VERSION ""

NS_ :

BS_:

BU_: RRSRR_FO LRSRR_FO CIPM_FO _DOFIMU2_FO _DOFIMU1_FO DMS_FO AMM_FO EOCM2B_IMX6_FO EOCM2B_K2_FO EOCM2B_K1_FO EOCM2A_IMX6_FO EOCM2A_K2_FO EOCM2A_K1_FO NVS_FO Dummy_FO TestTool_FO LRR_FO RFSRR_FO LFSRR_FO RSRR_FO VIS_FO EOCM_F_FO VIS2_FO

BO_ 774 F_Vehicle_Path_Estimate: 8 EOCM_F_FO
 SG_ Vpath_RollingCount : 7|2@0+ (1,0) [0|3] ""  CIPM_FO,AMM_FO,EOCM2B_IMX6_FO,EOCM2B_K2_FO,EOCM2B_K1_FO,VIS2_FO,RRSRR_FO,VIS_FO,RSRR_FO,RFSRR_FO,LRR_FO,LFSRR_FO
 SG_ Vpath_TrnCtrLngOfstV : 1|1@0+ (1,0) [0|1] ""  CIPM_FO,AMM_FO,EOCM2B_IMX6_FO,EOCM2B_K2_FO,EOCM2B_K1_FO,VIS2_FO,RRSRR_FO,LRR_FO,VIS_FO,RSRR_FO,RFSRR_FO,LFSRR_FO
 SG_ Vpath_Checksum : 50|11@0+ (1,0) [0|2047] ""  CIPM_FO,AMM_FO,EOCM2B_IMX6_FO,EOCM2B_K2_FO,EOCM2B_K1_FO,VIS2_FO,RRSRR_FO,VIS_FO,RSRR_FO,RFSRR_FO,LRR_FO,LFSRR_FO
 SG_ Vpath_TrnCtrLngOfst : 15|8@0- (0.1,0) [-12.8|12.7] "m"  CIPM_FO,AMM_FO,EOCM2B_IMX6_FO,EOCM2B_K2_FO,EOCM2B_K1_FO,VIS2_FO,RRSRR_FO,LRR_FO,VIS_FO,RSRR_FO,RFSRR_FO,LFSRR_FO
 SG_ Vpath_TrnCtrLatOfst : 21|14@0- (1,0) [-8192|8191] "m"  CIPM_FO,AMM_FO,EOCM2B_IMX6_FO,EOCM2B_K2_FO,EOCM2B_K1_FO,VIS2_FO,RRSRR_FO,LRR_FO,VIS_FO,RSRR_FO,RFSRR_FO,LFSRR_FO
 SG_ Vpath_Curvature : 39|16@0- (1E-005,0) [-0.32768|0.32767] "1/m"  CIPM_FO,AMM_FO,EOCM2B_IMX6_FO,EOCM2B_K2_FO,EOCM2B_K1_FO,VIS2_FO,RRSRR_FO,VIS_FO,RSRR_FO,RFSRR_FO,LRR_FO,LFSRR_FO
 SG_ Vpath_CurvatureV : 0|1@0+ (1,0) [0|1] ""  CIPM_FO,AMM_FO,EOCM2B_IMX6_FO,EOCM2B_K2_FO,EOCM2B_K1_FO,VIS2_FO,RRSRR_FO,VIS_FO,LRR_FO,RSRR_FO,RFSRR_FO,LFSRR_FO

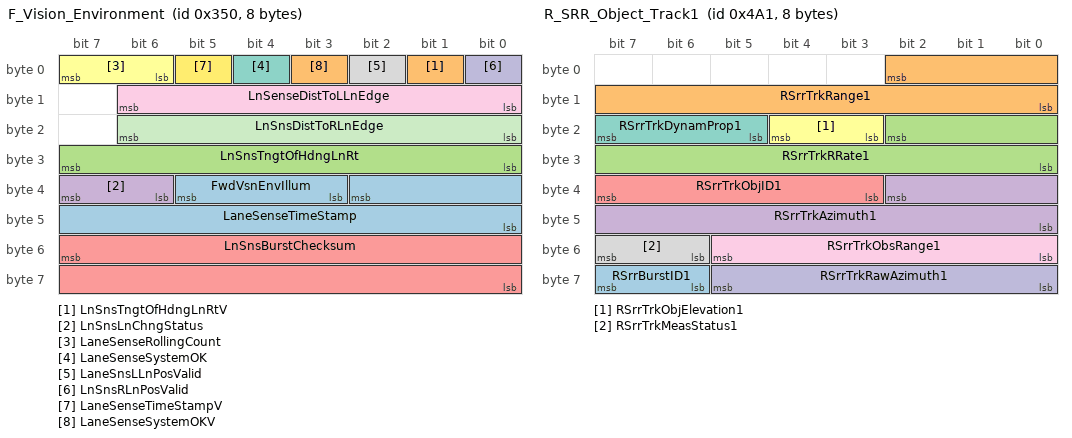
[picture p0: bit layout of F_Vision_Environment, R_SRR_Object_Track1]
BO_ 848 F_Vision_Environment: 8 VIS_FO
 SG_ FwdVsnEnvIllum : 37|3@0+ (1,0) [0|7] ""  EOCM2A_IMX6_FO,EOCM2A_K2_FO,EOCM2A_K1_FO,EOCM2B_IMX6_FO,EOCM2B_K2_FO,EOCM2B_K1_FO,EOCM_F_FO
 SG_ LnSnsTngtOfHdngLnRtV : 1|1@0+ (1,0) [0|1] ""  EOCM2A_IMX6_FO,EOCM2A_K2_FO,EOCM2A_K1_FO,EOCM2B_IMX6_FO,EOCM2B_K2_FO,EOCM2B_K1_FO,EOCM_F_FO
 SG_ LnSnsTngtOfHdngLnRt : 31|8@0- (0.002,0) [-0.256|0.254] "m/m"  EOCM2A_IMX6_FO,EOCM2A_K2_FO,EOCM2A_K1_FO,EOCM2B_IMX6_FO,EOCM2B_K2_FO,EOCM2B_K1_FO,EOCM_F_FO
 SG_ LnSnsLnChngStatus : 39|2@0+ (1,0) [0|3] ""  EOCM2A_IMX6_FO,EOCM2A_K2_FO,EOCM2A_K1_FO,EOCM2B_IMX6_FO,EOCM2B_K2_FO,EOCM2B_K1_FO,EOCM_F_FO
 SG_ LnSnsBurstChecksum : 55|16@0+ (1,0) [0|65535] ""  EOCM2A_IMX6_FO,EOCM2A_K2_FO,EOCM2A_K1_FO,EOCM2B_IMX6_FO,EOCM2B_K2_FO,EOCM2B_K1_FO,EOCM_F_FO
 SG_ LaneSenseRollingCount : 7|2@0+ (1,0) [0|3] ""  EOCM2A_IMX6_FO,EOCM2A_K2_FO,EOCM2A_K1_FO,EOCM2B_IMX6_FO,EOCM2B_K2_FO,EOCM2B_K1_FO,EOCM_F_FO
 SG_ LaneSenseSystemOK : 4|1@0+ (1,0) [0|1] ""  EOCM2A_IMX6_FO,EOCM2A_K2_FO,EOCM2A_K1_FO,EOCM2B_IMX6_FO,EOCM2B_K2_FO,EOCM2B_K1_FO,EOCM_F_FO
 SG_ LaneSnsLLnPosValid : 2|1@0+ (1,0) [0|1] ""  EOCM2A_IMX6_FO,EOCM2A_K2_FO,EOCM2A_K1_FO,EOCM2B_IMX6_FO,EOCM2B_K2_FO,EOCM2B_K1_FO,EOCM_F_FO
 SG_ LnSenseDistToLLnEdge : 14|7@0+ (0.05,0) [0|6.35] "m"  EOCM2A_IMX6_FO,EOCM2A_K2_FO,EOCM2A_K1_FO,EOCM2B_IMX6_FO,EOCM2B_K2_FO,EOCM2B_K1_FO,EOCM_F_FO
 SG_ LnSnsRLnPosValid : 0|1@0+ (1,0) [0|1] ""  EOCM2A_IMX6_FO,EOCM2A_K2_FO,EOCM2A_K1_FO,EOCM2B_IMX6_FO,EOCM2B_K2_FO,EOCM2B_K1_FO,EOCM_F_FO
 SG_ LnSnsDistToRLnEdge : 22|7@0+ (0.05,0) [0|6.35] "m"  EOCM2A_IMX6_FO,EOCM2A_K2_FO,EOCM2A_K1_FO,EOCM2B_IMX6_FO,EOCM2B_K2_FO,EOCM2B_K1_FO,EOCM_F_FO
 SG_ LaneSenseTimeStampV : 5|1@0+ (1,0) [0|1] ""  EOCM2A_IMX6_FO,EOCM2A_K2_FO,EOCM2A_K1_FO,EOCM2B_IMX6_FO,EOCM2B_K2_FO,EOCM2B_K1_FO,EOCM_F_FO
 SG_ LaneSenseTimeStamp : 34|11@0+ (1,0) [0|2047] "ms"  EOCM2A_IMX6_FO,EOCM2A_K2_FO,EOCM2A_K1_FO,EOCM2B_IMX6_FO,EOCM2B_K2_FO,EOCM2B_K1_FO,EOCM_F_FO
 SG_ LaneSenseSystemOKV : 3|1@0+ (1,0) [0|1] ""  EOCM2A_IMX6_FO,EOCM2A_K2_FO,EOCM2A_K1_FO,EOCM2B_IMX6_FO,EOCM2B_K2_FO,EOCM2B_K1_FO,EOCM_F_FO

BO_ 849 F_Vision_Environment_2: 8 VIS_FO
 SG_ LnSnsLatVRelToRgtMrkg : 23|8@0- (0.02,0) [-2.56|2.54] "m/s"  EOCM2A_IMX6_FO,EOCM2A_K2_FO,EOCM2A_K1_FO,EOCM_F_FO,EOCM2B_IMX6_FO,EOCM2B_K2_FO,EOCM2B_K1_FO
 SG_ LnSnsRtLnMrkgTypChgDst : 61|4@0+ (10,0) [0|150] "m"  EOCM2A_IMX6_FO,EOCM2A_K2_FO,EOCM2A_K1_FO,EOCM2B_IMX6_FO,EOCM2B_K2_FO,EOCM2B_K1_FO,EOCM_F_FO
 SG_ LnSnsCrvtGrdntRtV : 63|1@0+ (1,0) [0|1] ""  EOCM2A_IMX6_FO,EOCM2A_K2_FO,EOCM2A_K1_FO,EOCM2B_IMX6_FO,EOCM2B_K2_FO,EOCM2B_K1_FO,EOCM_F_FO
 SG_ LnSnsLnMrkgWdthRt : 62|1@0+ (1,0) [0|1] ""  EOCM2A_IMX6_FO,EOCM2A_K2_FO,EOCM2A_K1_FO,EOCM2B_IMX6_FO,EOCM2B_K2_FO,EOCM2B_K1_FO,EOCM_F_FO
 SG_ LnSnsRtAnchrLn : 57|1@0+ (1,0) [0|1] ""  EOCM2A_IMX6_FO,EOCM2A_K2_FO,EOCM2A_K1_FO,EOCM2B_IMX6_FO,EOCM2B_K2_FO,EOCM2B_K1_FO,EOCM_F_FO
 SG_ LnSnsLtAnchrLn : 56|1@0+ (1,0) [0|1] ""  EOCM2A_IMX6_FO,EOCM2A_K2_FO,EOCM2A_K1_FO,EOCM2B_IMX6_FO,EOCM2B_K2_FO,EOCM2B_K1_FO,EOCM_F_FO
 SG_ LnSnsLnCrvtrRghtV : 0|1@0+ (1,0) [0|1] ""  EOCM2A_IMX6_FO,EOCM2A_K2_FO,EOCM2A_K1_FO,EOCM2B_IMX6_FO,EOCM2B_K2_FO,EOCM2B_K1_FO,EOCM_F_FO
 SG_ LnSnsLnCrvtrRght : 47|16@0- (9.53E-007,0) [-0.031227904|0.031226951] "1/m"  EOCM2A_IMX6_FO,EOCM2A_K2_FO,EOCM2A_K1_FO,EOCM2B_IMX6_FO,EOCM2B_K2_FO,EOCM2B_K1_FO,EOCM_F_FO
 SG_ LnSnsCrvtGrdntRt : 31|16@0- (5.96E-008,0) [-0.0019529728|0.0019529132] "1/rad/s"  EOCM2A_IMX6_FO,EOCM2A_K2_FO,EOCM2A_K1_FO,EOCM2B_IMX6_FO,EOCM2B_K2_FO,EOCM2B_K1_FO,EOCM_F_FO
 SG_ LnSnsBurstID : 2|2@0+ (1,0) [0|3] ""  EOCM2A_IMX6_FO,EOCM2A_K2_FO,EOCM2A_K1_FO,EOCM2B_IMX6_FO,EOCM2B_K2_FO,EOCM2B_K1_FO,EOCM_F_FO
 SG_ LnSnsLatVRelToLftMrkg : 15|8@0- (0.02,0) [-2.56|2.54] "m/s"  EOCM2A_IMX6_FO,EOCM2A_K2_FO,EOCM2A_K1_FO,EOCM2B_IMX6_FO,EOCM2B_K2_FO,EOCM2B_K1_FO,EOCM_F_FO

BO_ 1184 R_SRR_Object_Header: 8 RSRR_FO
 SG_ RSRRNumValidTargets : 14|4@0+ (1,0) [0|15] ""  EOCM_F_FO
 SG_ RSrrRollingCnt : 1|2@0+ (1,0) [0|3] ""  EOCM_F_FO
 SG_ RSRRModeCmdFdbk : 4|3@0+ (1,0) [0|7] ""  EOCM_F_FO
 SG_ RSrrTimeStampV : 15|1@0+ (1,0) [0|1] ""  EOCM_F_FO
 SG_ RSrrTimeStamp : 10|11@0+ (1,0) [0|2047] "ms"  EOCM_F_FO
 SG_ RSrrBurstChecksum : 55|16@0+ (1,0) [0|65535] ""  EOCM_F_FO
 SG_ RSRRSnstvFltPrsntInt : 24|1@0+ (1,0) [0|1] ""  EOCM_F_FO
 SG_ RSRRPlntAlgnInProc : 37|1@0+ (1,0) [0|1] ""  EOCM_F_FO
 SG_ RSRRMsalgnYawRt : 47|1@0+ (1,0) [0|1] ""  EOCM_F_FO
 SG_ RSRRMsalgnYawLt : 46|1@0+ (1,0) [0|1] ""  EOCM_F_FO
 SG_ RSRRMsalgnRllRt : 35|1@0+ (1,0) [0|1] ""  EOCM_F_FO
 SG_ RSRRMsalgnRllLt : 34|1@0+ (1,0) [0|1] ""  EOCM_F_FO
 SG_ RSRRMsalgnPtchUp : 32|1@0+ (1,0) [0|1] ""  EOCM_F_FO
 SG_ RSRRMsalgnPtchDn : 33|1@0+ (1,0) [0|1] ""  EOCM_F_FO
 SG_ RSRRInitDiagCmplt : 40|1@0+ (1,0) [0|1] ""  EOCM_F_FO
 SG_ RSRRHWFltPrsntInt : 25|1@0+ (1,0) [0|1] ""  EOCM_F_FO
 SG_ RSRRExtIntrfrnc : 36|1@0+ (1,0) [0|1] ""  EOCM_F_FO
 SG_ RSRRDiagSpare : 30|1@0+ (1,0) [0|1] ""  EOCM_F_FO
 SG_ RSRRCANSgnlSpvFld : 29|1@0+ (1,0) [0|1] ""  EOCM_F_FO
 SG_ RSRRCANRxErr : 28|1@0+ (1,0) [0|1] ""  EOCM_F_FO
 SG_ RSRRCANIDAddrsUnsbl : 27|1@0+ (1,0) [0|1] ""  EOCM_F_FO
 SG_ RSRRAntTngFltPrsnt : 26|1@0+ (1,0) [0|1] ""  EOCM_F_FO
 SG_ RSRRAmbTmpOutRngLw : 42|1@0+ (1,0) [0|1] ""  EOCM_F_FO
 SG_ RSRRAmbTmpOutRngHi : 41|1@0+ (1,0) [0|1] ""  EOCM_F_FO
 SG_ RSRRAlgnFltPrsnt : 39|1@0+ (1,0) [0|1] ""  EOCM_F_FO
 SG_ RSRRVltgOutRngLo : 44|1@0+ (1,0) [0|1] ""  EOCM_F_FO
 SG_ RSRRVltgOutRngHi : 43|1@0+ (1,0) [0|1] ""  EOCM_F_FO
 SG_ RSRRSvcAlgnInPrcs : 38|1@0+ (1,0) [0|1] ""  EOCM_F_FO
 SG_ RSRRSnsrBlckd : 45|1@0+ (1,0) [0|1] ""  EOCM_F_FO

BO_ 1185 R_SRR_Object_Track1: 8 RSRR_FO
 SG_ RSrrBurstID1 : 63|2@0+ (1,0) [0|3] ""  EOCM_F_FO
 SG_ RSrrTrkRange1 : 2|11@0+ (0.02,0) [0|40.94] "m"  EOCM_F_FO
 SG_ RSrrTrkRRate1 : 18|11@0- (0.125,0) [-128|127.875] "m/s"  EOCM_F_FO
 SG_ RSrrTrkAzimuth1 : 34|11@0- (0.125,0) [-128|127.875] "deg"  EOCM_F_FO
 SG_ RSrrTrkObjID1 : 39|5@0+ (1,0) [0|31] ""  EOCM_F_FO
 SG_ RSrrTrkObjElevation1 : 20|2@0+ (1,0) [0|3] ""  EOCM_F_FO
 SG_ RSrrTrkDynamProp1 : 23|3@0+ (1,0) [0|7] ""  EOCM_F_FO
 SG_ RSrrTrkMeasStatus1 : 55|2@0+ (1,0) [0|3] ""  EOCM_F_FO
 SG_ RSrrTrkObsRange1 : 53|6@0- (0.02,0) [-0.64|0.62] "m"  EOCM_F_FO
 SG_ RSrrTrkRawAzimuth1 : 61|6@0- (1,0) [-32|31] "deg"  EOCM_F_FO

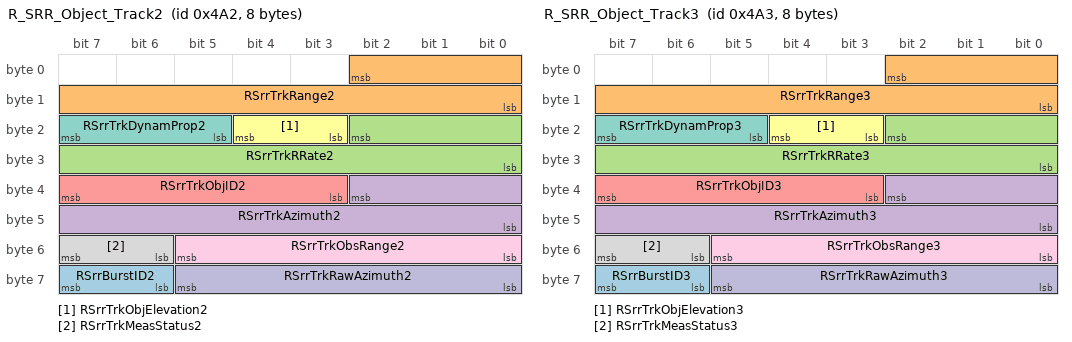
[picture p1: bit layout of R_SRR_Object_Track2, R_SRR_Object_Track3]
BO_ 1186 R_SRR_Object_Track2: 8 RSRR_FO
 SG_ RSrrBurstID2 : 63|2@0+ (1,0) [0|3] ""  EOCM_F_FO
 SG_ RSrrTrkRange2 : 2|11@0+ (0.02,0) [0|40.94] "m"  EOCM_F_FO
 SG_ RSrrTrkRRate2 : 18|11@0- (0.125,0) [-128|127.875] "m/s"  EOCM_F_FO
 SG_ RSrrTrkAzimuth2 : 34|11@0- (0.125,0) [-128|127.875] "deg"  EOCM_F_FO
 SG_ RSrrTrkObjID2 : 39|5@0+ (1,0) [0|31] ""  EOCM_F_FO
 SG_ RSrrTrkObjElevation2 : 20|2@0+ (1,0) [0|3] ""  EOCM_F_FO
 SG_ RSrrTrkDynamProp2 : 23|3@0+ (1,0) [0|7] ""  EOCM_F_FO
 SG_ RSrrTrkMeasStatus2 : 55|2@0+ (1,0) [0|3] ""  EOCM_F_FO
 SG_ RSrrTrkObsRange2 : 53|6@0- (0.02,0) [-0.64|0.62] "m"  EOCM_F_FO
 SG_ RSrrTrkRawAzimuth2 : 61|6@0- (1,0) [-32|31] "deg"  EOCM_F_FO

BO_ 1187 R_SRR_Object_Track3: 8 RSRR_FO
 SG_ RSrrBurstID3 : 63|2@0+ (1,0) [0|3] ""  EOCM_F_FO
 SG_ RSrrTrkRange3 : 2|11@0+ (0.02,0) [0|40.94] "m"  EOCM_F_FO
 SG_ RSrrTrkRRate3 : 18|11@0- (0.125,0) [-128|127.875] "m/s"  EOCM_F_FO
 SG_ RSrrTrkAzimuth3 : 34|11@0- (0.125,0) [-128|127.875] "deg"  EOCM_F_FO
 SG_ RSrrTrkObjID3 : 39|5@0+ (1,0) [0|31] ""  EOCM_F_FO
 SG_ RSrrTrkObjElevation3 : 20|2@0+ (1,0) [0|3] ""  EOCM_F_FO
 SG_ RSrrTrkDynamProp3 : 23|3@0+ (1,0) [0|7] ""  EOCM_F_FO
 SG_ RSrrTrkMeasStatus3 : 55|2@0+ (1,0) [0|3] ""  EOCM_F_FO
 SG_ RSrrTrkObsRange3 : 53|6@0- (0.02,0) [-0.64|0.62] "m"  EOCM_F_FO
 SG_ RSrrTrkRawAzimuth3 : 61|6@0- (1,0) [-32|31] "deg"  EOCM_F_FO

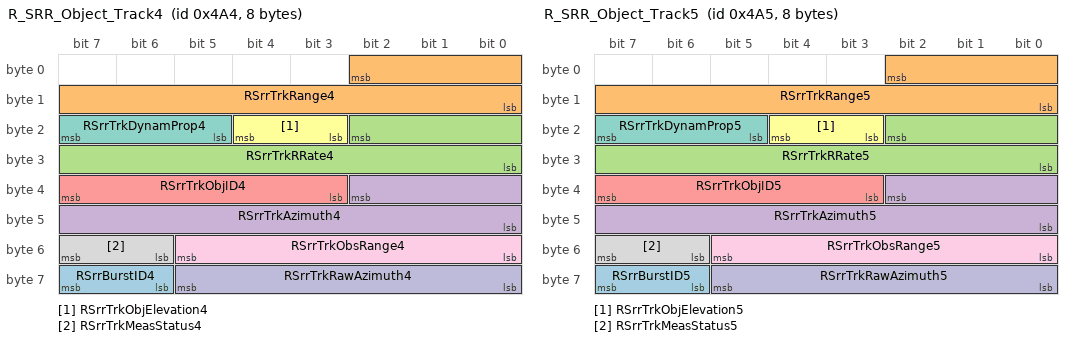
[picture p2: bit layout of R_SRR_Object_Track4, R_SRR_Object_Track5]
BO_ 1188 R_SRR_Object_Track4: 8 RSRR_FO
 SG_ RSrrBurstID4 : 63|2@0+ (1,0) [0|3] ""  EOCM_F_FO
 SG_ RSrrTrkRange4 : 2|11@0+ (0.02,0) [0|40.94] "m"  EOCM_F_FO
 SG_ RSrrTrkRRate4 : 18|11@0- (0.125,0) [-128|127.875] "m/s"  EOCM_F_FO
 SG_ RSrrTrkAzimuth4 : 34|11@0- (0.125,0) [-128|127.875] "deg"  EOCM_F_FO
 SG_ RSrrTrkObjID4 : 39|5@0+ (1,0) [0|31] ""  EOCM_F_FO
 SG_ RSrrTrkObjElevation4 : 20|2@0+ (1,0) [0|3] ""  EOCM_F_FO
 SG_ RSrrTrkDynamProp4 : 23|3@0+ (1,0) [0|7] ""  EOCM_F_FO
 SG_ RSrrTrkMeasStatus4 : 55|2@0+ (1,0) [0|3] ""  EOCM_F_FO
 SG_ RSrrTrkObsRange4 : 53|6@0- (0.02,0) [-0.64|0.62] "m"  EOCM_F_FO
 SG_ RSrrTrkRawAzimuth4 : 61|6@0- (1,0) [-32|31] "deg"  EOCM_F_FO

BO_ 1189 R_SRR_Object_Track5: 8 RSRR_FO
 SG_ RSrrBurstID5 : 63|2@0+ (1,0) [0|3] ""  EOCM_F_FO
 SG_ RSrrTrkRange5 : 2|11@0+ (0.02,0) [0|40.94] "m"  EOCM_F_FO
 SG_ RSrrTrkRRate5 : 18|11@0- (0.125,0) [-128|127.875] "m/s"  EOCM_F_FO
 SG_ RSrrTrkAzimuth5 : 34|11@0- (0.125,0) [-128|127.875] "deg"  EOCM_F_FO
 SG_ RSrrTrkObjID5 : 39|5@0+ (1,0) [0|31] ""  EOCM_F_FO
 SG_ RSrrTrkObjElevation5 : 20|2@0+ (1,0) [0|3] ""  EOCM_F_FO
 SG_ RSrrTrkDynamProp5 : 23|3@0+ (1,0) [0|7] ""  EOCM_F_FO
 SG_ RSrrTrkMeasStatus5 : 55|2@0+ (1,0) [0|3] ""  EOCM_F_FO
 SG_ RSrrTrkObsRange5 : 53|6@0- (0.02,0) [-0.64|0.62] "m"  EOCM_F_FO
 SG_ RSrrTrkRawAzimuth5 : 61|6@0- (1,0) [-32|31] "deg"  EOCM_F_FO

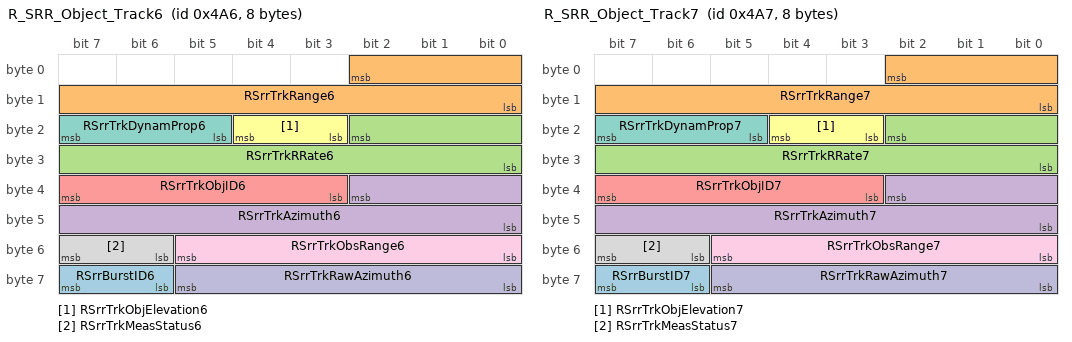
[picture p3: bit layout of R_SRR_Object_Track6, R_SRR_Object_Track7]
BO_ 1190 R_SRR_Object_Track6: 8 RSRR_FO
 SG_ RSrrBurstID6 : 63|2@0+ (1,0) [0|3] ""  EOCM_F_FO
 SG_ RSrrTrkRange6 : 2|11@0+ (0.02,0) [0|40.94] "m"  EOCM_F_FO
 SG_ RSrrTrkRRate6 : 18|11@0- (0.125,0) [-128|127.875] "m/s"  EOCM_F_FO
 SG_ RSrrTrkAzimuth6 : 34|11@0- (0.125,0) [-128|127.875] "deg"  EOCM_F_FO
 SG_ RSrrTrkObjID6 : 39|5@0+ (1,0) [0|31] ""  EOCM_F_FO
 SG_ RSrrTrkObjElevation6 : 20|2@0+ (1,0) [0|3] ""  EOCM_F_FO
 SG_ RSrrTrkDynamProp6 : 23|3@0+ (1,0) [0|7] ""  EOCM_F_FO
 SG_ RSrrTrkMeasStatus6 : 55|2@0+ (1,0) [0|3] ""  EOCM_F_FO
 SG_ RSrrTrkObsRange6 : 53|6@0- (0.02,0) [-0.64|0.62] "m"  EOCM_F_FO
 SG_ RSrrTrkRawAzimuth6 : 61|6@0- (1,0) [-32|31] "deg"  EOCM_F_FO

BO_ 1191 R_SRR_Object_Track7: 8 RSRR_FO
 SG_ RSrrBurstID7 : 63|2@0+ (1,0) [0|3] ""  EOCM_F_FO
 SG_ RSrrTrkRange7 : 2|11@0+ (0.02,0) [0|40.94] "m"  EOCM_F_FO
 SG_ RSrrTrkRRate7 : 18|11@0- (0.125,0) [-128|127.875] "m/s"  EOCM_F_FO
 SG_ RSrrTrkAzimuth7 : 34|11@0- (0.125,0) [-128|127.875] "deg"  EOCM_F_FO
 SG_ RSrrTrkObjID7 : 39|5@0+ (1,0) [0|31] ""  EOCM_F_FO
 SG_ RSrrTrkObjElevation7 : 20|2@0+ (1,0) [0|3] ""  EOCM_F_FO
 SG_ RSrrTrkDynamProp7 : 23|3@0+ (1,0) [0|7] ""  EOCM_F_FO
 SG_ RSrrTrkMeasStatus7 : 55|2@0+ (1,0) [0|3] ""  EOCM_F_FO
 SG_ RSrrTrkObsRange7 : 53|6@0- (0.02,0) [-0.64|0.62] "m"  EOCM_F_FO
 SG_ RSrrTrkRawAzimuth7 : 61|6@0- (1,0) [-32|31] "deg"  EOCM_F_FO

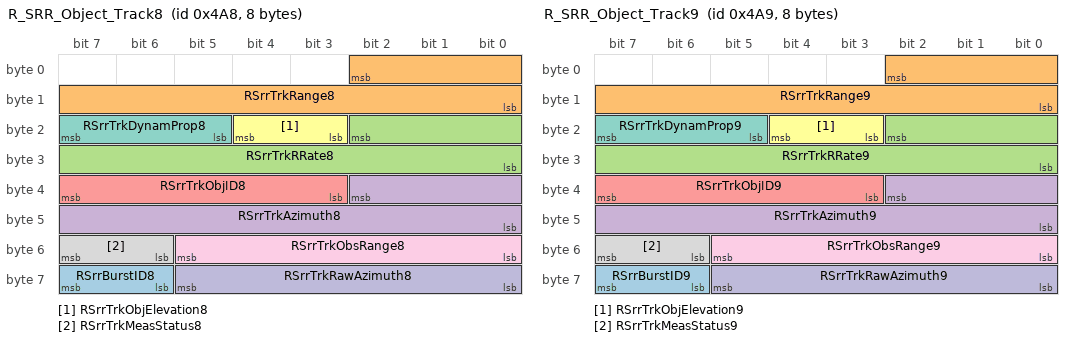
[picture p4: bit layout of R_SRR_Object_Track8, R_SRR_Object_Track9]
BO_ 1192 R_SRR_Object_Track8: 8 RSRR_FO
 SG_ RSrrBurstID8 : 63|2@0+ (1,0) [0|3] ""  EOCM_F_FO
 SG_ RSrrTrkRange8 : 2|11@0+ (0.02,0) [0|40.94] "m"  EOCM_F_FO
 SG_ RSrrTrkRRate8 : 18|11@0- (0.125,0) [-128|127.875] "m/s"  EOCM_F_FO
 SG_ RSrrTrkAzimuth8 : 34|11@0- (0.125,0) [-128|127.875] "deg"  EOCM_F_FO
 SG_ RSrrTrkObjID8 : 39|5@0+ (1,0) [0|31] ""  EOCM_F_FO
 SG_ RSrrTrkObjElevation8 : 20|2@0+ (1,0) [0|3] ""  EOCM_F_FO
 SG_ RSrrTrkDynamProp8 : 23|3@0+ (1,0) [0|7] ""  EOCM_F_FO
 SG_ RSrrTrkMeasStatus8 : 55|2@0+ (1,0) [0|3] ""  EOCM_F_FO
 SG_ RSrrTrkObsRange8 : 53|6@0- (0.02,0) [-0.64|0.62] "m"  EOCM_F_FO
 SG_ RSrrTrkRawAzimuth8 : 61|6@0- (1,0) [-32|31] "deg"  EOCM_F_FO

BO_ 1193 R_SRR_Object_Track9: 8 RSRR_FO
 SG_ RSrrBurstID9 : 63|2@0+ (1,0) [0|3] ""  EOCM_F_FO
 SG_ RSrrTrkRange9 : 2|11@0+ (0.02,0) [0|40.94] "m"  EOCM_F_FO
 SG_ RSrrTrkRRate9 : 18|11@0- (0.125,0) [-128|127.875] "m/s"  EOCM_F_FO
 SG_ RSrrTrkAzimuth9 : 34|11@0- (0.125,0) [-128|127.875] "deg"  EOCM_F_FO
 SG_ RSrrTrkObjID9 : 39|5@0+ (1,0) [0|31] ""  EOCM_F_FO
 SG_ RSrrTrkObjElevation9 : 20|2@0+ (1,0) [0|3] ""  EOCM_F_FO
 SG_ RSrrTrkDynamProp9 : 23|3@0+ (1,0) [0|7] ""  EOCM_F_FO
 SG_ RSrrTrkMeasStatus9 : 55|2@0+ (1,0) [0|3] ""  EOCM_F_FO
 SG_ RSrrTrkObsRange9 : 53|6@0- (0.02,0) [-0.64|0.62] "m"  EOCM_F_FO
 SG_ RSrrTrkRawAzimuth9 : 61|6@0- (1,0) [-32|31] "deg"  EOCM_F_FO

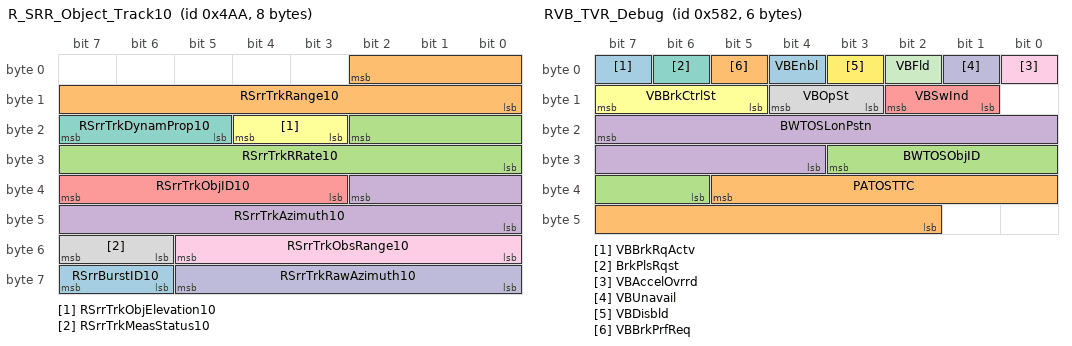
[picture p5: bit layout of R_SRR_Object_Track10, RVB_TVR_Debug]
BO_ 1194 R_SRR_Object_Track10: 8 RSRR_FO
 SG_ RSrrBurstID10 : 63|2@0+ (1,0) [0|3] ""  EOCM_F_FO
 SG_ RSrrTrkRange10 : 2|11@0+ (0.02,0) [0|40.94] "m"  EOCM_F_FO
 SG_ RSrrTrkRRate10 : 18|11@0- (0.125,0) [-128|127.875] "m/s"  EOCM_F_FO
 SG_ RSrrTrkAzimuth10 : 34|11@0- (0.125,0) [-128|127.875] "deg"  EOCM_F_FO
 SG_ RSrrTrkObjID10 : 39|5@0+ (1,0) [0|31] ""  EOCM_F_FO
 SG_ RSrrTrkObjElevation10 : 20|2@0+ (1,0) [0|3] ""  EOCM_F_FO
 SG_ RSrrTrkDynamProp10 : 23|3@0+ (1,0) [0|7] ""  EOCM_F_FO
 SG_ RSrrTrkMeasStatus10 : 55|2@0+ (1,0) [0|3] ""  EOCM_F_FO
 SG_ RSrrTrkObsRange10 : 53|6@0- (0.02,0) [-0.64|0.62] "m"  EOCM_F_FO
 SG_ RSrrTrkRawAzimuth10 : 61|6@0- (1,0) [-32|31] "deg"  EOCM_F_FO

BO_ 1410 RVB_TVR_Debug: 6 EOCM_F_FO
 SG_ VBBrkRqActv : 7|1@0+ (1,0) [0|1] ""  Dummy_FO
 SG_ PATOSTTC : 37|12@0+ (0.025,0) [0|102.375] "s"  Dummy_FO
 SG_ BWTOSObjID : 27|6@0+ (1,0) [0|63] ""  Dummy_FO
 SG_ BWTOSLonPstn : 23|12@0- (0.125,0) [-256|255.875] "m"  Dummy_FO
 SG_ VBSwInd : 10|2@0+ (1,0) [0|3] ""  Dummy_FO
 SG_ VBBrkCtrlSt : 15|3@0+ (1,0) [0|7] ""  Dummy_FO
 SG_ BrkPlsRqst : 6|1@0+ (1,0) [0|1] ""  Dummy_FO
 SG_ VBOpSt : 12|2@0+ (1,0) [0|3] ""  Dummy_FO
 SG_ VBAccelOvrrd : 0|1@0+ (1,0) [0|1] ""  Dummy_FO
 SG_ VBUnavail : 1|1@0+ (1,0) [0|1] ""  Dummy_FO
 SG_ VBFld : 2|1@0+ (1,0) [0|1] ""  Dummy_FO
 SG_ VBDisbld : 3|1@0+ (1,0) [0|1] ""  Dummy_FO
 SG_ VBEnbl : 4|1@0+ (1,0) [0|1] ""  Dummy_FO
 SG_ VBBrkPrfReq : 5|1@0+ (1,0) [0|1] ""  Dummy_FO

BO_ 1216 LF_SRR_Object_Header: 8 LFSRR_FO
 SG_ LFSRRNumValidTargets : 14|4@0+ (1,0) [0|15] ""  EOCM_F_FO
 SG_ LFSrrRollingCnt : 1|2@0+ (1,0) [0|3] ""  EOCM_F_FO
 SG_ LFSRRModeCmdFdbk : 4|3@0+ (1,0) [0|7] ""  EOCM_F_FO
 SG_ LFSrrTimeStampV : 15|1@0+ (1,0) [0|1] ""  EOCM_F_FO
 SG_ LFSrrTimeStamp : 10|11@0+ (1,0) [0|2047] "ms"  EOCM_F_FO
 SG_ LFSrrBurstChecksum : 55|16@0+ (1,0) [0|65535] ""  EOCM_F_FO
 SG_ LFSRRVltgOutRngLo : 44|1@0+ (1,0) [0|1] ""  EOCM_F_FO
 SG_ LFSRRVltgOutRngHi : 43|1@0+ (1,0) [0|1] ""  EOCM_F_FO
 SG_ LFSRRSvcAlgnInPrcs : 38|1@0+ (1,0) [0|1] ""  EOCM_F_FO
 SG_ LFSRRSnsrBlckd : 45|1@0+ (1,0) [0|1] ""  EOCM_F_FO
 SG_ LFSRRSnstvFltPrsntInt : 24|1@0+ (1,0) [0|1] ""  EOCM_F_FO
 SG_ LFSRRPlntAlgnInProc : 37|1@0+ (1,0) [0|1] ""  EOCM_F_FO
 SG_ LFSRRMsalgnYawRt : 47|1@0+ (1,0) [0|1] ""  EOCM_F_FO
 SG_ LFSRRMsalgnYawLt : 46|1@0+ (1,0) [0|1] ""  EOCM_F_FO
 SG_ LFSRRMsalgnRllRt : 35|1@0+ (1,0) [0|1] ""  EOCM_F_FO
 SG_ LFSRRMsalgnRllLt : 34|1@0+ (1,0) [0|1] ""  EOCM_F_FO
 SG_ LFSRRMsalgnPtchUp : 32|1@0+ (1,0) [0|1] ""  EOCM_F_FO
 SG_ LFSRRMsalgnPtchDn : 33|1@0+ (1,0) [0|1] ""  EOCM_F_FO
 SG_ LFSRRInitDiagCmplt : 40|1@0+ (1,0) [0|1] ""  EOCM_F_FO
 SG_ LFSRRHWFltPrsntInt : 25|1@0+ (1,0) [0|1] ""  EOCM_F_FO
 SG_ LFSRRExtIntrfrnc : 36|1@0+ (1,0) [0|1] ""  EOCM_F_FO
 SG_ LFSRRDiagSpare : 30|1@0+ (1,0) [0|1] ""  EOCM_F_FO
 SG_ LFSRRCANSgnlSpvFld : 29|1@0+ (1,0) [0|1] ""  EOCM_F_FO
 SG_ LFSRRCANRxErr : 28|1@0+ (1,0) [0|1] ""  EOCM_F_FO
 SG_ LFSRRCANIDAddrsUnsbl : 27|1@0+ (1,0) [0|1] ""  EOCM_F_FO
 SG_ LFSRRAntTngFltPrsnt : 26|1@0+ (1,0) [0|1] ""  EOCM_F_FO
 SG_ LFSRRAmbTmpOutRngLw : 42|1@0+ (1,0) [0|1] ""  EOCM_F_FO
 SG_ LFSRRAmbTmpOutRngHi : 41|1@0+ (1,0) [0|1] ""  EOCM_F_FO
 SG_ LFSRRAlgnFltPrsnt : 39|1@0+ (1,0) [0|1] ""  EOCM_F_FO

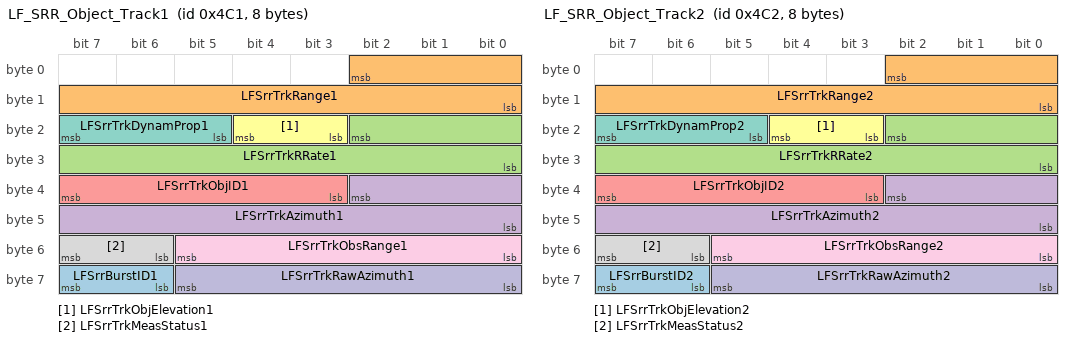
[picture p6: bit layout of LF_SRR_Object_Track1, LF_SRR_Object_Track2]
BO_ 1217 LF_SRR_Object_Track1: 8 LFSRR_FO
 SG_ LFSrrBurstID1 : 63|2@0+ (1,0) [0|3] ""  EOCM_F_FO
 SG_ LFSrrTrkRange1 : 2|11@0+ (0.02,0) [0|40.94] "m"  EOCM_F_FO
 SG_ LFSrrTrkRRate1 : 18|11@0- (0.125,0) [-128|127.875] "m/s"  EOCM_F_FO
 SG_ LFSrrTrkAzimuth1 : 34|11@0- (0.125,0) [-128|127.875] "deg"  EOCM_F_FO
 SG_ LFSrrTrkObjID1 : 39|5@0+ (1,0) [0|31] ""  EOCM_F_FO
 SG_ LFSrrTrkObjElevation1 : 20|2@0+ (1,0) [0|3] ""  EOCM_F_FO
 SG_ LFSrrTrkDynamProp1 : 23|3@0+ (1,0) [0|7] ""  EOCM_F_FO
 SG_ LFSrrTrkMeasStatus1 : 55|2@0+ (1,0) [0|3] ""  EOCM_F_FO
 SG_ LFSrrTrkObsRange1 : 53|6@0- (0.02,0) [-0.64|0.62] "m"  EOCM_F_FO
 SG_ LFSrrTrkRawAzimuth1 : 61|6@0- (1,0) [-32|31] "deg"  EOCM_F_FO

BO_ 1218 LF_SRR_Object_Track2: 8 LFSRR_FO
 SG_ LFSrrBurstID2 : 63|2@0+ (1,0) [0|3] ""  EOCM_F_FO
 SG_ LFSrrTrkRange2 : 2|11@0+ (0.02,0) [0|40.94] "m"  EOCM_F_FO
 SG_ LFSrrTrkRRate2 : 18|11@0- (0.125,0) [-128|127.875] "m/s"  EOCM_F_FO
 SG_ LFSrrTrkAzimuth2 : 34|11@0- (0.125,0) [-128|127.875] "deg"  EOCM_F_FO
 SG_ LFSrrTrkObjID2 : 39|5@0+ (1,0) [0|31] ""  EOCM_F_FO
 SG_ LFSrrTrkObjElevation2 : 20|2@0+ (1,0) [0|3] ""  EOCM_F_FO
 SG_ LFSrrTrkDynamProp2 : 23|3@0+ (1,0) [0|7] ""  EOCM_F_FO
 SG_ LFSrrTrkMeasStatus2 : 55|2@0+ (1,0) [0|3] ""  EOCM_F_FO
 SG_ LFSrrTrkObsRange2 : 53|6@0- (0.02,0) [-0.64|0.62] "m"  EOCM_F_FO
 SG_ LFSrrTrkRawAzimuth2 : 61|6@0- (1,0) [-32|31] "deg"  EOCM_F_FO

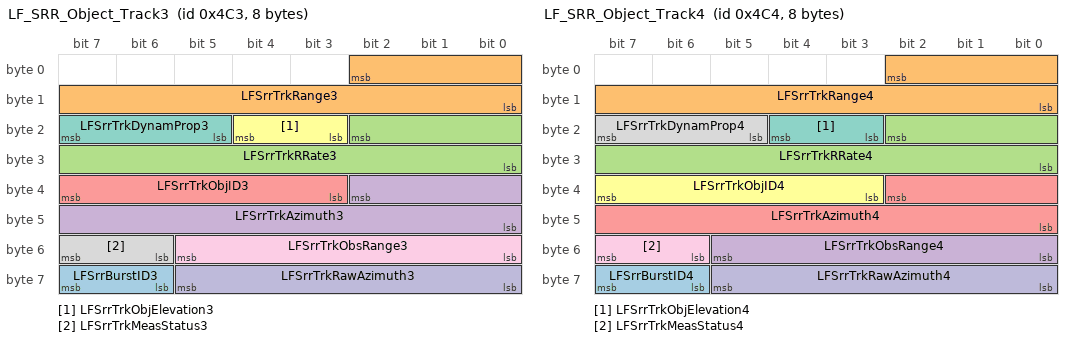
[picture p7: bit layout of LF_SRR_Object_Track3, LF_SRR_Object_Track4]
BO_ 1219 LF_SRR_Object_Track3: 8 LFSRR_FO
 SG_ LFSrrBurstID3 : 63|2@0+ (1,0) [0|3] ""  EOCM_F_FO
 SG_ LFSrrTrkRange3 : 2|11@0+ (0.02,0) [0|40.94] "m"  EOCM_F_FO
 SG_ LFSrrTrkRRate3 : 18|11@0- (0.125,0) [-128|127.875] "m/s"  EOCM_F_FO
 SG_ LFSrrTrkAzimuth3 : 34|11@0- (0.125,0) [-128|127.875] "deg"  EOCM_F_FO
 SG_ LFSrrTrkObjID3 : 39|5@0+ (1,0) [0|31] ""  EOCM_F_FO
 SG_ LFSrrTrkObjElevation3 : 20|2@0+ (1,0) [0|3] ""  EOCM_F_FO
 SG_ LFSrrTrkDynamProp3 : 23|3@0+ (1,0) [0|7] ""  EOCM_F_FO
 SG_ LFSrrTrkMeasStatus3 : 55|2@0+ (1,0) [0|3] ""  EOCM_F_FO
 SG_ LFSrrTrkObsRange3 : 53|6@0- (0.02,0) [-0.64|0.62] "m"  EOCM_F_FO
 SG_ LFSrrTrkRawAzimuth3 : 61|6@0- (1,0) [-32|31] "deg"  EOCM_F_FO

BO_ 1220 LF_SRR_Object_Track4: 8 LFSRR_FO
 SG_ LFSrrBurstID4 : 63|2@0+ (1,0) [0|3] ""  EOCM_F_FO
 SG_ LFSrrTrkRange4 : 2|11@0+ (0.02,0) [0|40.94] "m"  EOCM_F_FO
 SG_ LFSrrTrkRRate4 : 18|11@0- (0.125,0) [-128|127.875] "m/s"  EOCM_F_FO
 SG_ LFSrrTrkObsRange4 : 53|6@0- (0.02,0) [-0.64|0.62] "m"  EOCM_F_FO
 SG_ LFSrrTrkAzimuth4 : 34|11@0- (0.125,0) [-128|127.875] "deg"  EOCM_F_FO
 SG_ LFSrrTrkObjID4 : 39|5@0+ (1,0) [0|31] ""  EOCM_F_FO
 SG_ LFSrrTrkObjElevation4 : 20|2@0+ (1,0) [0|3] ""  EOCM_F_FO
 SG_ LFSrrTrkDynamProp4 : 23|3@0+ (1,0) [0|7] ""  EOCM_F_FO
 SG_ LFSrrTrkMeasStatus4 : 55|2@0+ (1,0) [0|3] ""  EOCM_F_FO
 SG_ LFSrrTrkRawAzimuth4 : 61|6@0- (1,0) [-32|31] "deg"  EOCM_F_FO

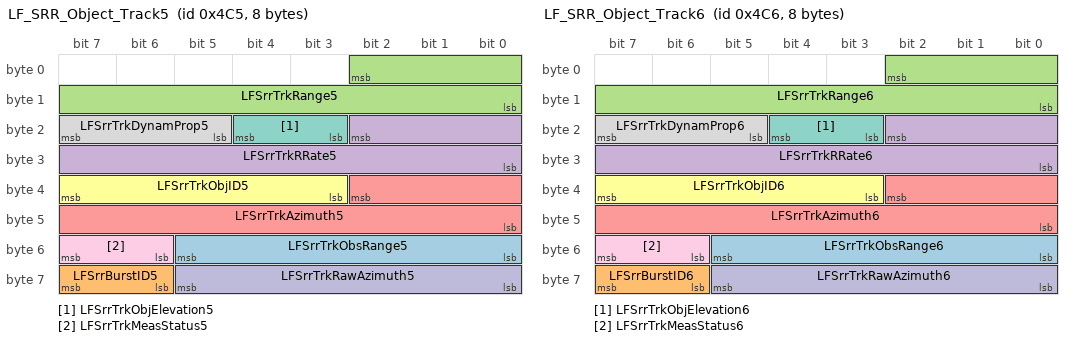
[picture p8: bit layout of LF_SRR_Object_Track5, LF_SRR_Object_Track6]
BO_ 1221 LF_SRR_Object_Track5: 8 LFSRR_FO
 SG_ LFSrrTrkObsRange5 : 53|6@0- (0.02,0) [-0.64|0.62] "m"  EOCM_F_FO
 SG_ LFSrrBurstID5 : 63|2@0+ (1,0) [0|3] ""  EOCM_F_FO
 SG_ LFSrrTrkRange5 : 2|11@0+ (0.02,0) [0|40.94] "m"  EOCM_F_FO
 SG_ LFSrrTrkRRate5 : 18|11@0- (0.125,0) [-128|127.875] "m/s"  EOCM_F_FO
 SG_ LFSrrTrkAzimuth5 : 34|11@0- (0.125,0) [-128|127.875] "deg"  EOCM_F_FO
 SG_ LFSrrTrkObjID5 : 39|5@0+ (1,0) [0|31] ""  EOCM_F_FO
 SG_ LFSrrTrkObjElevation5 : 20|2@0+ (1,0) [0|3] ""  EOCM_F_FO
 SG_ LFSrrTrkDynamProp5 : 23|3@0+ (1,0) [0|7] ""  EOCM_F_FO
 SG_ LFSrrTrkMeasStatus5 : 55|2@0+ (1,0) [0|3] ""  EOCM_F_FO
 SG_ LFSrrTrkRawAzimuth5 : 61|6@0- (1,0) [-32|31] "deg"  EOCM_F_FO

BO_ 1222 LF_SRR_Object_Track6: 8 LFSRR_FO
 SG_ LFSrrTrkObsRange6 : 53|6@0- (0.02,0) [-0.64|0.62] "m"  EOCM_F_FO
 SG_ LFSrrBurstID6 : 63|2@0+ (1,0) [0|3] ""  EOCM_F_FO
 SG_ LFSrrTrkRange6 : 2|11@0+ (0.02,0) [0|40.94] "m"  EOCM_F_FO
 SG_ LFSrrTrkRRate6 : 18|11@0- (0.125,0) [-128|127.875] "m/s"  EOCM_F_FO
 SG_ LFSrrTrkAzimuth6 : 34|11@0- (0.125,0) [-128|127.875] "deg"  EOCM_F_FO
 SG_ LFSrrTrkObjID6 : 39|5@0+ (1,0) [0|31] ""  EOCM_F_FO
 SG_ LFSrrTrkObjElevation6 : 20|2@0+ (1,0) [0|3] ""  EOCM_F_FO
 SG_ LFSrrTrkDynamProp6 : 23|3@0+ (1,0) [0|7] ""  EOCM_F_FO
 SG_ LFSrrTrkMeasStatus6 : 55|2@0+ (1,0) [0|3] ""  EOCM_F_FO
 SG_ LFSrrTrkRawAzimuth6 : 61|6@0- (1,0) [-32|31] "deg"  EOCM_F_FO

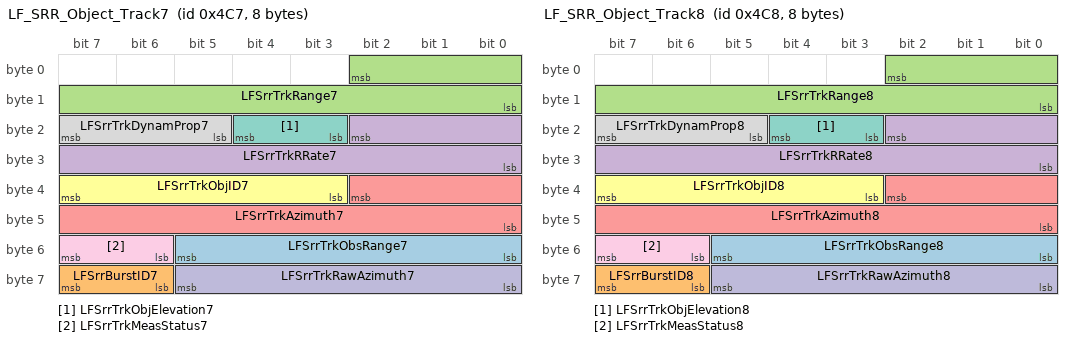
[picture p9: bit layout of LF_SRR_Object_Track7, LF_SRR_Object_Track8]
BO_ 1223 LF_SRR_Object_Track7: 8 LFSRR_FO
 SG_ LFSrrTrkObsRange7 : 53|6@0- (0.02,0) [-0.64|0.62] "m"  EOCM_F_FO
 SG_ LFSrrBurstID7 : 63|2@0+ (1,0) [0|3] ""  EOCM_F_FO
 SG_ LFSrrTrkRange7 : 2|11@0+ (0.02,0) [0|40.94] "m"  EOCM_F_FO
 SG_ LFSrrTrkRRate7 : 18|11@0- (0.125,0) [-128|127.875] "m/s"  EOCM_F_FO
 SG_ LFSrrTrkAzimuth7 : 34|11@0- (0.125,0) [-128|127.875] "deg"  EOCM_F_FO
 SG_ LFSrrTrkObjID7 : 39|5@0+ (1,0) [0|31] ""  EOCM_F_FO
 SG_ LFSrrTrkObjElevation7 : 20|2@0+ (1,0) [0|3] ""  EOCM_F_FO
 SG_ LFSrrTrkDynamProp7 : 23|3@0+ (1,0) [0|7] ""  EOCM_F_FO
 SG_ LFSrrTrkMeasStatus7 : 55|2@0+ (1,0) [0|3] ""  EOCM_F_FO
 SG_ LFSrrTrkRawAzimuth7 : 61|6@0- (1,0) [-32|31] "deg"  EOCM_F_FO

BO_ 1224 LF_SRR_Object_Track8: 8 LFSRR_FO
 SG_ LFSrrTrkObsRange8 : 53|6@0- (0.02,0) [-0.64|0.62] "m"  EOCM_F_FO
 SG_ LFSrrBurstID8 : 63|2@0+ (1,0) [0|3] ""  EOCM_F_FO
 SG_ LFSrrTrkRange8 : 2|11@0+ (0.02,0) [0|40.94] "m"  EOCM_F_FO
 SG_ LFSrrTrkRRate8 : 18|11@0- (0.125,0) [-128|127.875] "m/s"  EOCM_F_FO
 SG_ LFSrrTrkAzimuth8 : 34|11@0- (0.125,0) [-128|127.875] "deg"  EOCM_F_FO
 SG_ LFSrrTrkObjID8 : 39|5@0+ (1,0) [0|31] ""  EOCM_F_FO
 SG_ LFSrrTrkObjElevation8 : 20|2@0+ (1,0) [0|3] ""  EOCM_F_FO
 SG_ LFSrrTrkDynamProp8 : 23|3@0+ (1,0) [0|7] ""  EOCM_F_FO
 SG_ LFSrrTrkMeasStatus8 : 55|2@0+ (1,0) [0|3] ""  EOCM_F_FO
 SG_ LFSrrTrkRawAzimuth8 : 61|6@0- (1,0) [-32|31] "deg"  EOCM_F_FO

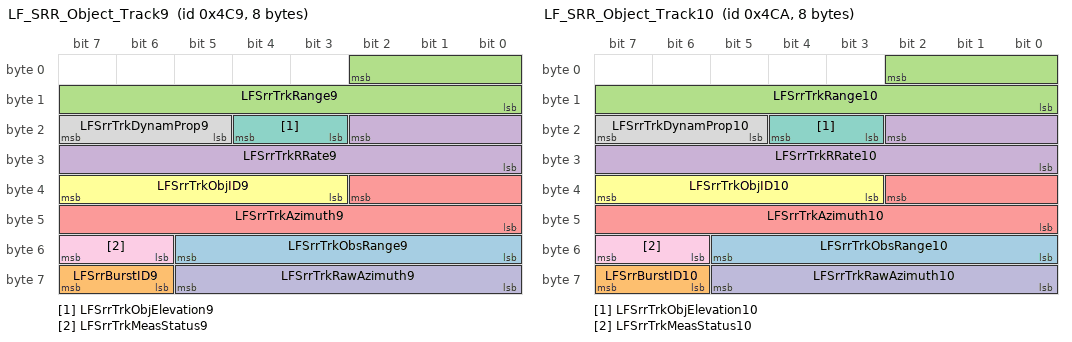
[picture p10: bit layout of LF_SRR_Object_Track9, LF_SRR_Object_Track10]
BO_ 1225 LF_SRR_Object_Track9: 8 LFSRR_FO
 SG_ LFSrrTrkObsRange9 : 53|6@0- (0.02,0) [-0.64|0.62] "m"  EOCM_F_FO
 SG_ LFSrrBurstID9 : 63|2@0+ (1,0) [0|3] ""  EOCM_F_FO
 SG_ LFSrrTrkRange9 : 2|11@0+ (0.02,0) [0|40.94] "m"  EOCM_F_FO
 SG_ LFSrrTrkRRate9 : 18|11@0- (0.125,0) [-128|127.875] "m/s"  EOCM_F_FO
 SG_ LFSrrTrkAzimuth9 : 34|11@0- (0.125,0) [-128|127.875] "deg"  EOCM_F_FO
 SG_ LFSrrTrkObjID9 : 39|5@0+ (1,0) [0|31] ""  EOCM_F_FO
 SG_ LFSrrTrkObjElevation9 : 20|2@0+ (1,0) [0|3] ""  EOCM_F_FO
 SG_ LFSrrTrkDynamProp9 : 23|3@0+ (1,0) [0|7] ""  EOCM_F_FO
 SG_ LFSrrTrkMeasStatus9 : 55|2@0+ (1,0) [0|3] ""  EOCM_F_FO
 SG_ LFSrrTrkRawAzimuth9 : 61|6@0- (1,0) [-32|31] "deg"  EOCM_F_FO

BO_ 1226 LF_SRR_Object_Track10: 8 LFSRR_FO
 SG_ LFSrrTrkObsRange10 : 53|6@0- (0.02,0) [-0.64|0.62] "m"  EOCM_F_FO
 SG_ LFSrrBurstID10 : 63|2@0+ (1,0) [0|3] ""  EOCM_F_FO
 SG_ LFSrrTrkRange10 : 2|11@0+ (0.02,0) [0|40.94] "m"  EOCM_F_FO
 SG_ LFSrrTrkRRate10 : 18|11@0- (0.125,0) [-128|127.875] "m/s"  EOCM_F_FO
 SG_ LFSrrTrkAzimuth10 : 34|11@0- (0.125,0) [-128|127.875] "deg"  EOCM_F_FO
 SG_ LFSrrTrkObjID10 : 39|5@0+ (1,0) [0|31] ""  EOCM_F_FO
 SG_ LFSrrTrkObjElevation10 : 20|2@0+ (1,0) [0|3] ""  EOCM_F_FO
 SG_ LFSrrTrkDynamProp10 : 23|3@0+ (1,0) [0|7] ""  EOCM_F_FO
 SG_ LFSrrTrkMeasStatus10 : 55|2@0+ (1,0) [0|3] ""  EOCM_F_FO
 SG_ LFSrrTrkRawAzimuth10 : 61|6@0- (1,0) [-32|31] "deg"  EOCM_F_FO

BO_ 1232 RF_SRR_Object_Header: 8 RFSRR_FO
 SG_ RFSRRVltgOutRngLo : 44|1@0+ (1,0) [0|1] ""  EOCM_F_FO
 SG_ RFSRRVltgOutRngHi : 43|1@0+ (1,0) [0|1] ""  EOCM_F_FO
 SG_ RFSRRSvcAlgnInPrcs : 38|1@0+ (1,0) [0|1] ""  EOCM_F_FO
 SG_ RFSRRSnsrBlckd : 45|1@0+ (1,0) [0|1] ""  EOCM_F_FO
 SG_ RFSRRSnstvFltPrsntInt : 24|1@0+ (1,0) [0|1] ""  EOCM_F_FO
 SG_ RFSRRPlntAlgnInProc : 37|1@0+ (1,0) [0|1] ""  EOCM_F_FO
 SG_ RFSRRMsalgnYawRt : 47|1@0+ (1,0) [0|1] ""  EOCM_F_FO
 SG_ RFSRRMsalgnYawLt : 46|1@0+ (1,0) [0|1] ""  EOCM_F_FO
 SG_ RFSRRMsalgnRllRt : 35|1@0+ (1,0) [0|1] ""  EOCM_F_FO
 SG_ RFSRRMsalgnRllLt : 34|1@0+ (1,0) [0|1] ""  EOCM_F_FO
 SG_ RFSRRMsalgnPtchUp : 32|1@0+ (1,0) [0|1] ""  EOCM_F_FO
 SG_ RFSRRMsalgnPtchDn : 33|1@0+ (1,0) [0|1] ""  EOCM_F_FO
 SG_ RFSRRInitDiagCmplt : 40|1@0+ (1,0) [0|1] ""  EOCM_F_FO
 SG_ RFSRRHWFltPrsntInt : 25|1@0+ (1,0) [0|1] ""  EOCM_F_FO
 SG_ RFSRRExtIntrfrnc : 36|1@0+ (1,0) [0|1] ""  EOCM_F_FO
 SG_ RFSRRDiagSpare : 30|1@0+ (1,0) [0|1] ""  EOCM_F_FO
 SG_ RFSRRCANSgnlSpvFld : 29|1@0+ (1,0) [0|1] ""  EOCM_F_FO
 SG_ RFSRRCANRxErr : 28|1@0+ (1,0) [0|1] ""  EOCM_F_FO
 SG_ RFSRRCANIDAddrsUnsbl : 27|1@0+ (1,0) [0|1] ""  EOCM_F_FO
 SG_ RFSRRAntTngFltPrsnt : 26|1@0+ (1,0) [0|1] ""  EOCM_F_FO
 SG_ RFSRRAmbTmpOutRngLw : 42|1@0+ (1,0) [0|1] ""  EOCM_F_FO
 SG_ RFSRRAmbTmpOutRngHi : 41|1@0+ (1,0) [0|1] ""  EOCM_F_FO
 SG_ RFSRRAlgnFltPrsnt : 39|1@0+ (1,0) [0|1] ""  EOCM_F_FO
 SG_ RFSRRNumValidTargets : 14|4@0+ (1,0) [0|15] ""  EOCM_F_FO
 SG_ RFSrrRollingCnt : 1|2@0+ (1,0) [0|3] ""  EOCM_F_FO
 SG_ RFSRRModeCmdFdbk : 4|3@0+ (1,0) [0|7] ""  EOCM_F_FO
 SG_ RFSrrTimeStamp : 10|11@0+ (1,0) [0|2047] "ms"  EOCM_F_FO
 SG_ RFSrrBurstChecksum : 55|16@0+ (1,0) [0|65535] ""  EOCM_F_FO
 SG_ RFSrrTimeStampV : 15|1@0+ (1,0) [0|1] ""  EOCM_F_FO

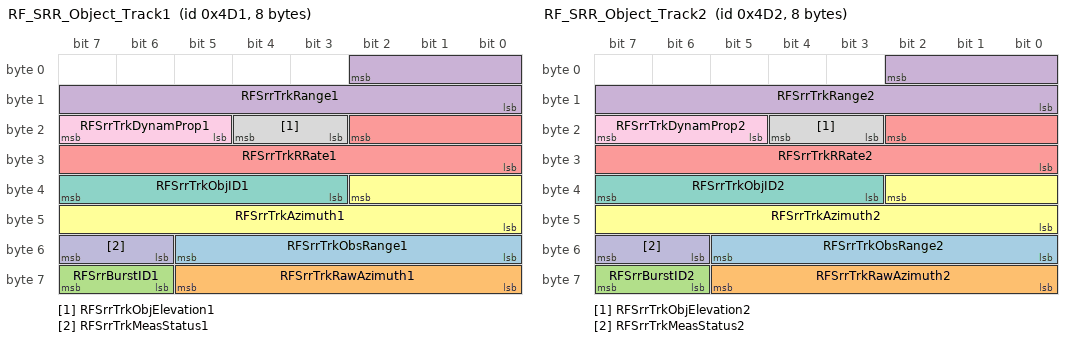
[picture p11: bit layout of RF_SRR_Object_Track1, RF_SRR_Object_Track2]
BO_ 1233 RF_SRR_Object_Track1: 8 RFSRR_FO
 SG_ RFSrrTrkObsRange1 : 53|6@0- (0.02,0) [-0.64|0.62] "m"  EOCM_F_FO
 SG_ RFSrrTrkRawAzimuth1 : 61|6@0- (1,0) [-32|31] "deg"  EOCM_F_FO
 SG_ RFSrrBurstID1 : 63|2@0+ (1,0) [0|3] ""  EOCM_F_FO
 SG_ RFSrrTrkRange1 : 2|11@0+ (0.02,0) [0|40.94] "m"  EOCM_F_FO
 SG_ RFSrrTrkRRate1 : 18|11@0- (0.125,0) [-128|127.875] "m/s"  EOCM_F_FO
 SG_ RFSrrTrkAzimuth1 : 34|11@0- (0.125,0) [-128|127.875] "deg"  EOCM_F_FO
 SG_ RFSrrTrkObjID1 : 39|5@0+ (1,0) [0|31] ""  EOCM_F_FO
 SG_ RFSrrTrkObjElevation1 : 20|2@0+ (1,0) [0|3] ""  EOCM_F_FO
 SG_ RFSrrTrkDynamProp1 : 23|3@0+ (1,0) [0|7] ""  EOCM_F_FO
 SG_ RFSrrTrkMeasStatus1 : 55|2@0+ (1,0) [0|3] ""  EOCM_F_FO

BO_ 1234 RF_SRR_Object_Track2: 8 RFSRR_FO
 SG_ RFSrrTrkObsRange2 : 53|6@0- (0.02,0) [-0.64|0.62] "m"  EOCM_F_FO
 SG_ RFSrrTrkRawAzimuth2 : 61|6@0- (1,0) [-32|31] "deg"  EOCM_F_FO
 SG_ RFSrrBurstID2 : 63|2@0+ (1,0) [0|3] ""  EOCM_F_FO
 SG_ RFSrrTrkRange2 : 2|11@0+ (0.02,0) [0|40.94] "m"  EOCM_F_FO
 SG_ RFSrrTrkRRate2 : 18|11@0- (0.125,0) [-128|127.875] "m/s"  EOCM_F_FO
 SG_ RFSrrTrkAzimuth2 : 34|11@0- (0.125,0) [-128|127.875] "deg"  EOCM_F_FO
 SG_ RFSrrTrkObjID2 : 39|5@0+ (1,0) [0|31] ""  EOCM_F_FO
 SG_ RFSrrTrkObjElevation2 : 20|2@0+ (1,0) [0|3] ""  EOCM_F_FO
 SG_ RFSrrTrkDynamProp2 : 23|3@0+ (1,0) [0|7] ""  EOCM_F_FO
 SG_ RFSrrTrkMeasStatus2 : 55|2@0+ (1,0) [0|3] ""  EOCM_F_FO

BO_ 1235 RF_SRR_Object_Track3: 8 RFSRR_FO
 SG_ RFSrrTrkObsRange3 : 53|6@0- (0.02,0) [-0.64|0.62] "m"  EOCM_F_FO
 SG_ RFSrrTrkRawAzimuth3 : 61|6@0- (1,0) [-32|31] "deg"  EOCM_F_FO
 SG_ RFSrrBurstID3 : 63|2@0+ (1,0) [0|3] ""  EOCM_F_FO
 SG_ RFSrrTrkRange3 : 2|11@0+ (0.02,0) [0|40.94] "m"  EOCM_F_FO
 SG_ RFSrrTrkRRate3 : 18|11@0- (0.125,0) [-128|127.875] "m/s"  EOCM_F_FO
 SG_ RFSrrTrkAzimuth3 : 34|11@0- (0.125,0) [-128|127.875] "deg"  EOCM_F_FO
 SG_ RFSrrTrkObjID3 : 39|5@0+ (1,0) [0|31] ""  EOCM_F_FO
 SG_ RFSrrTrkObjElevation3 : 20|2@0+ (1,0) [0|3] ""  EOCM_F_FO
 SG_ RFSrrTrkDynamProp3 : 23|3@0+ (1,0) [0|7] ""  EOCM_F_FO
 SG_ RFSrrTrkMeasStatus3 : 55|2@0+ (1,0) [0|3] ""  EOCM_F_FO

BO_ 1236 RF_SRR_Object_Track4: 8 RFSRR_FO
 SG_ RFSrrTrkObsRange4 : 53|6@0- (0.02,0) [-0.64|0.62] "m"  EOCM_F_FO
 SG_ RFSrrTrkRawAzimuth4 : 61|6@0- (1,0) [-32|31] "deg"  EOCM_F_FO
 SG_ RFSrrBurstID4 : 63|2@0+ (1,0) [0|3] ""  EOCM_F_FO
 SG_ RFSrrTrkRange4 : 2|11@0+ (0.02,0) [0|40.94] "m"  EOCM_F_FO
 SG_ RFSrrTrkRRate4 : 18|11@0- (0.125,0) [-128|127.875] "m/s"  EOCM_F_FO
 SG_ RFSrrTrkAzimuth4 : 34|11@0- (0.125,0) [-128|127.875] "deg"  EOCM_F_FO
 SG_ RFSrrTrkObjID4 : 39|5@0+ (1,0) [0|31] ""  EOCM_F_FO
 SG_ RFSrrTrkObjElevation4 : 20|2@0+ (1,0) [0|3] ""  EOCM_F_FO
 SG_ RFSrrTrkDynamProp4 : 23|3@0+ (1,0) [0|7] ""  EOCM_F_FO
 SG_ RFSrrTrkMeasStatus4 : 55|2@0+ (1,0) [0|3] ""  EOCM_F_FO

BO_ 1237 RF_SRR_Object_Track5: 8 RFSRR_FO
 SG_ RFSrrTrkObsRange5 : 53|6@0- (0.02,0) [-0.64|0.62] "m"  EOCM_F_FO
 SG_ RFSrrTrkRawAzimuth5 : 61|6@0- (1,0) [-32|31] "deg"  EOCM_F_FO
 SG_ RFSrrBurstID5 : 63|2@0+ (1,0) [0|3] ""  EOCM_F_FO
 SG_ RFSrrTrkRange5 : 2|11@0+ (0.02,0) [0|40.94] "m"  EOCM_F_FO
 SG_ RFSrrTrkRRate5 : 18|11@0- (0.125,0) [-128|127.875] "m/s"  EOCM_F_FO
 SG_ RFSrrTrkAzimuth5 : 34|11@0- (0.125,0) [-128|127.875] "deg"  EOCM_F_FO
 SG_ RFSrrTrkObjID5 : 39|5@0+ (1,0) [0|31] ""  EOCM_F_FO
 SG_ RFSrrTrkObjElevation5 : 20|2@0+ (1,0) [0|3] ""  EOCM_F_FO
 SG_ RFSrrTrkDynamProp5 : 23|3@0+ (1,0) [0|7] ""  EOCM_F_FO
 SG_ RFSrrTrkMeasStatus5 : 55|2@0+ (1,0) [0|3] ""  EOCM_F_FO

BO_ 1238 RF_SRR_Object_Track6: 8 RFSRR_FO
 SG_ RFSrrTrkObsRange6 : 53|6@0- (0.02,0) [-0.64|0.62] "m"  EOCM_F_FO
 SG_ RFSrrTrkRawAzimuth6 : 61|6@0- (1,0) [-32|31] "deg"  EOCM_F_FO
 SG_ RFSrrBurstID6 : 63|2@0+ (1,0) [0|3] ""  EOCM_F_FO
 SG_ RFSrrTrkRange6 : 2|11@0+ (0.02,0) [0|40.94] "m"  EOCM_F_FO
 SG_ RFSrrTrkRRate6 : 18|11@0- (0.125,0) [-128|127.875] "m/s"  EOCM_F_FO
 SG_ RFSrrTrkAzimuth6 : 34|11@0- (0.125,0) [-128|127.875] "deg"  EOCM_F_FO
 SG_ RFSrrTrkObjID6 : 39|5@0+ (1,0) [0|31] ""  EOCM_F_FO
 SG_ RFSrrTrkObjElevation6 : 20|2@0+ (1,0) [0|3] ""  EOCM_F_FO
 SG_ RFSrrTrkDynamProp6 : 23|3@0+ (1,0) [0|7] ""  EOCM_F_FO
 SG_ RFSrrTrkMeasStatus6 : 55|2@0+ (1,0) [0|3] ""  EOCM_F_FO

BO_ 1239 RF_SRR_Object_Track7: 8 RFSRR_FO
 SG_ RFSrrTrkObsRange7 : 53|6@0- (0.02,0) [-0.64|0.62] "m"  EOCM_F_FO
 SG_ RFSrrTrkRawAzimuth7 : 61|6@0- (1,0) [-32|31] "deg"  EOCM_F_FO
 SG_ RFSrrBurstID7 : 63|2@0+ (1,0) [0|3] ""  EOCM_F_FO
 SG_ RFSrrTrkRange7 : 2|11@0+ (0.02,0) [0|40.94] "m"  EOCM_F_FO
 SG_ RFSrrTrkRRate7 : 18|11@0- (0.125,0) [-128|127.875] "m/s"  EOCM_F_FO
 SG_ RFSrrTrkAzimuth7 : 34|11@0- (0.125,0) [-128|127.875] "deg"  EOCM_F_FO
 SG_ RFSrrTrkObjID7 : 39|5@0+ (1,0) [0|31] ""  EOCM_F_FO
 SG_ RFSrrTrkObjElevation7 : 20|2@0+ (1,0) [0|3] ""  EOCM_F_FO
 SG_ RFSrrTrkDynamProp7 : 23|3@0+ (1,0) [0|7] ""  EOCM_F_FO
 SG_ RFSrrTrkMeasStatus7 : 55|2@0+ (1,0) [0|3] ""  EOCM_F_FO

BO_ 1240 RF_SRR_Object_Track8: 8 RFSRR_FO
 SG_ RFSrrTrkObsRange8 : 53|6@0- (0.02,0) [-0.64|0.62] "m"  EOCM_F_FO
 SG_ RFSrrTrkRawAzimuth8 : 61|6@0- (1,0) [-32|31] "deg"  EOCM_F_FO
 SG_ RFSrrBurstID8 : 63|2@0+ (1,0) [0|3] ""  EOCM_F_FO
 SG_ RFSrrTrkRange8 : 2|11@0+ (0.02,0) [0|40.94] "m"  EOCM_F_FO
 SG_ RFSrrTrkRRate8 : 18|11@0- (0.125,0) [-128|127.875] "m/s"  EOCM_F_FO
 SG_ RFSrrTrkAzimuth8 : 34|11@0- (0.125,0) [-128|127.875] "deg"  EOCM_F_FO
 SG_ RFSrrTrkObjID8 : 39|5@0+ (1,0) [0|31] ""  EOCM_F_FO
 SG_ RFSrrTrkObjElevation8 : 20|2@0+ (1,0) [0|3] ""  EOCM_F_FO
 SG_ RFSrrTrkDynamProp8 : 23|3@0+ (1,0) [0|7] ""  EOCM_F_FO
 SG_ RFSrrTrkMeasStatus8 : 55|2@0+ (1,0) [0|3] ""  EOCM_F_FO

BO_ 1241 RF_SRR_Object_Track9: 8 RFSRR_FO
 SG_ RFSrrTrkObsRange9 : 53|6@0- (0.02,0) [-0.64|0.62] "m"  EOCM_F_FO
 SG_ RFSrrTrkRawAzimuth9 : 61|6@0- (1,0) [-32|31] "deg"  EOCM_F_FO
 SG_ RFSrrBurstID9 : 63|2@0+ (1,0) [0|3] ""  EOCM_F_FO
 SG_ RFSrrTrkRange9 : 2|11@0+ (0.02,0) [0|40.94] "m"  EOCM_F_FO
 SG_ RFSrrTrkRRate9 : 18|11@0- (0.125,0) [-128|127.875] "m/s"  EOCM_F_FO
 SG_ RFSrrTrkAzimuth9 : 34|11@0- (0.125,0) [-128|127.875] "deg"  EOCM_F_FO
 SG_ RFSrrTrkObjID9 : 39|5@0+ (1,0) [0|31] ""  EOCM_F_FO
 SG_ RFSrrTrkObjElevation9 : 20|2@0+ (1,0) [0|3] ""  EOCM_F_FO
 SG_ RFSrrTrkDynamProp9 : 23|3@0+ (1,0) [0|7] ""  EOCM_F_FO
 SG_ RFSrrTrkMeasStatus9 : 55|2@0+ (1,0) [0|3] ""  EOCM_F_FO

BO_ 1242 RF_SRR_Object_Track10: 8 RFSRR_FO
 SG_ RFSrrTrkObsRange10 : 53|6@0- (0.02,0) [-0.64|0.62] "m"  EOCM_F_FO
 SG_ RFSrrTrkRawAzimuth10 : 61|6@0- (1,0) [-32|31] "deg"  EOCM_F_FO
 SG_ RFSrrBurstID10 : 63|2@0+ (1,0) [0|3] ""  EOCM_F_FO
 SG_ RFSrrTrkRange10 : 2|11@0+ (0.02,0) [0|40.94] "m"  EOCM_F_FO
 SG_ RFSrrTrkRRate10 : 18|11@0- (0.125,0) [-128|127.875] "m/s"  EOCM_F_FO
 SG_ RFSrrTrkAzimuth10 : 34|11@0- (0.125,0) [-128|127.875] "deg"  EOCM_F_FO
 SG_ RFSrrTrkObjID10 : 39|5@0+ (1,0) [0|31] ""  EOCM_F_FO
 SG_ RFSrrTrkObjElevation10 : 20|2@0+ (1,0) [0|3] ""  EOCM_F_FO
 SG_ RFSrrTrkDynamProp10 : 23|3@0+ (1,0) [0|7] ""  EOCM_F_FO
 SG_ RFSrrTrkMeasStatus10 : 55|2@0+ (1,0) [0|3] ""  EOCM_F_FO

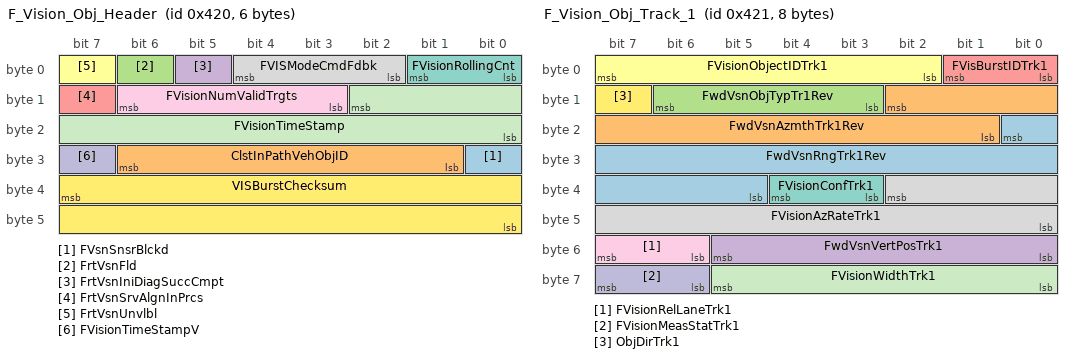
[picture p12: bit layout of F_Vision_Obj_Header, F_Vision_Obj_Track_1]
BO_ 1056 F_Vision_Obj_Header: 6 VIS_FO
 SG_ FVsnSnsrBlckd : 24|1@0+ (1,0) [0|1] ""  EOCM_F_FO
 SG_ ClstInPathVehObjID : 30|6@0+ (1,0) [0|63] ""  EOCM_F_FO
 SG_ FrtVsnFld : 6|1@0+ (1,0) [0|1] ""  EOCM_F_FO
 SG_ FrtVsnIniDiagSuccCmpt : 5|1@0+ (1,0) [0|1] ""  EOCM_F_FO
 SG_ FrtVsnSrvAlgnInPrcs : 15|1@0+ (1,0) [0|1] ""  EOCM_F_FO
 SG_ FrtVsnUnvlbl : 7|1@0+ (1,0) [0|1] ""  EOCM_F_FO
 SG_ FVisionRollingCnt : 1|2@0+ (1,0) [0|3] ""  EOCM_F_FO
 SG_ FVISModeCmdFdbk : 4|3@0+ (1,0) [0|7] ""  EOCM_F_FO
 SG_ FVisionNumValidTrgts : 14|4@0+ (1,0) [0|15] ""  EOCM_F_FO
 SG_ FVisionTimeStampV : 31|1@0+ (1,0) [0|1] ""  EOCM_F_FO
 SG_ FVisionTimeStamp : 10|11@0+ (1,0) [0|2047] "ms"  EOCM_F_FO
 SG_ VISBurstChecksum : 39|16@0+ (1,0) [0|65535] ""  EOCM_F_FO

BO_ 1057 F_Vision_Obj_Track_1: 8 VIS_FO
 SG_ FwdVsnRngTrk1Rev : 16|12@0+ (0.1,0) [0|409.5] "m"  EOCM_F_FO
 SG_ FwdVsnAzmthTrk1Rev : 10|10@0- (0.1,0) [-51.2|51.1] "deg"  EOCM_F_FO
 SG_ FwdVsnObjTypTr1Rev : 14|4@0+ (1,0) [0|15] ""  EOCM_F_FO
 SG_ FwdVsnVertPosTrk1 : 53|6@0+ (0.25,-2) [-2|13.75] "deg"  EOCM_F_FO
 SG_ FVisBurstIDTrk1 : 1|2@0+ (1,0) [0|3] ""  EOCM_F_FO
 SG_ FVisionObjectIDTrk1 : 7|6@0+ (1,0) [0|63] ""  EOCM_F_FO
 SG_ FVisionConfTrk1 : 36|2@0+ (1,0) [0|3] ""  EOCM_F_FO
 SG_ FVisionAzRateTrk1 : 34|11@0- (0.125,0) [-128|127.875] "deg/s"  EOCM_F_FO
 SG_ FVisionRelLaneTrk1 : 55|2@0+ (1,0) [0|3] ""  EOCM_F_FO
 SG_ FVisionMeasStatTrk1 : 63|2@0+ (1,0) [0|3] ""  EOCM_F_FO
 SG_ FVisionWidthTrk1 : 61|6@0+ (0.25,0) [0|15.75] "m"  EOCM_F_FO
 SG_ ObjDirTrk1 : 15|1@0+ (1,0) [0|1] ""  EOCM_F_FO

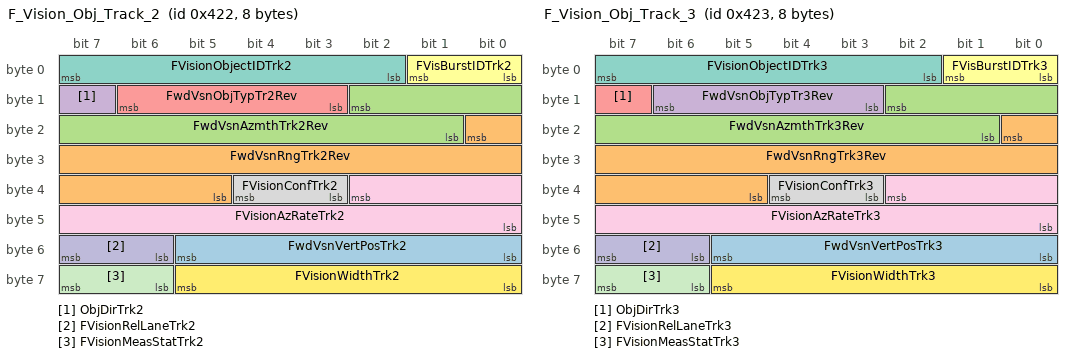
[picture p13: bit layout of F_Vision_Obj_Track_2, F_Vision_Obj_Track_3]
BO_ 1058 F_Vision_Obj_Track_2: 8 VIS_FO
 SG_ FwdVsnVertPosTrk2 : 53|6@0+ (0.25,-2) [-2|13.75] "deg"  EOCM_F_FO
 SG_ FwdVsnRngTrk2Rev : 16|12@0+ (0.1,0) [0|409.5] "m"  EOCM_F_FO
 SG_ FwdVsnAzmthTrk2Rev : 10|10@0- (0.1,0) [-51.2|51.1] "deg"  EOCM_F_FO
 SG_ ObjDirTrk2 : 15|1@0+ (1,0) [0|1] ""  EOCM_F_FO
 SG_ FwdVsnObjTypTr2Rev : 14|4@0+ (1,0) [0|15] ""  EOCM_F_FO
 SG_ FVisBurstIDTrk2 : 1|2@0+ (1,0) [0|3] ""  EOCM_F_FO
 SG_ FVisionObjectIDTrk2 : 7|6@0+ (1,0) [0|63] ""  EOCM_F_FO
 SG_ FVisionConfTrk2 : 36|2@0+ (1,0) [0|3] ""  EOCM_F_FO
 SG_ FVisionAzRateTrk2 : 34|11@0- (0.125,0) [-128|127.875] "deg/s"  EOCM_F_FO
 SG_ FVisionRelLaneTrk2 : 55|2@0+ (1,0) [0|3] ""  EOCM_F_FO
 SG_ FVisionMeasStatTrk2 : 63|2@0+ (1,0) [0|3] ""  EOCM_F_FO
 SG_ FVisionWidthTrk2 : 61|6@0+ (0.25,0) [0|15.75] "m"  EOCM_F_FO

BO_ 1059 F_Vision_Obj_Track_3: 8 VIS_FO
 SG_ FwdVsnVertPosTrk3 : 53|6@0+ (0.25,-2) [-2|13.75] "deg"  EOCM_F_FO
 SG_ FwdVsnRngTrk3Rev : 16|12@0+ (0.1,0) [0|409.5] "m"  EOCM_F_FO
 SG_ FwdVsnAzmthTrk3Rev : 10|10@0- (0.1,0) [-51.2|51.1] "deg"  EOCM_F_FO
 SG_ FwdVsnObjTypTr3Rev : 14|4@0+ (1,0) [0|15] ""  EOCM_F_FO
 SG_ ObjDirTrk3 : 15|1@0+ (1,0) [0|1] ""  EOCM_F_FO
 SG_ FVisBurstIDTrk3 : 1|2@0+ (1,0) [0|3] ""  EOCM_F_FO
 SG_ FVisionObjectIDTrk3 : 7|6@0+ (1,0) [0|63] ""  EOCM_F_FO
 SG_ FVisionConfTrk3 : 36|2@0+ (1,0) [0|3] ""  EOCM_F_FO
 SG_ FVisionAzRateTrk3 : 34|11@0- (0.125,0) [-128|127.875] "deg/s"  EOCM_F_FO
 SG_ FVisionRelLaneTrk3 : 55|2@0+ (1,0) [0|3] ""  EOCM_F_FO
 SG_ FVisionMeasStatTrk3 : 63|2@0+ (1,0) [0|3] ""  EOCM_F_FO
 SG_ FVisionWidthTrk3 : 61|6@0+ (0.25,0) [0|15.75] "m"  EOCM_F_FO

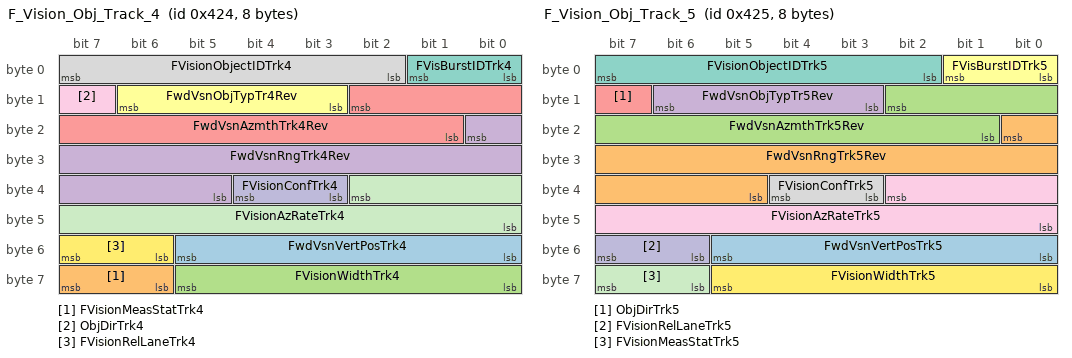
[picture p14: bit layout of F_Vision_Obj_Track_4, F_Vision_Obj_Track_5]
BO_ 1060 F_Vision_Obj_Track_4: 8 VIS_FO
 SG_ FwdVsnVertPosTrk4 : 53|6@0+ (0.25,-2) [-2|13.75] "deg"  EOCM_F_FO
 SG_ FVisionMeasStatTrk4 : 63|2@0+ (1,0) [0|3] ""  EOCM_F_FO
 SG_ FVisionWidthTrk4 : 61|6@0+ (0.25,0) [0|15.75] "m"  EOCM_F_FO
 SG_ FwdVsnRngTrk4Rev : 16|12@0+ (0.1,0) [0|409.5] "m"  EOCM_F_FO
 SG_ FwdVsnAzmthTrk4Rev : 10|10@0- (0.1,0) [-51.2|51.1] "deg"  EOCM_F_FO
 SG_ FwdVsnObjTypTr4Rev : 14|4@0+ (1,0) [0|15] ""  EOCM_F_FO
 SG_ FVisBurstIDTrk4 : 1|2@0+ (1,0) [0|3] ""  EOCM_F_FO
 SG_ FVisionObjectIDTrk4 : 7|6@0+ (1,0) [0|63] ""  EOCM_F_FO
 SG_ ObjDirTrk4 : 15|1@0+ (1,0) [0|1] ""  EOCM_F_FO
 SG_ FVisionConfTrk4 : 36|2@0+ (1,0) [0|3] ""  EOCM_F_FO
 SG_ FVisionAzRateTrk4 : 34|11@0- (0.125,0) [-128|127.875] "deg/s"  EOCM_F_FO
 SG_ FVisionRelLaneTrk4 : 55|2@0+ (1,0) [0|3] ""  EOCM_F_FO

BO_ 1061 F_Vision_Obj_Track_5: 8 VIS_FO
 SG_ FwdVsnVertPosTrk5 : 53|6@0+ (0.25,-2) [-2|13.75] "deg"  EOCM_F_FO
 SG_ FwdVsnRngTrk5Rev : 16|12@0+ (0.1,0) [0|409.5] "m"  EOCM_F_FO
 SG_ FwdVsnAzmthTrk5Rev : 10|10@0- (0.1,0) [-51.2|51.1] "deg"  EOCM_F_FO
 SG_ FwdVsnObjTypTr5Rev : 14|4@0+ (1,0) [0|15] ""  EOCM_F_FO
 SG_ ObjDirTrk5 : 15|1@0+ (1,0) [0|1] ""  EOCM_F_FO
 SG_ FVisBurstIDTrk5 : 1|2@0+ (1,0) [0|3] ""  EOCM_F_FO
 SG_ FVisionObjectIDTrk5 : 7|6@0+ (1,0) [0|63] ""  EOCM_F_FO
 SG_ FVisionConfTrk5 : 36|2@0+ (1,0) [0|3] ""  EOCM_F_FO
 SG_ FVisionAzRateTrk5 : 34|11@0- (0.125,0) [-128|127.875] "deg/s"  EOCM_F_FO
 SG_ FVisionRelLaneTrk5 : 55|2@0+ (1,0) [0|3] ""  EOCM_F_FO
 SG_ FVisionMeasStatTrk5 : 63|2@0+ (1,0) [0|3] ""  EOCM_F_FO
 SG_ FVisionWidthTrk5 : 61|6@0+ (0.25,0) [0|15.75] "m"  EOCM_F_FO

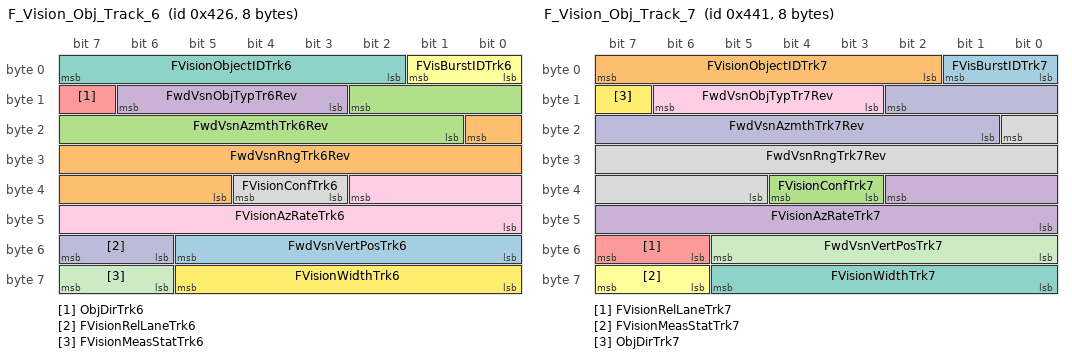
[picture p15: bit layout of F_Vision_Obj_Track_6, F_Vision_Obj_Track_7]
BO_ 1062 F_Vision_Obj_Track_6: 8 VIS_FO
 SG_ FwdVsnVertPosTrk6 : 53|6@0+ (0.25,-2) [-2|13.75] "deg"  EOCM_F_FO
 SG_ FwdVsnRngTrk6Rev : 16|12@0+ (0.1,0) [0|409.5] "m"  EOCM_F_FO
 SG_ FwdVsnAzmthTrk6Rev : 10|10@0- (0.1,0) [-51.2|51.1] "deg"  EOCM_F_FO
 SG_ FwdVsnObjTypTr6Rev : 14|4@0+ (1,0) [0|15] ""  EOCM_F_FO
 SG_ ObjDirTrk6 : 15|1@0+ (1,0) [0|1] ""  EOCM_F_FO
 SG_ FVisBurstIDTrk6 : 1|2@0+ (1,0) [0|3] ""  EOCM_F_FO
 SG_ FVisionObjectIDTrk6 : 7|6@0+ (1,0) [0|63] ""  EOCM_F_FO
 SG_ FVisionConfTrk6 : 36|2@0+ (1,0) [0|3] ""  EOCM_F_FO
 SG_ FVisionAzRateTrk6 : 34|11@0- (0.125,0) [-128|127.875] "deg/s"  EOCM_F_FO
 SG_ FVisionRelLaneTrk6 : 55|2@0+ (1,0) [0|3] ""  EOCM_F_FO
 SG_ FVisionMeasStatTrk6 : 63|2@0+ (1,0) [0|3] ""  EOCM_F_FO
 SG_ FVisionWidthTrk6 : 61|6@0+ (0.25,0) [0|15.75] "m"  EOCM_F_FO

BO_ 1538 LF_SRR_Trace_Data: 8 LFSRR_FO
 SG_ LFSRRYear : 7|8@0+ (1,0) [0|0] ""  EOCM_F_FO
 SG_ LFSRRSerialNmbr : 39|32@0+ (1,0) [0|0] ""  EOCM_F_FO
 SG_ LFSRRJulianDate : 15|24@0+ (1,0) [0|0] ""  EOCM_F_FO

BO_ 1537 R_SRR_Trace_data: 8 RSRR_FO
 SG_ RSRRYear : 7|8@0+ (1,0) [0|0] ""  EOCM_F_FO
 SG_ RSRRSerialNmbr : 39|32@0+ (1,0) [0|0] ""  EOCM_F_FO
 SG_ RSRRJulianDate : 15|24@0+ (1,0) [0|0] ""  EOCM_F_FO

BO_ 1089 F_Vision_Obj_Track_7: 8 VIS2_FO
 SG_ FVisBurstIDTrk7 : 1|2@0+ (1,0) [0|3] ""  EOCM_F_FO
 SG_ FVisionObjectIDTrk7 : 7|6@0+ (1,0) [0|63] ""  EOCM_F_FO
 SG_ FVisionConfTrk7 : 36|2@0+ (1,0) [0|3] ""  EOCM_F_FO
 SG_ FVisionAzRateTrk7 : 34|11@0- (0.125,0) [-128|127.875] "deg/s"  EOCM_F_FO
 SG_ FVisionRelLaneTrk7 : 55|2@0+ (1,0) [0|3] ""  EOCM_F_FO
 SG_ FVisionMeasStatTrk7 : 63|2@0+ (1,0) [0|3] ""  EOCM_F_FO
 SG_ FVisionWidthTrk7 : 61|6@0+ (0.25,0) [0|15.75] "m"  EOCM_F_FO
 SG_ FwdVsnRngTrk7Rev : 16|12@0+ (0.1,0) [0|409.5] "m"  EOCM_F_FO
 SG_ FwdVsnObjTypTr7Rev : 14|4@0+ (1,0) [0|15] ""  EOCM_F_FO
 SG_ FwdVsnAzmthTrk7Rev : 10|10@0- (0.1,0) [-51.2|51.1] "deg"  EOCM_F_FO
 SG_ FwdVsnVertPosTrk7 : 53|6@0+ (0.25,-2) [-2|13.75] "deg"  EOCM_F_FO
 SG_ ObjDirTrk7 : 15|1@0+ (1,0) [0|1] ""  EOCM_F_FO

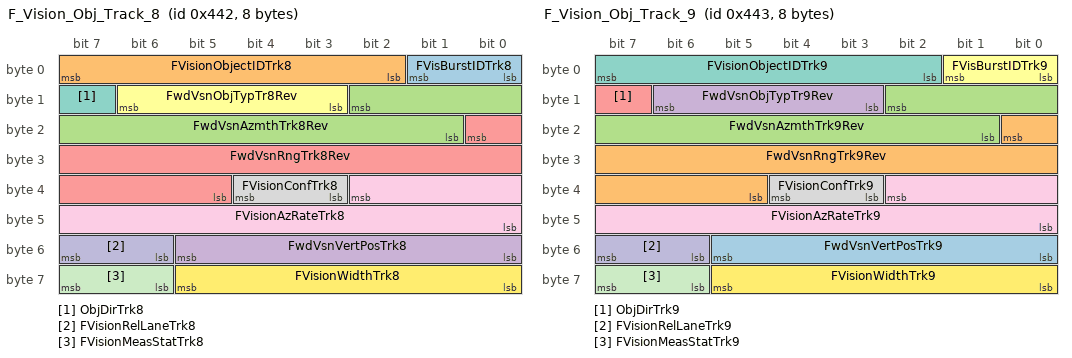
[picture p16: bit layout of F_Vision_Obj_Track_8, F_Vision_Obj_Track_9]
BO_ 1090 F_Vision_Obj_Track_8: 8 VIS2_FO
 SG_ FVisBurstIDTrk8 : 1|2@0+ (1,0) [0|3] ""  EOCM_F_FO
 SG_ FVisionObjectIDTrk8 : 7|6@0+ (1,0) [0|63] ""  EOCM_F_FO
 SG_ FwdVsnAzmthTrk8Rev : 10|10@0- (0.1,0) [-51.2|51.1] "deg"  EOCM_F_FO
 SG_ FwdVsnVertPosTrk8 : 53|6@0+ (0.25,-2) [-2|13.75] "deg"  EOCM_F_FO
 SG_ FwdVsnRngTrk8Rev : 16|12@0+ (0.1,0) [0|409.5] "m"  EOCM_F_FO
 SG_ FwdVsnObjTypTr8Rev : 14|4@0+ (1,0) [0|15] ""  EOCM_F_FO
 SG_ ObjDirTrk8 : 15|1@0+ (1,0) [0|1] ""  EOCM_F_FO
 SG_ FVisionConfTrk8 : 36|2@0+ (1,0) [0|3] ""  EOCM_F_FO
 SG_ FVisionAzRateTrk8 : 34|11@0- (0.125,0) [-128|127.875] "deg/s"  EOCM_F_FO
 SG_ FVisionRelLaneTrk8 : 55|2@0+ (1,0) [0|3] ""  EOCM_F_FO
 SG_ FVisionMeasStatTrk8 : 63|2@0+ (1,0) [0|3] ""  EOCM_F_FO
 SG_ FVisionWidthTrk8 : 61|6@0+ (0.25,0) [0|15.75] "m"  EOCM_F_FO

BO_ 1091 F_Vision_Obj_Track_9: 8 VIS2_FO
 SG_ FwdVsnVertPosTrk9 : 53|6@0+ (0.25,-2) [-2|13.75] "deg"  EOCM_F_FO
 SG_ FwdVsnRngTrk9Rev : 16|12@0+ (0.1,0) [0|409.5] "m"  EOCM_F_FO
 SG_ FwdVsnAzmthTrk9Rev : 10|10@0- (0.1,0) [-51.2|51.1] "deg"  EOCM_F_FO
 SG_ FwdVsnObjTypTr9Rev : 14|4@0+ (1,0) [0|15] ""  EOCM_F_FO
 SG_ ObjDirTrk9 : 15|1@0+ (1,0) [0|1] ""  EOCM_F_FO
 SG_ FVisBurstIDTrk9 : 1|2@0+ (1,0) [0|3] ""  EOCM_F_FO
 SG_ FVisionObjectIDTrk9 : 7|6@0+ (1,0) [0|63] ""  EOCM_F_FO
 SG_ FVisionConfTrk9 : 36|2@0+ (1,0) [0|3] ""  EOCM_F_FO
 SG_ FVisionAzRateTrk9 : 34|11@0- (0.125,0) [-128|127.875] "deg/s"  EOCM_F_FO
 SG_ FVisionRelLaneTrk9 : 55|2@0+ (1,0) [0|3] ""  EOCM_F_FO
 SG_ FVisionMeasStatTrk9 : 63|2@0+ (1,0) [0|3] ""  EOCM_F_FO
 SG_ FVisionWidthTrk9 : 61|6@0+ (0.25,0) [0|15.75] "m"  EOCM_F_FO

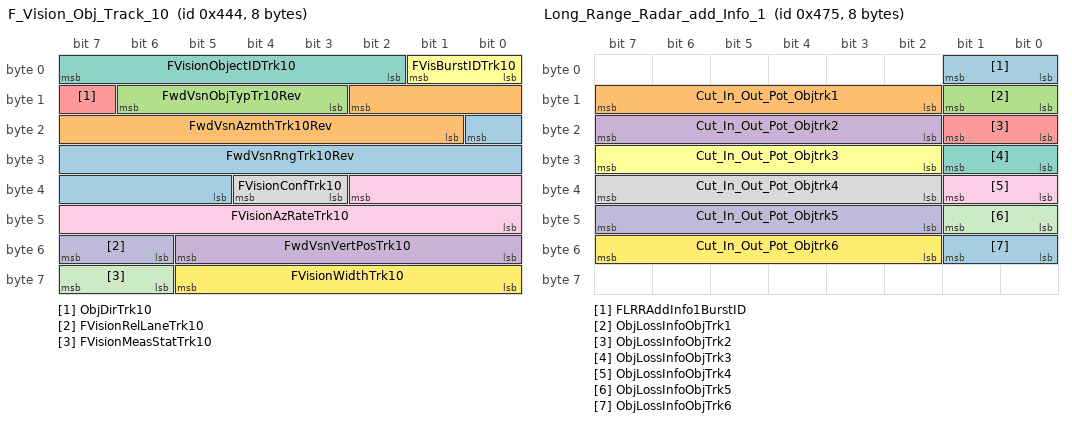
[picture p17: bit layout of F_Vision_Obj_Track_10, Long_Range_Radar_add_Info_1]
BO_ 1092 F_Vision_Obj_Track_10: 8 VIS2_FO
 SG_ FwdVsnRngTrk10Rev : 16|12@0+ (0.1,0) [0|409.5] "m"  EOCM_F_FO
 SG_ FwdVsnAzmthTrk10Rev : 10|10@0- (0.1,0) [-51.2|51.1] "deg"  EOCM_F_FO
 SG_ FwdVsnObjTypTr10Rev : 14|4@0+ (1,0) [0|15] ""  EOCM_F_FO
 SG_ FwdVsnVertPosTrk10 : 53|6@0+ (0.25,-2) [-2|13.75] "deg"  EOCM_F_FO
 SG_ ObjDirTrk10 : 15|1@0+ (1,0) [0|1] ""  EOCM_F_FO
 SG_ FVisBurstIDTrk10 : 1|2@0+ (1,0) [0|3] ""  EOCM_F_FO
 SG_ FVisionObjectIDTrk10 : 7|6@0+ (1,0) [0|63] ""  EOCM_F_FO
 SG_ FVisionConfTrk10 : 36|2@0+ (1,0) [0|3] ""  EOCM_F_FO
 SG_ FVisionAzRateTrk10 : 34|11@0- (0.125,0) [-128|127.875] "deg/s"  EOCM_F_FO
 SG_ FVisionRelLaneTrk10 : 55|2@0+ (1,0) [0|3] ""  EOCM_F_FO
 SG_ FVisionMeasStatTrk10 : 63|2@0+ (1,0) [0|3] ""  EOCM_F_FO
 SG_ FVisionWidthTrk10 : 61|6@0+ (0.25,0) [0|15.75] "m"  EOCM_F_FO

BO_ 1120 F_LRR_Obj_Header: 8 LRR_FO
 SG_ FLRRRollingCount : 7|2@0+ (1,0) [0|3] ""  EOCM_F_FO
 SG_ FLRRModeCmdFdbk : 23|3@0+ (1,0) [0|7] ""  EOCM_F_FO
 SG_ FLRRNumValidTargets : 20|5@0+ (1,0) [0|31] ""  EOCM_F_FO
 SG_ FLRRTimeStampV : 31|1@0+ (1,0) [0|1] ""  EOCM_F_FO
 SG_ FLRRTimeStamp : 2|11@0+ (1,0) [0|2047] "ms"  EOCM_F_FO
 SG_ FLRRRoadTypeInfo : 5|3@0+ (1,0) [0|7] ""  EOCM_F_FO
 SG_ FLRRBurstChecksum : 55|16@0+ (1,0) [0|65535] ""  EOCM_F_FO
 SG_ FLRRDiagSpare : 30|1@0+ (1,0) [0|1] ""  EOCM_F_FO
 SG_ FLRRVltgOutRngLo : 44|1@0+ (1,0) [0|1] ""  EOCM_F_FO
 SG_ FLRRVltgOutRngHi : 43|1@0+ (1,0) [0|1] ""  EOCM_F_FO
 SG_ FLRRSvcAlgnInPrcs : 38|1@0+ (1,0) [0|1] ""  EOCM_F_FO
 SG_ FLRRSnsrBlckd : 45|1@0+ (1,0) [0|1] ""  EOCM_F_FO
 SG_ FLRRSnstvFltPrsntInt : 24|1@0+ (1,0) [0|1] ""  EOCM_F_FO
 SG_ FLRRPlntAlgnInProc : 37|1@0+ (1,0) [0|1] ""  EOCM_F_FO
 SG_ FLRRMsalgnYawRt : 47|1@0+ (1,0) [0|1] ""  EOCM_F_FO
 SG_ FLRRMsalgnYawLt : 46|1@0+ (1,0) [0|1] ""  EOCM_F_FO
 SG_ FLRRLonVelPlsblityFlt : 35|1@0+ (1,0) [0|1] ""  EOCM_F_FO
 SG_ FLRRYawRtPlsblityFlt : 34|1@0+ (1,0) [0|1] ""  EOCM_F_FO
 SG_ FLRRMsalgnPtchUp : 32|1@0+ (1,0) [0|1] ""  EOCM_F_FO
 SG_ FLRRMsalgnPtchDn : 33|1@0+ (1,0) [0|1] ""  EOCM_F_FO
 SG_ FLRRInitDiagCmplt : 40|1@0+ (1,0) [0|1] ""  EOCM_F_FO
 SG_ FLRRHWFltPrsntInt : 25|1@0+ (1,0) [0|1] ""  EOCM_F_FO
 SG_ FLRRExtIntrfrnc : 36|1@0+ (1,0) [0|1] ""  EOCM_F_FO
 SG_ FLRRCANSgnlSpvFld : 29|1@0+ (1,0) [0|1] ""  EOCM_F_FO
 SG_ FLRRCANRxErr : 28|1@0+ (1,0) [0|1] ""  EOCM_F_FO
 SG_ FLRRTunlDtctd : 27|1@0+ (1,0) [0|1] ""  EOCM_F_FO
 SG_ FLRRAmbTmpOutRngLw : 42|1@0+ (1,0) [0|1] ""  EOCM_F_FO
 SG_ FLRRAmbTmpOutRngHi : 41|1@0+ (1,0) [0|1] ""  EOCM_F_FO
 SG_ FLRRAntTngFltPrsnt : 26|1@0+ (1,0) [0|1] ""  EOCM_F_FO
 SG_ FLRRAlgnFltPrsnt : 39|1@0+ (1,0) [0|1] ""  EOCM_F_FO

BO_ 1121 F_LRR_Obj_Track_1: 8 LRR_FO
 SG_ FLRRTrk1BurstID : 63|2@0+ (1,0) [0|3] ""  EOCM_F_FO
 SG_ FLRRTrk1Range : 5|11@0+ (0.125,0) [0|255.875] "m"  EOCM_F_FO
 SG_ FLRRTrk1RangeRate : 10|11@0- (0.125,0) [-128|127.875] "m/s"  EOCM_F_FO
 SG_ FLRRTrk1RangeAccel : 31|9@0- (0.125,0) [-32|31.875] "m/s^2"  EOCM_F_FO
 SG_ FLRRTrk1DynProp : 38|3@0+ (1,0) [0|7] ""  EOCM_F_FO
 SG_ FLRRTrk1Azimuth : 35|12@0- (0.125,0) [-256|255.875] "deg"  EOCM_F_FO
 SG_ FLRRTrk1Width : 55|6@0+ (0.25,0) [0|15.75] "m"  EOCM_F_FO
 SG_ FLRRTrk1MeasStatus : 7|2@0+ (1,0) [0|3] ""  EOCM_F_FO
 SG_ FLRRTrk1ObjectID : 61|6@0+ (1,0) [0|63] ""  EOCM_F_FO
 SG_ FLRRTrk1Conf : 49|2@0+ (1,0) [0|3] ""  EOCM_F_FO

BO_ 1122 F_LRR_Obj_Track_2: 8 LRR_FO
 SG_ FLRRTrk2BurstID : 63|2@0+ (1,0) [0|3] ""  EOCM_F_FO
 SG_ FLRRTrk2Range : 5|11@0+ (0.125,0) [0|255.875] "m"  EOCM_F_FO
 SG_ FLRRTrk2RangeRate : 10|11@0- (0.125,0) [-128|127.875] "m/s"  EOCM_F_FO
 SG_ FLRRTrk2RangeAccel : 31|9@0- (0.125,0) [-32|31.875] "m/s^2"  EOCM_F_FO
 SG_ FLRRTrk2DynProp : 38|3@0+ (1,0) [0|7] ""  EOCM_F_FO
 SG_ FLRRTrk2Azimuth : 35|12@0- (0.125,0) [-256|255.875] "deg"  EOCM_F_FO
 SG_ FLRRTrk2Width : 55|6@0+ (0.25,0) [0|15.75] "m"  EOCM_F_FO
 SG_ FLRRTrk2MeasStatus : 7|2@0+ (1,0) [0|3] ""  EOCM_F_FO
 SG_ FLRRTrk2ObjectID : 61|6@0+ (1,0) [0|63] ""  EOCM_F_FO
 SG_ FLRRTrk2Conf : 49|2@0+ (1,0) [0|3] ""  EOCM_F_FO

BO_ 1123 F_LRR_Obj_Track_3: 8 LRR_FO
 SG_ FLRRTrk3BurstID : 63|2@0+ (1,0) [0|3] ""  EOCM_F_FO
 SG_ FLRRTrk3Range : 5|11@0+ (0.125,0) [0|255.875] "m"  EOCM_F_FO
 SG_ FLRRTrk3RangeRate : 10|11@0- (0.125,0) [-128|127.875] "m/s"  EOCM_F_FO
 SG_ FLRRTrk3RangeAccel : 31|9@0- (0.125,0) [-32|31.875] "m/s^2"  EOCM_F_FO
 SG_ FLRRTrk3DynProp : 38|3@0+ (1,0) [0|7] ""  EOCM_F_FO
 SG_ FLRRTrk3Azimuth : 35|12@0- (0.125,0) [-256|255.875] "deg"  EOCM_F_FO
 SG_ FLRRTrk3Width : 55|6@0+ (0.25,0) [0|15.75] "m"  EOCM_F_FO
 SG_ FLRRTrk3MeasStatus : 7|2@0+ (1,0) [0|3] ""  EOCM_F_FO
 SG_ FLRRTrk3ObjectID : 61|6@0+ (1,0) [0|63] ""  EOCM_F_FO
 SG_ FLRRTrk3Conf : 49|2@0+ (1,0) [0|3] ""  EOCM_F_FO

BO_ 1124 F_LRR_Obj_Track_4: 8 LRR_FO
 SG_ FLRRTrk4BurstID : 63|2@0+ (1,0) [0|3] ""  EOCM_F_FO
 SG_ FLRRTrk4Range : 5|11@0+ (0.125,0) [0|255.875] "m"  EOCM_F_FO
 SG_ FLRRTrk4RangeRate : 10|11@0- (0.125,0) [-128|127.875] "m/s"  EOCM_F_FO
 SG_ FLRRTrk4RangeAccel : 31|9@0- (0.125,0) [-32|31.875] "m/s^2"  EOCM_F_FO
 SG_ FLRRTrk4DynProp : 38|3@0+ (1,0) [0|7] ""  EOCM_F_FO
 SG_ FLRRTrk4Azimuth : 35|12@0- (0.125,0) [-256|255.875] "deg"  EOCM_F_FO
 SG_ FLRRTrk4Width : 55|6@0+ (0.25,0) [0|15.75] "m"  EOCM_F_FO
 SG_ FLRRTrk4MeasStatus : 7|2@0+ (1,0) [0|3] ""  EOCM_F_FO
 SG_ FLRRTrk4ObjectID : 61|6@0+ (1,0) [0|63] ""  EOCM_F_FO
 SG_ FLRRTrk4Conf : 49|2@0+ (1,0) [0|3] ""  EOCM_F_FO

BO_ 1125 F_LRR_Obj_Track_5: 8 LRR_FO
 SG_ FLRRTrk5BurstID : 63|2@0+ (1,0) [0|3] ""  EOCM_F_FO
 SG_ FLRRTrk5Range : 5|11@0+ (0.125,0) [0|255.875] "m"  EOCM_F_FO
 SG_ FLRRTrk5RangeRate : 10|11@0- (0.125,0) [-128|127.875] "m/s"  EOCM_F_FO
 SG_ FLRRTrk5RangeAccel : 31|9@0- (0.125,0) [-32|31.875] "m/s^2"  EOCM_F_FO
 SG_ FLRRTrk5DynProp : 38|3@0+ (1,0) [0|7] ""  EOCM_F_FO
 SG_ FLRRTrk5Azimuth : 35|12@0- (0.125,0) [-256|255.875] "deg"  EOCM_F_FO
 SG_ FLRRTrk5Width : 55|6@0+ (0.25,0) [0|15.75] "m"  EOCM_F_FO
 SG_ FLRRTrk5MeasStatus : 7|2@0+ (1,0) [0|3] ""  EOCM_F_FO
 SG_ FLRRTrk5ObjectID : 61|6@0+ (1,0) [0|63] ""  EOCM_F_FO
 SG_ FLRRTrk5Conf : 49|2@0+ (1,0) [0|3] ""  EOCM_F_FO

BO_ 1126 F_LRR_Obj_Track_6: 8 LRR_FO
 SG_ FLRRTrk6BurstID : 63|2@0+ (1,0) [0|3] ""  EOCM_F_FO
 SG_ FLRRTrk6Range : 5|11@0+ (0.125,0) [0|255.875] "m"  EOCM_F_FO
 SG_ FLRRTrk6RangeRate : 10|11@0- (0.125,0) [-128|127.875] "m/s"  EOCM_F_FO
 SG_ FLRRTrk6Conf : 49|2@0+ (1,0) [0|3] ""  EOCM_F_FO
 SG_ FLRRTrk6RangeAccel : 31|9@0- (0.125,0) [-32|31.875] "m/s^2"  EOCM_F_FO
 SG_ FLRRTrk6DynProp : 38|3@0+ (1,0) [0|7] ""  EOCM_F_FO
 SG_ FLRRTrk6Azimuth : 35|12@0- (0.125,0) [-256|255.875] "deg"  EOCM_F_FO
 SG_ FLRRTrk6Width : 55|6@0+ (0.25,0) [0|15.75] "m"  EOCM_F_FO
 SG_ FLRRTrk6MeasStatus : 7|2@0+ (1,0) [0|3] ""  EOCM_F_FO
 SG_ FLRRTrk6ObjectID : 61|6@0+ (1,0) [0|63] ""  EOCM_F_FO

BO_ 1127 F_LRR_Obj_Track_7: 8 LRR_FO
 SG_ FLRRTrk7Conf : 49|2@0+ (1,0) [0|3] ""  EOCM_F_FO
 SG_ FLRRTrk7BurstID : 63|2@0+ (1,0) [0|3] ""  EOCM_F_FO
 SG_ FLRRTrk7Range : 5|11@0+ (0.125,0) [0|255.875] "m"  EOCM_F_FO
 SG_ FLRRTrk7RangeRate : 10|11@0- (0.125,0) [-128|127.875] "m/s"  EOCM_F_FO
 SG_ FLRRTrk7RangeAccel : 31|9@0- (0.125,0) [-32|31.875] "m/s^2"  EOCM_F_FO
 SG_ FLRRTrk7DynProp : 38|3@0+ (1,0) [0|7] ""  EOCM_F_FO
 SG_ FLRRTrk7Azimuth : 35|12@0- (0.125,0) [-256|255.875] "deg"  EOCM_F_FO
 SG_ FLRRTrk7Width : 55|6@0+ (0.25,0) [0|15.75] "m"  EOCM_F_FO
 SG_ FLRRTrk7MeasStatus : 7|2@0+ (1,0) [0|3] ""  EOCM_F_FO
 SG_ FLRRTrk7ObjectID : 61|6@0+ (1,0) [0|63] ""  EOCM_F_FO

BO_ 1128 F_LRR_Obj_Track_8: 8 LRR_FO
 SG_ FLRRTrk8Conf : 49|2@0+ (1,0) [0|3] ""  EOCM_F_FO
 SG_ FLRRTrk8BurstID : 63|2@0+ (1,0) [0|3] ""  EOCM_F_FO
 SG_ FLRRTrk8Range : 5|11@0+ (0.125,0) [0|255.875] "m"  EOCM_F_FO
 SG_ FLRRTrk8RangeRate : 10|11@0- (0.125,0) [-128|127.875] "m/s"  EOCM_F_FO
 SG_ FLRRTrk8RangeAccel : 31|9@0- (0.125,0) [-32|31.875] "m/s^2"  EOCM_F_FO
 SG_ FLRRTrk8DynProp : 38|3@0+ (1,0) [0|7] ""  EOCM_F_FO
 SG_ FLRRTrk8Azimuth : 35|12@0- (0.125,0) [-256|255.875] "deg"  EOCM_F_FO
 SG_ FLRRTrk8Width : 55|6@0+ (0.25,0) [0|15.75] "m"  EOCM_F_FO
 SG_ FLRRTrk8MeasStatus : 7|2@0+ (1,0) [0|3] ""  EOCM_F_FO
 SG_ FLRRTrk8ObjectID : 61|6@0+ (1,0) [0|63] ""  EOCM_F_FO

BO_ 1129 F_LRR_Obj_Track_9: 8 LRR_FO
 SG_ FLRRTrk9Conf : 49|2@0+ (1,0) [0|3] ""  EOCM_F_FO
 SG_ FLRRTrk9BurstID : 63|2@0+ (1,0) [0|3] ""  EOCM_F_FO
 SG_ FLRRTrk9Range : 5|11@0+ (0.125,0) [0|255.875] "m"  EOCM_F_FO
 SG_ FLRRTrk9RangeRate : 10|11@0- (0.125,0) [-128|127.875] "m/s"  EOCM_F_FO
 SG_ FLRRTrk9RangeAccel : 31|9@0- (0.125,0) [-32|31.875] "m/s^2"  EOCM_F_FO
 SG_ FLRRTrk9DynProp : 38|3@0+ (1,0) [0|7] ""  EOCM_F_FO
 SG_ FLRRTrk9Azimuth : 35|12@0- (0.125,0) [-256|255.875] "deg"  EOCM_F_FO
 SG_ FLRRTrk9Width : 55|6@0+ (0.25,0) [0|15.75] "m"  EOCM_F_FO
 SG_ FLRRTrk9MeasStatus : 7|2@0+ (1,0) [0|3] ""  EOCM_F_FO
 SG_ FLRRTrk9ObjectID : 61|6@0+ (1,0) [0|63] ""  EOCM_F_FO

BO_ 1130 F_LRR_Obj_Track_10: 8 LRR_FO
 SG_ FLRRTrk10Conf : 49|2@0+ (1,0) [0|3] ""  EOCM_F_FO
 SG_ FLRRTrk10BurstID : 63|2@0+ (1,0) [0|3] ""  EOCM_F_FO
 SG_ FLRRTrk10Range : 5|11@0+ (0.125,0) [0|255.875] "m"  EOCM_F_FO
 SG_ FLRRTrk10RangeRate : 10|11@0- (0.125,0) [-128|127.875] "m/s"  EOCM_F_FO
 SG_ FLRRTrk10RangeAccel : 31|9@0- (0.125,0) [-32|31.875] "m/s^2"  EOCM_F_FO
 SG_ FLRRTrk10DynProp : 38|3@0+ (1,0) [0|7] ""  EOCM_F_FO
 SG_ FLRRTrk10Azimuth : 35|12@0- (0.125,0) [-256|255.875] "deg"  EOCM_F_FO
 SG_ FLRRTrk10Width : 55|6@0+ (0.25,0) [0|15.75] "m"  EOCM_F_FO
 SG_ FLRRTrk10MeasStatus : 7|2@0+ (1,0) [0|3] ""  EOCM_F_FO
 SG_ FLRRTrk10ObjectID : 61|6@0+ (1,0) [0|63] ""  EOCM_F_FO

BO_ 1131 F_LRR_Obj_Track_11: 8 LRR_FO
 SG_ FLRRTrk11Conf : 49|2@0+ (1,0) [0|3] ""  EOCM_F_FO
 SG_ FLRRTrk11BurstID : 63|2@0+ (1,0) [0|3] ""  EOCM_F_FO
 SG_ FLRRTrk11Range : 5|11@0+ (0.125,0) [0|255.875] "m"  EOCM_F_FO
 SG_ FLRRTrk11RangeRate : 10|11@0- (0.125,0) [-128|127.875] "m/s"  EOCM_F_FO
 SG_ FLRRTrk11RangeAccel : 31|9@0- (0.125,0) [-32|31.875] "m/s^2"  EOCM_F_FO
 SG_ FLRRTrk11DynProp : 38|3@0+ (1,0) [0|7] ""  EOCM_F_FO
 SG_ FLRRTrk11Azimuth : 35|12@0- (0.125,0) [-256|255.875] "deg"  EOCM_F_FO
 SG_ FLRRTrk11Width : 55|6@0+ (0.25,0) [0|15.75] "m"  EOCM_F_FO
 SG_ FLRRTrk11MeasStatus : 7|2@0+ (1,0) [0|3] ""  EOCM_F_FO
 SG_ FLRRTrk11ObjectID : 61|6@0+ (1,0) [0|63] ""  EOCM_F_FO

BO_ 1132 F_LRR_Obj_Track_12: 8 LRR_FO
 SG_ FLRRTrk12Conf : 49|2@0+ (1,0) [0|3] ""  EOCM_F_FO
 SG_ FLRRTrk12BurstID : 63|2@0+ (1,0) [0|3] ""  EOCM_F_FO
 SG_ FLRRTrk12Range : 5|11@0+ (0.125,0) [0|255.875] "m"  EOCM_F_FO
 SG_ FLRRTrk12RangeRate : 10|11@0- (0.125,0) [-128|127.875] "m/s"  EOCM_F_FO
 SG_ FLRRTrk12RangeAccel : 31|9@0- (0.125,0) [-32|31.875] "m/s^2"  EOCM_F_FO
 SG_ FLRRTrk12DynProp : 38|3@0+ (1,0) [0|7] ""  EOCM_F_FO
 SG_ FLRRTrk12Azimuth : 35|12@0- (0.125,0) [-256|255.875] "deg"  EOCM_F_FO
 SG_ FLRRTrk12Width : 55|6@0+ (0.25,0) [0|15.75] "m"  EOCM_F_FO
 SG_ FLRRTrk12MeasStatus : 7|2@0+ (1,0) [0|3] ""  EOCM_F_FO
 SG_ FLRRTrk12ObjectID : 61|6@0+ (1,0) [0|63] ""  EOCM_F_FO

BO_ 1133 F_LRR_Obj_Track_13: 8 LRR_FO
 SG_ FLRRTrk13Conf : 49|2@0+ (1,0) [0|3] ""  EOCM_F_FO
 SG_ FLRRTrk13BurstID : 63|2@0+ (1,0) [0|3] ""  EOCM_F_FO
 SG_ FLRRTrk13Range : 5|11@0+ (0.125,0) [0|255.875] "m"  EOCM_F_FO
 SG_ FLRRTrk13RangeRate : 10|11@0- (0.125,0) [-128|127.875] "m/s"  EOCM_F_FO
 SG_ FLRRTrk13RangeAccel : 31|9@0- (0.125,0) [-32|31.875] "m/s^2"  EOCM_F_FO
 SG_ FLRRTrk13DynProp : 38|3@0+ (1,0) [0|7] ""  EOCM_F_FO
 SG_ FLRRTrk13Azimuth : 35|12@0- (0.125,0) [-256|255.875] "deg"  EOCM_F_FO
 SG_ FLRRTrk13Width : 55|6@0+ (0.25,0) [0|15.75] "m"  EOCM_F_FO
 SG_ FLRRTrk13MeasStatus : 7|2@0+ (1,0) [0|3] ""  EOCM_F_FO
 SG_ FLRRTrk13ObjectID : 61|6@0+ (1,0) [0|63] ""  EOCM_F_FO

BO_ 1134 F_LRR_Obj_Track_14: 8 LRR_FO
 SG_ FLRRTrk14Conf : 49|2@0+ (1,0) [0|3] ""  EOCM_F_FO
 SG_ FLRRTrk14BurstID : 63|2@0+ (1,0) [0|3] ""  EOCM_F_FO
 SG_ FLRRTrk14Range : 5|11@0+ (0.125,0) [0|255.875] "m"  EOCM_F_FO
 SG_ FLRRTrk14RangeRate : 10|11@0- (0.125,0) [-128|127.875] "m/s"  EOCM_F_FO
 SG_ FLRRTrk14RangeAccel : 31|9@0- (0.125,0) [-32|31.875] "m/s^2"  EOCM_F_FO
 SG_ FLRRTrk14DynProp : 38|3@0+ (1,0) [0|7] ""  EOCM_F_FO
 SG_ FLRRTrk14Azimuth : 35|12@0- (0.125,0) [-256|255.875] "deg"  EOCM_F_FO
 SG_ FLRRTrk14Width : 55|6@0+ (0.25,0) [0|15.75] "m"  EOCM_F_FO
 SG_ FLRRTrk14MeasStatus : 7|2@0+ (1,0) [0|3] ""  EOCM_F_FO
 SG_ FLRRTrk14ObjectID : 61|6@0+ (1,0) [0|63] ""  EOCM_F_FO

BO_ 1135 F_LRR_Obj_Track_15: 8 LRR_FO
 SG_ FLRRTrk15Width : 55|6@0+ (0.25,0) [0|15.75] "m"  EOCM_F_FO
 SG_ FLRRTrk15MeasStatus : 7|2@0+ (1,0) [0|3] ""  EOCM_F_FO
 SG_ FLRRTrk15Conf : 49|2@0+ (1,0) [0|3] ""  EOCM_F_FO
 SG_ FLRRTrk15ObjectID : 61|6@0+ (1,0) [0|63] ""  EOCM_F_FO
 SG_ FLRRTrk15BurstID : 63|2@0+ (1,0) [0|3] ""  EOCM_F_FO
 SG_ FLRRTrk15Range : 5|11@0+ (0.125,0) [0|255.875] "m"  EOCM_F_FO
 SG_ FLRRTrk15RangeRate : 10|11@0- (0.125,0) [-128|127.875] "m/s"  EOCM_F_FO
 SG_ FLRRTrk15RangeAccel : 31|9@0- (0.125,0) [-32|31.875] "m/s^2"  EOCM_F_FO
 SG_ FLRRTrk15DynProp : 38|3@0+ (1,0) [0|7] ""  EOCM_F_FO
 SG_ FLRRTrk15Azimuth : 35|12@0- (0.125,0) [-256|255.875] "deg"  EOCM_F_FO

BO_ 1136 F_LRR_Obj_Track_16: 8 LRR_FO
 SG_ FLRRTrk16Conf : 49|2@0+ (1,0) [0|3] ""  EOCM_F_FO
 SG_ FLRRTrk16BurstID : 63|2@0+ (1,0) [0|3] ""  EOCM_F_FO
 SG_ FLRRTrk16Range : 5|11@0+ (0.125,0) [0|255.875] "m"  EOCM_F_FO
 SG_ FLRRTrk16RangeRate : 10|11@0- (0.125,0) [-128|127.875] "m/s"  EOCM_F_FO
 SG_ FLRRTrk16RangeAccel : 31|9@0- (0.125,0) [-32|31.875] "m/s^2"  EOCM_F_FO
 SG_ FLRRTrk16DynProp : 38|3@0+ (1,0) [0|7] ""  EOCM_F_FO
 SG_ FLRRTrk16Azimuth : 35|12@0- (0.125,0) [-256|255.875] "deg"  EOCM_F_FO
 SG_ FLRRTrk16Width : 55|6@0+ (0.25,0) [0|15.75] "m"  EOCM_F_FO
 SG_ FLRRTrk16MeasStatus : 7|2@0+ (1,0) [0|3] ""  EOCM_F_FO
 SG_ FLRRTrk16ObjectID : 61|6@0+ (1,0) [0|63] ""  EOCM_F_FO

BO_ 1137 F_LRR_Obj_Track_17: 8 LRR_FO
 SG_ FLRRTrk17Conf : 49|2@0+ (1,0) [0|3] ""  EOCM_F_FO
 SG_ FLRRTrk17BurstID : 63|2@0+ (1,0) [0|3] ""  EOCM_F_FO
 SG_ FLRRTrk17Range : 5|11@0+ (0.125,0) [0|255.875] "m"  EOCM_F_FO
 SG_ FLRRTrk17RangeRate : 10|11@0- (0.125,0) [-128|127.875] "m/s"  EOCM_F_FO
 SG_ FLRRTrk17RangeAccel : 31|9@0- (0.125,0) [-32|31.875] "m/s^2"  EOCM_F_FO
 SG_ FLRRTrk17DynProp : 38|3@0+ (1,0) [0|7] ""  EOCM_F_FO
 SG_ FLRRTrk17Azimuth : 35|12@0- (0.125,0) [-256|255.875] "deg"  EOCM_F_FO
 SG_ FLRRTrk17Width : 55|6@0+ (0.25,0) [0|15.75] "m"  EOCM_F_FO
 SG_ FLRRTrk17MeasStatus : 7|2@0+ (1,0) [0|3] ""  EOCM_F_FO
 SG_ FLRRTrk17ObjectID : 61|6@0+ (1,0) [0|63] ""  EOCM_F_FO

BO_ 1138 F_LRR_Obj_Track_18: 8 LRR_FO
 SG_ FLRRTrk18Conf : 49|2@0+ (1,0) [0|3] ""  EOCM_F_FO
 SG_ FLRRTrk18BurstID : 63|2@0+ (1,0) [0|3] ""  EOCM_F_FO
 SG_ FLRRTrk18Range : 5|11@0+ (0.125,0) [0|255.875] "m"  EOCM_F_FO
 SG_ FLRRTrk18RangeRate : 10|11@0- (0.125,0) [-128|127.875] "m/s"  EOCM_F_FO
 SG_ FLRRTrk18RangeAccel : 31|9@0- (0.125,0) [-32|31.875] "m/s^2"  EOCM_F_FO
 SG_ FLRRTrk18DynProp : 38|3@0+ (1,0) [0|7] ""  EOCM_F_FO
 SG_ FLRRTrk18Azimuth : 35|12@0- (0.125,0) [-256|255.875] "deg"  EOCM_F_FO
 SG_ FLRRTrk18Width : 55|6@0+ (0.25,0) [0|15.75] "m"  EOCM_F_FO
 SG_ FLRRTrk18MeasStatus : 7|2@0+ (1,0) [0|3] ""  EOCM_F_FO
 SG_ FLRRTrk18ObjectID : 61|6@0+ (1,0) [0|63] ""  EOCM_F_FO

BO_ 1139 F_LRR_Obj_Track_19: 8 LRR_FO
 SG_ FLRRTrk19Conf : 49|2@0+ (1,0) [0|3] ""  EOCM_F_FO
 SG_ FLRRTrk19BurstID : 63|2@0+ (1,0) [0|3] ""  EOCM_F_FO
 SG_ FLRRTrk19Range : 5|11@0+ (0.125,0) [0|255.875] "m"  EOCM_F_FO
 SG_ FLRRTrk19RangeRate : 10|11@0- (0.125,0) [-128|127.875] "m/s"  EOCM_F_FO
 SG_ FLRRTrk19RangeAccel : 31|9@0- (0.125,0) [-32|31.875] "m/s^2"  EOCM_F_FO
 SG_ FLRRTrk19DynProp : 38|3@0+ (1,0) [0|7] ""  EOCM_F_FO
 SG_ FLRRTrk19Azimuth : 35|12@0- (0.125,0) [-256|255.875] "deg"  EOCM_F_FO
 SG_ FLRRTrk19Width : 55|6@0+ (0.25,0) [0|15.75] "m"  EOCM_F_FO
 SG_ FLRRTrk19MeasStatus : 7|2@0+ (1,0) [0|3] ""  EOCM_F_FO
 SG_ FLRRTrk19ObjectID : 61|6@0+ (1,0) [0|63] ""  EOCM_F_FO

BO_ 1140 F_LRR_Obj_Track_20: 8 LRR_FO
 SG_ FLRRTrk20Conf : 49|2@0+ (1,0) [0|3] ""  EOCM_F_FO
 SG_ FLRRTrk20BurstID : 63|2@0+ (1,0) [0|3] ""  EOCM_F_FO
 SG_ FLRRTrk20Range : 5|11@0+ (0.125,0) [0|255.875] "m"  EOCM_F_FO
 SG_ FLRRTrk20RangeRate : 10|11@0- (0.125,0) [-128|127.875] "m/s"  EOCM_F_FO
 SG_ FLRRTrk20RangeAccel : 31|9@0- (0.125,0) [-32|31.875] "m/s^2"  EOCM_F_FO
 SG_ FLRRTrk20DynProp : 38|3@0+ (1,0) [0|7] ""  EOCM_F_FO
 SG_ FLRRTrk20Azimuth : 35|12@0- (0.125,0) [-256|255.875] "deg"  EOCM_F_FO
 SG_ FLRRTrk20Width : 55|6@0+ (0.25,0) [0|15.75] "m"  EOCM_F_FO
 SG_ FLRRTrk20MeasStatus : 7|2@0+ (1,0) [0|3] ""  EOCM_F_FO
 SG_ FLRRTrk20ObjectID : 61|6@0+ (1,0) [0|63] ""  EOCM_F_FO

BO_ 1141 Long_Range_Radar_add_Info_1: 8 LRR_FO
 SG_ FLRRAddInfo1BurstID : 1|2@0+ (1,0) [0|3] ""  EOCM_F_FO
 SG_ Cut_In_Out_Pot_Objtrk1 : 15|6@0+ (0.02,0) [0|1.26] ""  EOCM_F_FO
 SG_ ObjLossInfoObjTrk1 : 9|2@0+ (1,0) [0|3] ""  EOCM_F_FO
 SG_ Cut_In_Out_Pot_Objtrk2 : 23|6@0+ (0.02,0) [0|1.26] ""  EOCM_F_FO
 SG_ ObjLossInfoObjTrk2 : 17|2@0+ (1,0) [0|3] ""  EOCM_F_FO
 SG_ Cut_In_Out_Pot_Objtrk3 : 31|6@0+ (0.02,0) [0|1.26] ""  EOCM_F_FO
 SG_ ObjLossInfoObjTrk3 : 25|2@0+ (1,0) [0|3] ""  EOCM_F_FO
 SG_ Cut_In_Out_Pot_Objtrk4 : 39|6@0+ (0.02,0) [0|1.26] ""  EOCM_F_FO
 SG_ ObjLossInfoObjTrk4 : 33|2@0+ (1,0) [0|3] ""  EOCM_F_FO
 SG_ Cut_In_Out_Pot_Objtrk5 : 47|6@0+ (0.02,0) [0|1.26] ""  EOCM_F_FO
 SG_ ObjLossInfoObjTrk5 : 41|2@0+ (1,0) [0|3] ""  EOCM_F_FO
 SG_ Cut_In_Out_Pot_Objtrk6 : 55|6@0+ (0.02,0) [0|1.26] ""  EOCM_F_FO
 SG_ ObjLossInfoObjTrk6 : 49|2@0+ (1,0) [0|3] ""  EOCM_F_FO

BO_ 1321 F_Fwd_Fus_Obj_TrackB_9: 7 EOCM_F_FO
 SG_ FwdFusTrkBAnlgRlLn9 : 46|8@0- (0.1,0) [-12.8|12.7] ""  Dummy_FO
 SG_ FwdFusTrkB9RollingCnt : 7|2@0+ (1,0) [0|3] ""  Dummy_FO
 SG_ FwdFusTrkB9Width : 5|6@0+ (0.25,0) [0|15.75] "m"  Dummy_FO
 SG_ FwdFusTrkB9MsgIndex : 15|4@0+ (1,0) [0|15] ""  Dummy_FO
 SG_ FwdFusTrkB9DynProp : 11|3@0+ (1,0) [0|7] ""  Dummy_FO
 SG_ FwdFusTrkB9RelLnAccl : 8|9@0- (0.125,0) [-32|31.875] "m/s^2"  Dummy_FO
 SG_ FwdFusTrkB9RelLane : 31|2@0+ (1,0) [0|3] ""  Dummy_FO
 SG_ FwdFusTrkB9Height : 54|6@0+ (0.25,0) [0|15.75] "m"  Dummy_FO
 SG_ FFusTrkB9ObjSrcLFSrr : 29|1@0+ (1,0) [0|1] ""  Dummy_FO
 SG_ FFusTrkB9ObjSrcLCSrr : 28|1@0+ (1,0) [0|1] ""  Dummy_FO
 SG_ FFusTrkB9ObjSrcRCSrr : 27|1@0+ (1,0) [0|1] ""  Dummy_FO
 SG_ FFusTrkB9ObjSrcRFSrr : 26|1@0+ (1,0) [0|1] ""  Dummy_FO
 SG_ FFusTrkB9ObjSrcVIs : 25|1@0+ (1,0) [0|1] ""  Dummy_FO
 SG_ FwdFusTrkB9ObjSrcLrr : 24|1@0+ (1,0) [0|1] ""  Dummy_FO
 SG_ FwdFusTrkB9NmCycTrkd : 39|3@0+ (1,0) [0|7] ""  Dummy_FO
 SG_ FwdFusTrkB9LatPosDev : 36|3@0+ (1,0) [0|7] ""  Dummy_FO
 SG_ FwdFusTrkB9LngPosDev : 33|3@0+ (1,0) [0|7] ""  Dummy_FO

BO_ 1320 F_Fwd_Fus_Obj_TrackB_8: 7 EOCM_F_FO
 SG_ FwdFusTrkBAnlgRlLn8 : 46|8@0- (0.1,0) [-12.8|12.7] ""  Dummy_FO
 SG_ FwdFusTrkB8RollingCnt : 7|2@0+ (1,0) [0|3] ""  Dummy_FO
 SG_ FwdFusTrkB8Width : 5|6@0+ (0.25,0) [0|15.75] "m"  Dummy_FO
 SG_ FwdFusTrkB8MsgIndex : 15|4@0+ (1,0) [0|15] ""  Dummy_FO
 SG_ FwdFusTrkB8DynProp : 11|3@0+ (1,0) [0|7] ""  Dummy_FO
 SG_ FwdFusTrkB8RelLnAccl : 8|9@0- (0.125,0) [-32|31.875] "m/s^2"  Dummy_FO
 SG_ FwdFusTrkB8RelLane : 31|2@0+ (1,0) [0|3] ""  Dummy_FO
 SG_ FwdFusTrkB8Height : 54|6@0+ (0.25,0) [0|15.75] "m"  Dummy_FO
 SG_ FFusTrkB8ObjSrcLFSrr : 29|1@0+ (1,0) [0|1] ""  Dummy_FO
 SG_ FFusTrkB8ObjSrcLCSrr : 28|1@0+ (1,0) [0|1] ""  Dummy_FO
 SG_ FFusTrkB8ObjSrcRCSrr : 27|1@0+ (1,0) [0|1] ""  Dummy_FO
 SG_ FFusTrkB8ObjSrcRFSrr : 26|1@0+ (1,0) [0|1] ""  Dummy_FO
 SG_ FFusTrkB8ObjSrcVIs : 25|1@0+ (1,0) [0|1] ""  Dummy_FO
 SG_ FwdFusTrkB8ObjSrcLrr : 24|1@0+ (1,0) [0|1] ""  Dummy_FO
 SG_ FwdFusTrkB8NmCycTrkd : 39|3@0+ (1,0) [0|7] ""  Dummy_FO
 SG_ FwdFusTrkB8LatPosDev : 36|3@0+ (1,0) [0|7] ""  Dummy_FO
 SG_ FwdFusTrkB8LngPosDev : 33|3@0+ (1,0) [0|7] ""  Dummy_FO

BO_ 1319 F_Fwd_Fus_Obj_TrackB_7: 7 EOCM_F_FO
 SG_ FwdFusTrkBAnlgRlLn7 : 46|8@0- (0.1,0) [-12.8|12.7] ""  Dummy_FO
 SG_ FwdFusTrkB7RollingCnt : 7|2@0+ (1,0) [0|3] ""  Dummy_FO
 SG_ FwdFusTrkB7Width : 5|6@0+ (0.25,0) [0|15.75] "m"  Dummy_FO
 SG_ FwdFusTrkB7MsgIndex : 15|4@0+ (1,0) [0|15] ""  Dummy_FO
 SG_ FwdFusTrkB7DynProp : 11|3@0+ (1,0) [0|7] ""  Dummy_FO
 SG_ FwdFusTrkB7RelLnAccl : 8|9@0- (0.125,0) [-32|31.875] "m/s^2"  Dummy_FO
 SG_ FwdFusTrkB7RelLane : 31|2@0+ (1,0) [0|3] ""  Dummy_FO
 SG_ FwdFusTrkB7Height : 54|6@0+ (0.25,0) [0|15.75] "m"  Dummy_FO
 SG_ FFusTrkB7ObjSrcLFSrr : 29|1@0+ (1,0) [0|1] ""  Dummy_FO
 SG_ FFusTrkB7ObjSrcLCSrr : 28|1@0+ (1,0) [0|1] ""  Dummy_FO
 SG_ FFusTrkB7ObjSrcRCSrr : 27|1@0+ (1,0) [0|1] ""  Dummy_FO
 SG_ FFusTrkB7ObjSrcRFSrr : 26|1@0+ (1,0) [0|1] ""  Dummy_FO
 SG_ FFusTrkB7ObjSrcVIs : 25|1@0+ (1,0) [0|1] ""  Dummy_FO
 SG_ FwdFusTrkB7ObjSrcLrr : 24|1@0+ (1,0) [0|1] ""  Dummy_FO
 SG_ FwdFusTrkB7NmCycTrkd : 39|3@0+ (1,0) [0|7] ""  Dummy_FO
 SG_ FwdFusTrkB7LatPosDev : 36|3@0+ (1,0) [0|7] ""  Dummy_FO
 SG_ FwdFusTrkB7LngPosDev : 33|3@0+ (1,0) [0|7] ""  Dummy_FO

BO_ 1318 F_Fwd_Fus_Obj_TrackB_6: 7 EOCM_F_FO
 SG_ FwdFusTrkBAnlgRlLn6 : 46|8@0- (0.1,0) [-12.8|12.7] ""  Dummy_FO
 SG_ FwdFusTrkB6RollingCnt : 7|2@0+ (1,0) [0|3] ""  Dummy_FO
 SG_ FwdFusTrkB6Width : 5|6@0+ (0.25,0) [0|15.75] "m"  Dummy_FO
 SG_ FwdFusTrkB6MsgIndex : 15|4@0+ (1,0) [0|15] ""  Dummy_FO
 SG_ FwdFusTrkB6DynProp : 11|3@0+ (1,0) [0|7] ""  Dummy_FO
 SG_ FwdFusTrkB6RelLnAccl : 8|9@0- (0.125,0) [-32|31.875] "m/s^2"  Dummy_FO
 SG_ FwdFusTrkB6RelLane : 31|2@0+ (1,0) [0|3] ""  Dummy_FO
 SG_ FwdFusTrkB6Height : 54|6@0+ (0.25,0) [0|15.75] "m"  Dummy_FO
 SG_ FFusTrkB6ObjSrcLFSrr : 29|1@0+ (1,0) [0|1] ""  Dummy_FO
 SG_ FFusTrkB6ObjSrcLCSrr : 28|1@0+ (1,0) [0|1] ""  Dummy_FO
 SG_ FFusTrkB6ObjSrcRCSrr : 27|1@0+ (1,0) [0|1] ""  Dummy_FO
 SG_ FFusTrkB6ObjSrcRFSrr : 26|1@0+ (1,0) [0|1] ""  Dummy_FO
 SG_ FFusTrkB6ObjSrcVIs : 25|1@0+ (1,0) [0|1] ""  Dummy_FO
 SG_ FwdFusTrkB6ObjSrcLrr : 24|1@0+ (1,0) [0|1] ""  Dummy_FO
 SG_ FwdFusTrkB6NmCycTrkd : 39|3@0+ (1,0) [0|7] ""  Dummy_FO
 SG_ FwdFusTrkB6LatPosDev : 36|3@0+ (1,0) [0|7] ""  Dummy_FO
 SG_ FwdFusTrkB6LngPosDev : 33|3@0+ (1,0) [0|7] ""  Dummy_FO

BO_ 1317 F_Fwd_Fus_Obj_TrackB_5: 7 EOCM_F_FO
 SG_ FwdFusTrkBAnlgRlLn5 : 46|8@0- (0.1,0) [-12.8|12.7] ""  Dummy_FO
 SG_ FwdFusTrkB5RollingCnt : 7|2@0+ (1,0) [0|3] ""  Dummy_FO
 SG_ FwdFusTrkB5Width : 5|6@0+ (0.25,0) [0|15.75] "m"  Dummy_FO
 SG_ FwdFusTrkB5MsgIndex : 15|4@0+ (1,0) [0|15] ""  Dummy_FO
 SG_ FwdFusTrkB5DynProp : 11|3@0+ (1,0) [0|7] ""  Dummy_FO
 SG_ FwdFusTrkB5RelLnAccl : 8|9@0- (0.125,0) [-32|31.875] "m/s^2"  Dummy_FO
 SG_ FwdFusTrkB5RelLane : 31|2@0+ (1,0) [0|3] ""  Dummy_FO
 SG_ FwdFusTrkB5Height : 54|6@0+ (0.25,0) [0|15.75] "m"  Dummy_FO
 SG_ FFusTrkB5ObjSrcLFSrr : 29|1@0+ (1,0) [0|1] ""  Dummy_FO
 SG_ FFusTrkB5ObjSrcLCSrr : 28|1@0+ (1,0) [0|1] ""  Dummy_FO
 SG_ FFusTrkB5ObjSrcRCSrr : 27|1@0+ (1,0) [0|1] ""  Dummy_FO
 SG_ FFusTrkB5ObjSrcRFSrr : 26|1@0+ (1,0) [0|1] ""  Dummy_FO
 SG_ FFusTrkB5ObjSrcVIs : 25|1@0+ (1,0) [0|1] ""  Dummy_FO
 SG_ FwdFusTrkB5ObjSrcLrr : 24|1@0+ (1,0) [0|1] ""  Dummy_FO
 SG_ FwdFusTrkB5NmCycTrkd : 39|3@0+ (1,0) [0|7] ""  Dummy_FO
 SG_ FwdFusTrkB5LatPosDev : 36|3@0+ (1,0) [0|7] ""  Dummy_FO
 SG_ FwdFusTrkB5LngPosDev : 33|3@0+ (1,0) [0|7] ""  Dummy_FO

BO_ 1316 F_Fwd_Fus_Obj_TrackB_4: 7 EOCM_F_FO
 SG_ FwdFusTrkBAnlgRlLn4 : 46|8@0- (0.1,0) [-12.8|12.7] ""  Dummy_FO
 SG_ FwdFusTrkB4RollingCnt : 7|2@0+ (1,0) [0|3] ""  Dummy_FO
 SG_ FwdFusTrkB4Width : 5|6@0+ (0.25,0) [0|15.75] "m"  Dummy_FO
 SG_ FwdFusTrkB4MsgIndex : 15|4@0+ (1,0) [0|15] ""  Dummy_FO
 SG_ FwdFusTrkB4DynProp : 11|3@0+ (1,0) [0|7] ""  Dummy_FO
 SG_ FwdFusTrkB4RelLnAccl : 8|9@0- (0.125,0) [-32|31.875] "m/s^2"  Dummy_FO
 SG_ FwdFusTrkB4RelLane : 31|2@0+ (1,0) [0|3] ""  Dummy_FO
 SG_ FwdFusTrkB4Height : 54|6@0+ (0.25,0) [0|15.75] "m"  Dummy_FO
 SG_ FFusTrkB4ObjSrcLFSrr : 29|1@0+ (1,0) [0|1] ""  Dummy_FO
 SG_ FFusTrkB4ObjSrcLCSrr : 28|1@0+ (1,0) [0|1] ""  Dummy_FO
 SG_ FFusTrkB4ObjSrcRCSrr : 27|1@0+ (1,0) [0|1] ""  Dummy_FO
 SG_ FFusTrkB4ObjSrcRFSrr : 26|1@0+ (1,0) [0|1] ""  Dummy_FO
 SG_ FFusTrkB4ObjSrcVIs : 25|1@0+ (1,0) [0|1] ""  Dummy_FO
 SG_ FwdFusTrkB4ObjSrcLrr : 24|1@0+ (1,0) [0|1] ""  Dummy_FO
 SG_ FwdFusTrkB4NmCycTrkd : 39|3@0+ (1,0) [0|7] ""  Dummy_FO
 SG_ FwdFusTrkB4LatPosDev : 36|3@0+ (1,0) [0|7] ""  Dummy_FO
 SG_ FwdFusTrkB4LngPosDev : 33|3@0+ (1,0) [0|7] ""  Dummy_FO

BO_ 1315 F_Fwd_Fus_Obj_TrackB_3: 7 EOCM_F_FO
 SG_ FwdFusTrkBAnlgRlLn3 : 46|8@0- (0.1,0) [-12.8|12.7] ""  Dummy_FO
 SG_ FwdFusTrkB3RollingCnt : 7|2@0+ (1,0) [0|3] ""  Dummy_FO
 SG_ FwdFusTrkB3Width : 5|6@0+ (0.25,0) [0|15.75] "m"  Dummy_FO
 SG_ FwdFusTrkB3MsgIndex : 15|4@0+ (1,0) [0|15] ""  Dummy_FO
 SG_ FwdFusTrkB3DynProp : 11|3@0+ (1,0) [0|7] ""  Dummy_FO
 SG_ FwdFusTrkB3RelLnAccl : 8|9@0- (0.125,0) [-32|31.875] "m/s^2"  Dummy_FO
 SG_ FwdFusTrkB3RelLane : 31|2@0+ (1,0) [0|3] ""  Dummy_FO
 SG_ FwdFusTrkB3Height : 54|6@0+ (0.25,0) [0|15.75] "m"  Dummy_FO
 SG_ FFusTrkB3ObjSrcLFSrr : 29|1@0+ (1,0) [0|1] ""  Dummy_FO
 SG_ FFusTrkB3ObjSrcLCSrr : 28|1@0+ (1,0) [0|1] ""  Dummy_FO
 SG_ FFusTrkB3ObjSrcRCSrr : 27|1@0+ (1,0) [0|1] ""  Dummy_FO
 SG_ FFusTrkB3ObjSrcRFSrr : 26|1@0+ (1,0) [0|1] ""  Dummy_FO
 SG_ FFusTrkB3ObjSrcVIs : 25|1@0+ (1,0) [0|1] ""  Dummy_FO
 SG_ FwdFusTrkB3ObjSrcLrr : 24|1@0+ (1,0) [0|1] ""  Dummy_FO
 SG_ FwdFusTrkB3NmCycTrkd : 39|3@0+ (1,0) [0|7] ""  Dummy_FO
 SG_ FwdFusTrkB3LatPosDev : 36|3@0+ (1,0) [0|7] ""  Dummy_FO
 SG_ FwdFusTrkB3LngPosDev : 33|3@0+ (1,0) [0|7] ""  Dummy_FO

BO_ 1314 F_Fwd_Fus_Obj_TrackB_2: 7 EOCM_F_FO
 SG_ FwdFusTrkBAnlgRlLn2 : 46|8@0- (0.1,0) [-12.8|12.7] ""  Dummy_FO
 SG_ FwdFusTrkB2RollingCnt : 7|2@0+ (1,0) [0|3] ""  Dummy_FO
 SG_ FwdFusTrkB2Width : 5|6@0+ (0.25,0) [0|15.75] "m"  Dummy_FO
 SG_ FwdFusTrkB2MsgIndex : 15|4@0+ (1,0) [0|15] ""  Dummy_FO
 SG_ FwdFusTrkB2DynProp : 11|3@0+ (1,0) [0|7] ""  Dummy_FO
 SG_ FwdFusTrkB2RelLnAccl : 8|9@0- (0.125,0) [-32|31.875] "m/s^2"  Dummy_FO
 SG_ FwdFusTrkB2RelLane : 31|2@0+ (1,0) [0|3] ""  Dummy_FO
 SG_ FwdFusTrkB2Height : 54|6@0+ (0.25,0) [0|15.75] "m"  Dummy_FO
 SG_ FFusTrkB2ObjSrcLFSrr : 29|1@0+ (1,0) [0|1] ""  Dummy_FO
 SG_ FFusTrkB2ObjSrcLCSrr : 28|1@0+ (1,0) [0|1] ""  Dummy_FO
 SG_ FFusTrkB2ObjSrcRCSrr : 27|1@0+ (1,0) [0|1] ""  Dummy_FO
 SG_ FFusTrkB2ObjSrcRFSrr : 26|1@0+ (1,0) [0|1] ""  Dummy_FO
 SG_ FFusTrkB2ObjSrcVIs : 25|1@0+ (1,0) [0|1] ""  Dummy_FO
 SG_ FwdFusTrkB2ObjSrcLrr : 24|1@0+ (1,0) [0|1] ""  Dummy_FO
 SG_ FwdFusTrkB2NmCycTrkd : 39|3@0+ (1,0) [0|7] ""  Dummy_FO
 SG_ FwdFusTrkB2LatPosDev : 36|3@0+ (1,0) [0|7] ""  Dummy_FO
 SG_ FwdFusTrkB2LngPosDev : 33|3@0+ (1,0) [0|7] ""  Dummy_FO

BO_ 1327 F_Fwd_Fus_Obj_TrackB_15: 7 EOCM_F_FO
 SG_ FwdFusTrkBAnlgRlLn15 : 46|8@0- (0.1,0) [-12.8|12.7] ""  Dummy_FO
 SG_ FwdFusTrkB15RollingCnt : 7|2@0+ (1,0) [0|3] ""  Dummy_FO
 SG_ FwdFusTrkB15Width : 5|6@0+ (0.25,0) [0|15.75] "m"  Dummy_FO
 SG_ FwdFusTrkB15MsgIndex : 15|4@0+ (1,0) [0|15] ""  Dummy_FO
 SG_ FwdFusTrkB15DynProp : 11|3@0+ (1,0) [0|7] ""  Dummy_FO
 SG_ FwdFusTrkB15RelLnAccl : 8|9@0- (0.125,0) [-32|31.875] "m/s^2"  Dummy_FO
 SG_ FwdFusTrkB15RelLane : 31|2@0+ (1,0) [0|3] ""  Dummy_FO
 SG_ FwdFusTrkB15Height : 54|6@0+ (0.25,0) [0|15.75] "m"  Dummy_FO
 SG_ FFusTrkB15ObjSrcLFSrr : 29|1@0+ (1,0) [0|1] ""  Dummy_FO
 SG_ FFusTrkB15ObjSrcLCSrr : 28|1@0+ (1,0) [0|1] ""  Dummy_FO
 SG_ FFusTrkB15ObjSrcRCSrr : 27|1@0+ (1,0) [0|1] ""  Dummy_FO
 SG_ FFusTrkB15ObjSrcRFSrr : 26|1@0+ (1,0) [0|1] ""  Dummy_FO
 SG_ FFusTkB15ObjSrcVIs : 25|1@0+ (1,0) [0|1] ""  Dummy_FO
 SG_ FwdFusTrkB15ObjSrcLrr : 24|1@0+ (1,0) [0|1] ""  Dummy_FO
 SG_ FwdFusTrkB15NmCycTrkd : 39|3@0+ (1,0) [0|7] ""  Dummy_FO
 SG_ FwdFusTrkB15LatPosDev : 36|3@0+ (1,0) [0|7] ""  Dummy_FO
 SG_ FwdFusTrkB15LngPosDev : 33|3@0+ (1,0) [0|7] ""  Dummy_FO

BO_ 1326 F_Fwd_Fus_Obj_TrackB_14: 7 EOCM_F_FO
 SG_ FwdFusTrkBAnlgRlLn14 : 46|8@0- (0.1,0) [-12.8|12.7] ""  Dummy_FO
 SG_ FwdFusTrkB14RollingCnt : 7|2@0+ (1,0) [0|3] ""  Dummy_FO
 SG_ FwdFusTrkB14Width : 5|6@0+ (0.25,0) [0|15.75] "m"  Dummy_FO
 SG_ FwdFusTrkB14MsgIndex : 15|4@0+ (1,0) [0|15] ""  Dummy_FO
 SG_ FwdFusTrkB14DynProp : 11|3@0+ (1,0) [0|7] ""  Dummy_FO
 SG_ FwdFusTrkB14RelLnAccl : 8|9@0- (0.125,0) [-32|31.875] "m/s^2"  Dummy_FO
 SG_ FwdFusTrkB14RelLane : 31|2@0+ (1,0) [0|3] ""  Dummy_FO
 SG_ FwdFusTrkB14Height : 54|6@0+ (0.25,0) [0|15.75] "m"  Dummy_FO
 SG_ FFusTrkB14ObjSrcLFSrr : 29|1@0+ (1,0) [0|1] ""  Dummy_FO
 SG_ FFusTrkB14ObjSrcLCSrr : 28|1@0+ (1,0) [0|1] ""  Dummy_FO
 SG_ FFusTrkB14ObjSrcRCSrr : 27|1@0+ (1,0) [0|1] ""  Dummy_FO
 SG_ FFusTrkB14ObjSrcRFSrr : 26|1@0+ (1,0) [0|1] ""  Dummy_FO
 SG_ FFusTrkB14ObjSrcVIs : 25|1@0+ (1,0) [0|1] ""  Dummy_FO
 SG_ FwdFusTrkB14ObjSrcLrr : 24|1@0+ (1,0) [0|1] ""  Dummy_FO
 SG_ FwdFusTrkB14NmCycTrkd : 39|3@0+ (1,0) [0|7] ""  Dummy_FO
 SG_ FwdFusTrkB14LatPosDev : 36|3@0+ (1,0) [0|7] ""  Dummy_FO
 SG_ FwdFusTrkB14LngPosDev : 33|3@0+ (1,0) [0|7] ""  Dummy_FO

BO_ 1325 F_Fwd_Fus_Obj_TrackB_13: 7 EOCM_F_FO
 SG_ FwdFusTrkBAnlgRlLn13 : 46|8@0- (0.1,0) [-12.8|12.7] ""  Dummy_FO
 SG_ FwdFusTrkB13RollingCnt : 7|2@0+ (1,0) [0|3] ""  Dummy_FO
 SG_ FwdFusTrkB13Width : 5|6@0+ (0.25,0) [0|15.75] "m"  Dummy_FO
 SG_ FwdFusTrkB13MsgIndex : 15|4@0+ (1,0) [0|15] ""  Dummy_FO
 SG_ FwdFusTrkB13DynProp : 11|3@0+ (1,0) [0|7] ""  Dummy_FO
 SG_ FwdFusTrkB13RelLnAccl : 8|9@0- (0.125,0) [-32|31.875] "m/s^2"  Dummy_FO
 SG_ FwdFusTrkB13RelLane : 31|2@0+ (1,0) [0|3] ""  Dummy_FO
 SG_ FwdFusTrkB13Height : 54|6@0+ (0.25,0) [0|15.75] "m"  Dummy_FO
 SG_ FFusTrkB13ObjSrcLFSrr : 29|1@0+ (1,0) [0|1] ""  Dummy_FO
 SG_ FFusTrkB13ObjSrcLCSrr : 28|1@0+ (1,0) [0|1] ""  Dummy_FO
 SG_ FFusTrkB13ObjSrcRCSrr : 27|1@0+ (1,0) [0|1] ""  Dummy_FO
 SG_ FFusTrkB13ObjSrcRFSrr : 26|1@0+ (1,0) [0|1] ""  Dummy_FO
 SG_ FFusTrkB13ObjSrcVIs : 25|1@0+ (1,0) [0|1] ""  Dummy_FO
 SG_ FwdFusTrkB13ObjSrcLrr : 24|1@0+ (1,0) [0|1] ""  Dummy_FO
 SG_ FwdFusTrkB13NmCycTrkd : 39|3@0+ (1,0) [0|7] ""  Dummy_FO
 SG_ FwdFusTrkB13LatPosDev : 36|3@0+ (1,0) [0|7] ""  Dummy_FO
 SG_ FwdFusTrkB13LngPosDev : 33|3@0+ (1,0) [0|7] ""  Dummy_FO

BO_ 1324 F_Fwd_Fus_Obj_TrackB_12: 7 EOCM_F_FO
 SG_ FwdFusTrkBAnlgRlLn12 : 46|8@0- (0.1,0) [-12.8|12.7] ""  Dummy_FO
 SG_ FwdFusTrkB12RollingCnt : 7|2@0+ (1,0) [0|3] ""  Dummy_FO
 SG_ FwdFusTrkB12Width : 5|6@0+ (0.25,0) [0|15.75] "m"  Dummy_FO
 SG_ FwdFusTrkB12MsgIndex : 15|4@0+ (1,0) [0|15] ""  Dummy_FO
 SG_ FwdFusTrkB12DynProp : 11|3@0+ (1,0) [0|7] ""  Dummy_FO
 SG_ FwdFusTrkB12RelLnAccl : 8|9@0- (0.125,0) [-32|31.875] "m/s^2"  Dummy_FO
 SG_ FwdFusTrkB12RelLane : 31|2@0+ (1,0) [0|3] ""  Dummy_FO
 SG_ FwdFusTrkB12Height : 54|6@0+ (0.25,0) [0|15.75] "m"  Dummy_FO
 SG_ FFusTrkB12ObjSrcLFSrr : 29|1@0+ (1,0) [0|1] ""  Dummy_FO
 SG_ FFusTrkB12ObjSrcLCSrr : 28|1@0+ (1,0) [0|1] ""  Dummy_FO
 SG_ FFusTrkB12ObjSrcRCSrr : 27|1@0+ (1,0) [0|1] ""  Dummy_FO
 SG_ FFusTrkB12ObjSrcRFSrr : 26|1@0+ (1,0) [0|1] ""  Dummy_FO
 SG_ FFusTrkB12ObjSrcVIs : 25|1@0+ (1,0) [0|1] ""  Dummy_FO
 SG_ FwdFusTrkB12ObjSrcLrr : 24|1@0+ (1,0) [0|1] ""  Dummy_FO
 SG_ FwdFusTrkB12NmCycTrkd : 39|3@0+ (1,0) [0|7] ""  Dummy_FO
 SG_ FwdFusTrkB12LatPosDev : 36|3@0+ (1,0) [0|7] ""  Dummy_FO
 SG_ FwdFusTrkB12LngPosDev : 33|3@0+ (1,0) [0|7] ""  Dummy_FO

BO_ 1323 F_Fwd_Fus_Obj_TrackB_11: 7 EOCM_F_FO
 SG_ FwdFusTrkB11DynProp : 11|3@0+ (1,0) [0|7] ""  Dummy_FO
 SG_ FwdFusTrkB11RelLnAccl : 8|9@0- (0.125,0) [-32|31.875] "m/s^2"  Dummy_FO
 SG_ FwdFusTrkB11RelLane : 31|2@0+ (1,0) [0|3] ""  Dummy_FO
 SG_ FwdFusTrkB11Height : 54|6@0+ (0.25,0) [0|15.75] "m"  Dummy_FO
 SG_ FFusTrkB11ObjSrcLFSrr : 29|1@0+ (1,0) [0|1] ""  Dummy_FO
 SG_ FFusTrkB11ObjSrcLCSrr : 28|1@0+ (1,0) [0|1] ""  Dummy_FO
 SG_ FFusTrkB11ObjSrcRCSrr : 27|1@0+ (1,0) [0|1] ""  Dummy_FO
 SG_ FFusTrkB11ObjSrcRFSrr : 26|1@0+ (1,0) [0|1] ""  Dummy_FO
 SG_ FFusTrkB11ObjSrcVIs : 25|1@0+ (1,0) [0|1] ""  Dummy_FO
 SG_ FwdFusTrkB11ObjSrcLrr : 24|1@0+ (1,0) [0|1] ""  Dummy_FO
 SG_ FwdFusTrkB11NmCycTrkd : 39|3@0+ (1,0) [0|7] ""  Dummy_FO
 SG_ FwdFusTrkB11LatPosDev : 36|3@0+ (1,0) [0|7] ""  Dummy_FO
 SG_ FwdFusTrkB11LngPosDev : 33|3@0+ (1,0) [0|7] ""  Dummy_FO
 SG_ FwdFusTrkBAnlgRlLn11 : 46|8@0- (0.1,0) [-12.8|12.7] ""  Dummy_FO
 SG_ FwdFusTrkB11RollingCnt : 7|2@0+ (1,0) [0|3] ""  Dummy_FO
 SG_ FwdFusTrkB11Width : 5|6@0+ (0.25,0) [0|15.75] "m"  Dummy_FO
 SG_ FwdFusTrkB11MsgIndex : 15|4@0+ (1,0) [0|15] ""  Dummy_FO

BO_ 1322 F_Fwd_Fus_Obj_TrackB_10: 7 EOCM_F_FO
 SG_ FwdFusTrkBAnlgRlLn10 : 46|8@0- (0.1,0) [-12.8|12.7] ""  Dummy_FO
 SG_ FwdFusTrkB10RollingCnt : 7|2@0+ (1,0) [0|3] ""  Dummy_FO
 SG_ FwdFusTrkB10Width : 5|6@0+ (0.25,0) [0|15.75] "m"  Dummy_FO
 SG_ FwdFusTrkB10MsgIndex : 15|4@0+ (1,0) [0|15] ""  Dummy_FO
 SG_ FwdFusTrkB10DynProp : 11|3@0+ (1,0) [0|7] ""  Dummy_FO
 SG_ FwdFusTrkB10RelLnAccl : 8|9@0- (0.125,0) [-32|31.875] "m/s^2"  Dummy_FO
 SG_ FwdFusTrkB10RelLane : 31|2@0+ (1,0) [0|3] ""  Dummy_FO
 SG_ FwdFusTrkB10Height : 54|6@0+ (0.25,0) [0|15.75] "m"  Dummy_FO
 SG_ FFusTrkB10ObjSrcLFSrr : 29|1@0+ (1,0) [0|1] ""  Dummy_FO
 SG_ FFusTrkB10ObjSrcLCSrr : 28|1@0+ (1,0) [0|1] ""  Dummy_FO
 SG_ FFusTrkB10ObjSrcRCSrr : 27|1@0+ (1,0) [0|1] ""  Dummy_FO
 SG_ FFusTrkB10ObjSrcRFSrr : 26|1@0+ (1,0) [0|1] ""  Dummy_FO
 SG_ FFusTrkB10ObjSrcVIs : 25|1@0+ (1,0) [0|1] ""  Dummy_FO
 SG_ FwdFusTrkB10ObjSrcLrr : 24|1@0+ (1,0) [0|1] ""  Dummy_FO
 SG_ FwdFusTrkB10NmCycTrkd : 39|3@0+ (1,0) [0|7] ""  Dummy_FO
 SG_ FwdFusTrkB10LatPosDev : 36|3@0+ (1,0) [0|7] ""  Dummy_FO
 SG_ FwdFusTrkB10LngPosDev : 33|3@0+ (1,0) [0|7] ""  Dummy_FO

BO_ 1313 F_Fwd_Fus_Obj_TrackB_1: 7 EOCM_F_FO
 SG_ FwdFusTrkBAnlgRlLn1 : 46|8@0- (0.1,0) [-12.8|12.7] ""  Dummy_FO
 SG_ FwdFusTrkB1RollingCnt : 7|2@0+ (1,0) [0|3] ""  Dummy_FO
 SG_ FwdFusTrkB1Width : 5|6@0+ (0.25,0) [0|15.75] "m"  Dummy_FO
 SG_ FwdFusTrkB1MsgIndex : 15|4@0+ (1,0) [0|15] ""  Dummy_FO
 SG_ FwdFusTrkB1DynProp : 11|3@0+ (1,0) [0|7] ""  Dummy_FO
 SG_ FwdFusTrkB1RelLnAccl : 8|9@0- (0.125,0) [-32|31.875] "m/s^2"  Dummy_FO
 SG_ FwdFusTrkB1RelLane : 31|2@0+ (1,0) [0|3] ""  Dummy_FO
 SG_ FwdFusTrkB1Height : 54|6@0+ (0.25,0) [0|15.75] "m"  Dummy_FO
 SG_ FFusTrkB1ObjSrcLFSrr : 29|1@0+ (1,0) [0|1] ""  Dummy_FO
 SG_ FFusTrkB1ObjSrcLCSrr : 28|1@0+ (1,0) [0|1] ""  Dummy_FO
 SG_ FFusTrkB1ObjSrcRCSrr : 27|1@0+ (1,0) [0|1] ""  Dummy_FO
 SG_ FFusTrkB1ObjSrcRFSrr : 26|1@0+ (1,0) [0|1] ""  Dummy_FO
 SG_ FFusTrkB1ObjSrcVIs : 25|1@0+ (1,0) [0|1] ""  Dummy_FO
 SG_ FwdFusTrkB1ObjSrcLrr : 24|1@0+ (1,0) [0|1] ""  Dummy_FO
 SG_ FwdFusTrkB1NmCycTrkd : 39|3@0+ (1,0) [0|7] ""  Dummy_FO
 SG_ FwdFusTrkB1LatPosDev : 36|3@0+ (1,0) [0|7] ""  Dummy_FO
 SG_ FwdFusTrkB1LngPosDev : 33|3@0+ (1,0) [0|7] ""  Dummy_FO

BO_ 1305 F_Fwd_Fus_Obj_TrackA_9: 8 EOCM_F_FO
 SG_ FwdFusTrkA9RollingCnt : 7|2@0+ (1,0) [0|3] ""  Dummy_FO
 SG_ FwdFusTrkA9ObjectID : 5|6@0+ (1,0) [0|63] ""  Dummy_FO
 SG_ FwdFusTrkA9MsgIndex : 15|4@0+ (1,0) [0|15] ""  Dummy_FO
 SG_ FwdFusTrkA9LongPos : 11|12@0- (0.125,0) [-256|255.875] "m"  Dummy_FO
 SG_ FwdFusTrkA9RelLongVel : 31|11@0- (0.125,0) [-128|127.875] "m/s"  Dummy_FO
 SG_ FwdFusTrkA9Confidence : 36|2@0+ (1,0) [0|3] ""  Dummy_FO
 SG_ FwdFusTrkA9LatPos : 34|11@0- (0.125,0) [-128|127.875] "m"  Dummy_FO
 SG_ FwdFusTrkA9RelLatVel : 55|11@0- (0.125,0) [-128|127.875] "m/s"  Dummy_FO
 SG_ FwdFusTrkA9MeasStatus : 60|2@0+ (1,0) [0|3] ""  Dummy_FO
 SG_ FwdFusTrkA9ObjType : 58|3@0+ (1,0) [0|7] ""  Dummy_FO

BO_ 1304 F_Fwd_Fus_Obj_TrackA_8: 8 EOCM_F_FO
 SG_ FwdFusTrkA8RollingCnt : 7|2@0+ (1,0) [0|3] ""  Dummy_FO
 SG_ FwdFusTrkA8ObjectID : 5|6@0+ (1,0) [0|63] ""  Dummy_FO
 SG_ FwdFusTrkA8MsgIndex : 15|4@0+ (1,0) [0|15] ""  Dummy_FO
 SG_ FwdFusTrkA8LongPos : 11|12@0- (0.125,0) [-256|255.875] "m"  Dummy_FO
 SG_ FwdFusTrkA8RelLongVel : 31|11@0- (0.125,0) [-128|127.875] "m/s"  Dummy_FO
 SG_ FwdFusTrkA8Confidence : 36|2@0+ (1,0) [0|3] ""  Dummy_FO
 SG_ FwdFusTrkA8LatPos : 34|11@0- (0.125,0) [-128|127.875] "m"  Dummy_FO
 SG_ FwdFusTrkA8RelLatVel : 55|11@0- (0.125,0) [-128|127.875] "m/s"  Dummy_FO
 SG_ FwdFusTrkA8MeasStatus : 60|2@0+ (1,0) [0|3] ""  Dummy_FO
 SG_ FwdFusTrkA8ObjType : 58|3@0+ (1,0) [0|7] ""  Dummy_FO

BO_ 1303 F_Fwd_Fus_Obj_TrackA_7: 8 EOCM_F_FO
 SG_ FwdFusTrkA7RollingCnt : 7|2@0+ (1,0) [0|3] ""  Dummy_FO
 SG_ FwdFusTrkA7ObjectID : 5|6@0+ (1,0) [0|63] ""  Dummy_FO
 SG_ FwdFusTrkA7MsgIndex : 15|4@0+ (1,0) [0|15] ""  Dummy_FO
 SG_ FwdFusTrkA7LongPos : 11|12@0- (0.125,0) [-256|255.875] "m"  Dummy_FO
 SG_ FwdFusTrkA7RelLongVel : 31|11@0- (0.125,0) [-128|127.875] "m/s"  Dummy_FO
 SG_ FwdFusTrkA7Confidence : 36|2@0+ (1,0) [0|3] ""  Dummy_FO
 SG_ FwdFusTrkA7LatPos : 34|11@0- (0.125,0) [-128|127.875] "m"  Dummy_FO
 SG_ FwdFusTrkA7RelLatVel : 55|11@0- (0.125,0) [-128|127.875] "m/s"  Dummy_FO
 SG_ FwdFusTrkA7MeasStatus : 60|2@0+ (1,0) [0|3] ""  Dummy_FO
 SG_ FwdFusTrkA7ObjType : 58|3@0+ (1,0) [0|7] ""  Dummy_FO

BO_ 1302 F_Fwd_Fus_Obj_TrackA_6: 8 EOCM_F_FO
 SG_ FwdFusTrkA6RollingCnt : 7|2@0+ (1,0) [0|3] ""  Dummy_FO
 SG_ FwdFusTrkA6ObjectID : 5|6@0+ (1,0) [0|63] ""  Dummy_FO
 SG_ FwdFusTrkA6MsgIndex : 15|4@0+ (1,0) [0|15] ""  Dummy_FO
 SG_ FwdFusTrkA6LongPos : 11|12@0- (0.125,0) [-256|255.875] "m"  Dummy_FO
 SG_ FwdFusTrkA6RelLongVel : 31|11@0- (0.125,0) [-128|127.875] "m/s"  Dummy_FO
 SG_ FwdFusTrkA6Confidence : 36|2@0+ (1,0) [0|3] ""  Dummy_FO
 SG_ FwdFusTrkA6LatPos : 34|11@0- (0.125,0) [-128|127.875] "m"  Dummy_FO
 SG_ FwdFusTrkA6RelLatVel : 55|11@0- (0.125,0) [-128|127.875] "m/s"  Dummy_FO
 SG_ FwdFusTrkA6MeasStatus : 60|2@0+ (1,0) [0|3] ""  Dummy_FO
 SG_ FwdFusTrkA6ObjType : 58|3@0+ (1,0) [0|7] ""  Dummy_FO

BO_ 1301 F_Fwd_Fus_Obj_TrackA_5: 8 EOCM_F_FO
 SG_ FwdFusTrkA5RollingCnt : 7|2@0+ (1,0) [0|3] ""  Dummy_FO
 SG_ FwdFusTrkA5ObjectID : 5|6@0+ (1,0) [0|63] ""  Dummy_FO
 SG_ FwdFusTrkA5MsgIndex : 15|4@0+ (1,0) [0|15] ""  Dummy_FO
 SG_ FwdFusTrkA5LongPos : 11|12@0- (0.125,0) [-256|255.875] "m"  Dummy_FO
 SG_ FwdFusTrkA5RelLongVel : 31|11@0- (0.125,0) [-128|127.875] "m/s"  Dummy_FO
 SG_ FwdFusTrkA5Confidence : 36|2@0+ (1,0) [0|3] ""  Dummy_FO
 SG_ FwdFusTrkA5LatPos : 34|11@0- (0.125,0) [-128|127.875] "m"  Dummy_FO
 SG_ FwdFusTrkA5RelLatVel : 55|11@0- (0.125,0) [-128|127.875] "m/s"  Dummy_FO
 SG_ FwdFusTrkA5MeasStatus : 60|2@0+ (1,0) [0|3] ""  Dummy_FO
 SG_ FwdFusTrkA5ObjType : 58|3@0+ (1,0) [0|7] ""  Dummy_FO

BO_ 1300 F_Fwd_Fus_Obj_TrackA_4: 8 EOCM_F_FO
 SG_ FwdFusTrkA4RollingCnt : 7|2@0+ (1,0) [0|3] ""  Dummy_FO
 SG_ FwdFusTrkA4ObjectID : 5|6@0+ (1,0) [0|63] ""  Dummy_FO
 SG_ FwdFusTrkA4MsgIndex : 15|4@0+ (1,0) [0|15] ""  Dummy_FO
 SG_ FwdFusTrkA4LongPos : 11|12@0- (0.125,0) [-256|255.875] "m"  Dummy_FO
 SG_ FwdFusTrkA4RelLongVel : 31|11@0- (0.125,0) [-128|127.875] "m/s"  Dummy_FO
 SG_ FwdFusTrkA4Confidence : 36|2@0+ (1,0) [0|3] ""  Dummy_FO
 SG_ FwdFusTrkA4LatPos : 34|11@0- (0.125,0) [-128|127.875] "m"  Dummy_FO
 SG_ FwdFusTrkA4RelLatVel : 55|11@0- (0.125,0) [-128|127.875] "m/s"  Dummy_FO
 SG_ FwdFusTrkA4MeasStatus : 60|2@0+ (1,0) [0|3] ""  Dummy_FO
 SG_ FwdFusTrkA4ObjType : 58|3@0+ (1,0) [0|7] ""  Dummy_FO

BO_ 1299 F_Fwd_Fus_Obj_TrackA_3: 8 EOCM_F_FO
 SG_ FwdFusTrkA3RollingCnt : 7|2@0+ (1,0) [0|3] ""  Dummy_FO
 SG_ FwdFusTrkA3ObjectID : 5|6@0+ (1,0) [0|63] ""  Dummy_FO
 SG_ FwdFusTrkA3MsgIndex : 15|4@0+ (1,0) [0|15] ""  Dummy_FO
 SG_ FwdFusTrkA3LongPos : 11|12@0- (0.125,0) [-256|255.875] "m"  Dummy_FO
 SG_ FwdFusTrkA3RelLongVel : 31|11@0- (0.125,0) [-128|127.875] "m/s"  Dummy_FO
 SG_ FwdFusTrkA3Confidence : 36|2@0+ (1,0) [0|3] ""  Dummy_FO
 SG_ FwdFusTrkA3LatPos : 34|11@0- (0.125,0) [-128|127.875] "m"  Dummy_FO
 SG_ FwdFusTrkA3RelLatVel : 55|11@0- (0.125,0) [-128|127.875] "m/s"  Dummy_FO
 SG_ FwdFusTrkA3MeasStatus : 60|2@0+ (1,0) [0|3] ""  Dummy_FO
 SG_ FwdFusTrkA3ObjType : 58|3@0+ (1,0) [0|7] ""  Dummy_FO

BO_ 1298 F_Fwd_Fus_Obj_TrackA_2: 8 EOCM_F_FO
 SG_ FwdFusTrkA2RollingCnt : 7|2@0+ (1,0) [0|3] ""  Dummy_FO
 SG_ FwdFusTrkA2ObjectID : 5|6@0+ (1,0) [0|63] ""  Dummy_FO
 SG_ FwdFusTrkA2MsgIndex : 15|4@0+ (1,0) [0|15] ""  Dummy_FO
 SG_ FwdFusTrkA2LongPos : 11|12@0- (0.125,0) [-256|255.875] "m"  Dummy_FO
 SG_ FwdFusTrkA2RelLongVel : 31|11@0- (0.125,0) [-128|127.875] "m/s"  Dummy_FO
 SG_ FwdFusTrkA2Confidence : 36|2@0+ (1,0) [0|3] ""  Dummy_FO
 SG_ FwdFusTrkA2LatPos : 34|11@0- (0.125,0) [-128|127.875] "m"  Dummy_FO
 SG_ FwdFusTrkA2RelLatVel : 55|11@0- (0.125,0) [-128|127.875] "m/s"  Dummy_FO
 SG_ FwdFusTrkA2MeasStatus : 60|2@0+ (1,0) [0|3] ""  Dummy_FO
 SG_ FwdFusTrkA2ObjType : 58|3@0+ (1,0) [0|7] ""  Dummy_FO

BO_ 1311 F_Fwd_Fus_Obj_TrackA_15: 8 EOCM_F_FO
 SG_ FwdFusTrkA15RollingCnt : 7|2@0+ (1,0) [0|3] ""  Dummy_FO
 SG_ FwdFusTrkA15ObjectID : 5|6@0+ (1,0) [0|63] ""  Dummy_FO
 SG_ FwdFusTrkA15MsgIndex : 15|4@0+ (1,0) [0|15] ""  Dummy_FO
 SG_ FwdFusTrkA15LongPos : 11|12@0- (0.125,0) [-256|255.875] "m"  Dummy_FO
 SG_ FwdFusTrkA15RelLongVel : 31|11@0- (0.125,0) [-128|127.875] "m/s"  Dummy_FO
 SG_ FwdFusTrkA15Confidence : 36|2@0+ (1,0) [0|3] ""  Dummy_FO
 SG_ FwdFusTrkA15LatPos : 34|11@0- (0.125,0) [-128|127.875] "m"  Dummy_FO
 SG_ FwdFusTrkA15RelLatVel : 55|11@0- (0.125,0) [-128|127.875] "m/s"  Dummy_FO
 SG_ FwdFusTrkA15MeasStatus : 60|2@0+ (1,0) [0|3] ""  Dummy_FO
 SG_ FwdFusTrkA15ObjType : 58|3@0+ (1,0) [0|7] ""  Dummy_FO

BO_ 1310 F_Fwd_Fus_Obj_TrackA_14: 8 EOCM_F_FO
 SG_ FwdFusTrkA14RollingCnt : 7|2@0+ (1,0) [0|3] ""  Dummy_FO
 SG_ FwdFusTrkA14ObjectID : 5|6@0+ (1,0) [0|63] ""  Dummy_FO
 SG_ FwdFusTrkA14MsgIndex : 15|4@0+ (1,0) [0|15] ""  Dummy_FO
 SG_ FwdFusTrkA14LongPos : 11|12@0- (0.125,0) [-256|255.875] "m"  Dummy_FO
 SG_ FwdFusTrkA14RelLongVel : 31|11@0- (0.125,0) [-128|127.875] "m/s"  Dummy_FO
 SG_ FwdFusTrkA14Confidence : 36|2@0+ (1,0) [0|3] ""  Dummy_FO
 SG_ FwdFusTrkA14LatPos : 34|11@0- (0.125,0) [-128|127.875] "m"  Dummy_FO
 SG_ FwdFusTrkA14RelLatVel : 55|11@0- (0.125,0) [-128|127.875] "m/s"  Dummy_FO
 SG_ FwdFusTrkA14MeasStatus : 60|2@0+ (1,0) [0|3] ""  Dummy_FO
 SG_ FwdFusTrkA14ObjType : 58|3@0+ (1,0) [0|7] ""  Dummy_FO

BO_ 1309 F_Fwd_Fus_Obj_TrackA_13: 8 EOCM_F_FO
 SG_ FwdFusTrkA13RollingCnt : 7|2@0+ (1,0) [0|3] ""  Dummy_FO
 SG_ FwdFusTrkA13ObjectID : 5|6@0+ (1,0) [0|63] ""  Dummy_FO
 SG_ FwdFusTrkA13MsgIndex : 15|4@0+ (1,0) [0|15] ""  Dummy_FO
 SG_ FwdFusTrkA13LongPos : 11|12@0- (0.125,0) [-256|255.875] "m"  Dummy_FO
 SG_ FwdFusTrkA13RelLongVel : 31|11@0- (0.125,0) [-128|127.875] "m/s"  Dummy_FO
 SG_ FwdFusTrkA13Confidence : 36|2@0+ (1,0) [0|3] ""  Dummy_FO
 SG_ FwdFusTrkA13LatPos : 34|11@0- (0.125,0) [-128|127.875] "m"  Dummy_FO
 SG_ FwdFusTrkA13RelLatVel : 55|11@0- (0.125,0) [-128|127.875] "m/s"  Dummy_FO
 SG_ FwdFusTrkA13MeasStatus : 60|2@0+ (1,0) [0|3] ""  Dummy_FO
 SG_ FwdFusTrkA13ObjType : 58|3@0+ (1,0) [0|7] ""  Dummy_FO

BO_ 1308 F_Fwd_Fus_Obj_TrackA_12: 8 EOCM_F_FO
 SG_ FwdFusTrkA12RollingCnt : 7|2@0+ (1,0) [0|3] ""  Dummy_FO
 SG_ FwdFusTrkA12ObjectID : 5|6@0+ (1,0) [0|63] ""  Dummy_FO
 SG_ FwdFusTrkA12MsgIndex : 15|4@0+ (1,0) [0|15] ""  Dummy_FO
 SG_ FwdFusTrkA12LongPos : 11|12@0- (0.125,0) [-256|255.875] "m"  Dummy_FO
 SG_ FwdFusTrkA12RelLongVel : 31|11@0- (0.125,0) [-128|127.875] "m/s"  Dummy_FO
 SG_ FwdFusTrkA12Confidence : 36|2@0+ (1,0) [0|3] ""  Dummy_FO
 SG_ FwdFusTrkA12LatPos : 34|11@0- (0.125,0) [-128|127.875] "m"  Dummy_FO
 SG_ FwdFusTrkA12RelLatVel : 55|11@0- (0.125,0) [-128|127.875] "m/s"  Dummy_FO
 SG_ FwdFusTrkA12MeasStatus : 60|2@0+ (1,0) [0|3] ""  Dummy_FO
 SG_ FwdFusTrkA12ObjType : 58|3@0+ (1,0) [0|7] ""  Dummy_FO

BO_ 1307 F_Fwd_Fus_Obj_TrackA_11: 8 EOCM_F_FO
 SG_ FwdFusTrkA11ObjectID : 5|6@0+ (1,0) [0|63] ""  Dummy_FO
 SG_ FwdFusTrkA11MsgIndex : 15|4@0+ (1,0) [0|15] ""  Dummy_FO
 SG_ FwdFusTrkA11LongPos : 11|12@0- (0.125,0) [-256|255.875] "m"  Dummy_FO
 SG_ FwdFusTrkA11RelLongVel : 31|11@0- (0.125,0) [-128|127.875] "m/s"  Dummy_FO
 SG_ FwdFusTrkA11Confidence : 36|2@0+ (1,0) [0|3] ""  Dummy_FO
 SG_ FwdFusTrkA11LatPos : 34|11@0- (0.125,0) [-128|127.875] "m"  Dummy_FO
 SG_ FwdFusTrkA11RelLatVel : 55|11@0- (0.125,0) [-128|127.875] "m/s"  Dummy_FO
 SG_ FwdFusTrkA11MeasStatus : 60|2@0+ (1,0) [0|3] ""  Dummy_FO
 SG_ FwdFusTrkA11ObjType : 58|3@0+ (1,0) [0|7] ""  Dummy_FO
 SG_ FwdFusTrkA11RollingCnt : 7|2@0+ (1,0) [0|3] ""  Dummy_FO

BO_ 1306 F_Fwd_Fus_Obj_TrackA_10: 8 EOCM_F_FO
 SG_ FwdFusTrkA10RollingCnt : 7|2@0+ (1,0) [0|3] ""  Dummy_FO
 SG_ FwdFusTrkA10ObjectID : 5|6@0+ (1,0) [0|63] ""  Dummy_FO
 SG_ FwdFusTrkA10MsgIndex : 15|4@0+ (1,0) [0|15] ""  Dummy_FO
 SG_ FwdFusTrkA10LongPos : 11|12@0- (0.125,0) [-256|255.875] "m"  Dummy_FO
 SG_ FwdFusTrkA10RelLongVel : 31|11@0- (0.125,0) [-128|127.875] "m/s"  Dummy_FO
 SG_ FwdFusTrkA10Confidence : 36|2@0+ (1,0) [0|3] ""  Dummy_FO
 SG_ FwdFusTrkA10LatPos : 34|11@0- (0.125,0) [-128|127.875] "m"  Dummy_FO
 SG_ FwdFusTrkA10RelLatVel : 55|11@0- (0.125,0) [-128|127.875] "m/s"  Dummy_FO
 SG_ FwdFusTrkA10MeasStatus : 60|2@0+ (1,0) [0|3] ""  Dummy_FO
 SG_ FwdFusTrkA10ObjType : 58|3@0+ (1,0) [0|7] ""  Dummy_FO

BO_ 1297 F_Fwd_Fus_Obj_TrackA_1: 8 EOCM_F_FO
 SG_ FwdFusTrkA1RollingCnt : 7|2@0+ (1,0) [0|3] ""  Dummy_FO
 SG_ FwdFusTrkA1ObjectID : 5|6@0+ (1,0) [0|63] ""  Dummy_FO
 SG_ FwdFusTrkA1MsgIndex : 15|4@0+ (1,0) [0|15] ""  Dummy_FO
 SG_ FwdFusTrkA1LongPos : 11|12@0- (0.125,0) [-256|255.875] "m"  Dummy_FO
 SG_ FwdFusTrkA1RelLongVel : 31|11@0- (0.125,0) [-128|127.875] "m/s"  Dummy_FO
 SG_ FwdFusTrkA1Confidence : 36|2@0+ (1,0) [0|3] ""  Dummy_FO
 SG_ FwdFusTrkA1LatPos : 34|11@0- (0.125,0) [-128|127.875] "m"  Dummy_FO
 SG_ FwdFusTrkA1RelLatVel : 55|11@0- (0.125,0) [-128|127.875] "m/s"  Dummy_FO
 SG_ FwdFusTrkA1MeasStatus : 60|2@0+ (1,0) [0|3] ""  Dummy_FO
 SG_ FwdFusTrkA1ObjType : 58|3@0+ (1,0) [0|7] ""  Dummy_FO

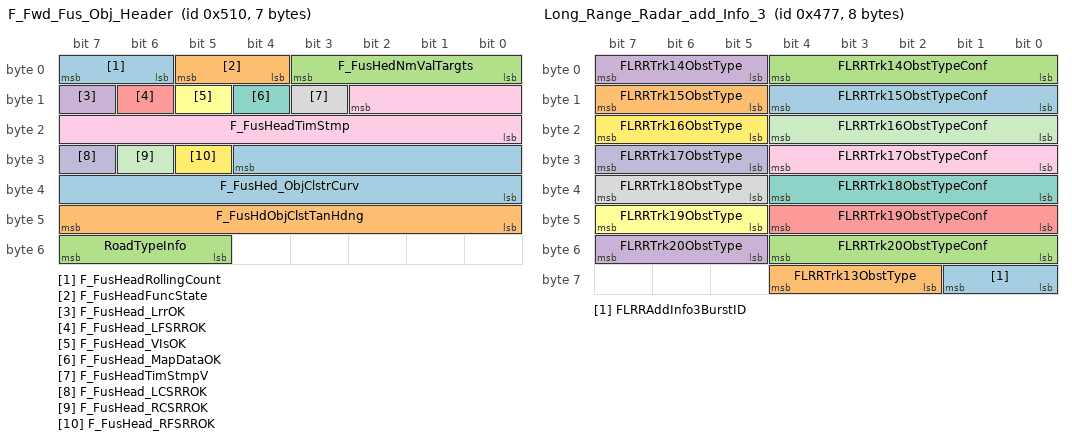
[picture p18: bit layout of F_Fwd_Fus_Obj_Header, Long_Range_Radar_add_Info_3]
BO_ 1296 F_Fwd_Fus_Obj_Header: 7 EOCM_F_FO
 SG_ F_FusHeadRollingCount : 7|2@0+ (1,0) [0|3] ""  Dummy_FO
 SG_ F_FusHeadFuncState : 5|2@0+ (1,0) [0|3] ""  Dummy_FO
 SG_ F_FusHedNmValTargts : 3|4@0+ (1,0) [0|15] ""  Dummy_FO
 SG_ F_FusHead_LrrOK : 15|1@0+ (1,0) [0|1] ""  Dummy_FO
 SG_ F_FusHead_LFSRROK : 14|1@0+ (1,0) [0|1] ""  Dummy_FO
 SG_ F_FusHead_VIsOK : 13|1@0+ (1,0) [0|1] ""  Dummy_FO
 SG_ F_FusHead_MapDataOK : 12|1@0+ (1,0) [0|1] ""  Dummy_FO
 SG_ F_FusHeadTimStmpV : 11|1@0+ (1,0) [0|1] ""  Dummy_FO
 SG_ F_FusHeadTimStmp : 10|11@0+ (1,0) [0|2047] "ms"  Dummy_FO
 SG_ F_FusHead_LCSRROK : 31|1@0+ (1,0) [0|1] ""  Dummy_FO
 SG_ F_FusHead_RCSRROK : 30|1@0+ (1,0) [0|1] ""  Dummy_FO
 SG_ F_FusHead_RFSRROK : 29|1@0+ (1,0) [0|1] ""  Dummy_FO
 SG_ F_FusHed_ObjClstrCurv : 28|13@0- (5E-005,0) [-0.2048|0.20475] "1/m"  Dummy_FO
 SG_ F_FusHdObjClstTanHdng : 47|8@0- (0.002,0) [-0.256|0.254] "m/m"  Dummy_FO
 SG_ RoadTypeInfo : 55|3@0+ (1,0) [0|7] ""  Dummy_FO

BO_ 257 USDT_Req_to_All_FO_ECUs: 8 TestTool_FO
 SG_ DgnInf : 7|64@0+ (1,0) [0|1.84467440737096E+019] ""  LRSRR_FO,_DOFIMU2_FO,_DOFIMU1_FO,DMS_FO,AMM_FO,EOCM2A_K2_FO,EOCM2B_IMX6_FO,EOCM2B_K2_FO,EOCM2B_K1_FO,EOCM2A_IMX6_FO,EOCM2A_K1_FO,NVS_FO,CIPM_FO,VIS2_FO,RRSRR_FO,VIS_FO,RFSRR_FO,LRR_FO,LFSRR_FO,RSRR_FO,EOCM_F_FO

BO_ 584 USDT_Req_to_6DOFIMU2_FO: 8 TestTool_FO
 SG_ DgnInf : 7|64@0+ (1,0) [0|1.84467440737096E+019] ""  _DOFIMU2_FO

BO_ 1348 UUDT_Resp_From_6DOFIMU1_FO: 8 _DOFIMU1_FO
 SG_ DgnInf : 7|64@0+ (1,0) [0|1.84467440737096E+019] ""  TestTool_FO

BO_ 1604 USDT_Resp_From_6DOFIMU1_FO: 8 _DOFIMU1_FO
 SG_ DgnInf : 7|64@0+ (1,0) [0|1.84467440737096E+019] ""  TestTool_FO

BO_ 580 USDT_Req_to_6DOFIMU1_FO: 8 TestTool_FO
 SG_ DgnInf : 7|64@0+ (1,0) [0|1.84467440737096E+019] ""  _DOFIMU1_FO

BO_ 1349 UUDT_Resp_From_DMS_FO: 8 DMS_FO
 SG_ DgnInf : 7|64@0+ (1,0) [0|1.84467440737096E+019] ""  TestTool_FO

BO_ 1605 USDT_Resp_From_DMS_FO: 8 DMS_FO
 SG_ DgnInf : 7|64@0+ (1,0) [0|1.84467440737096E+019] ""  TestTool_FO

BO_ 581 USDT_Req_to_DMS_FO: 8 TestTool_FO
 SG_ DgnInf : 7|64@0+ (1,0) [0|1.84467440737096E+019] ""  DMS_FO

BO_ 1372 UUDT_Resp_From_AMM_FO: 8 AMM_FO
 SG_ DgnInf : 7|64@0+ (1,0) [0|1.84467440737096E+019] ""  TestTool_FO

BO_ 1628 USDT_Resp_From_AMM_FO: 8 AMM_FO
 SG_ DgnInf : 7|64@0+ (1,0) [0|1.84467440737096E+019] ""  TestTool_FO

BO_ 604 USDT_Req_to_AMM_FO: 8 TestTool_FO
 SG_ DgnInf : 7|64@0+ (1,0) [0|1.84467440737096E+019] ""  AMM_FO

BO_ 1622 USDT_Resp_From_EOCM2B_IMX6_FO: 8 EOCM2B_IMX6_FO
 SG_ DgnInf : 7|64@0+ (1,0) [0|1.84467440737096E+019] ""  TestTool_FO

BO_ 1366 UUDT_Resp_From_EOCM2B_IMX6_FO: 8 EOCM2B_IMX6_FO
 SG_ DgnInf : 7|64@0+ (1,0) [0|1.84467440737096E+019] ""  TestTool_FO

BO_ 598 USDT_Req_to_EOCM2B_IMX6_FO: 8 TestTool_FO
 SG_ DgnInf : 7|64@0+ (1,0) [0|1.84467440737096E+019] ""  EOCM2B_IMX6_FO

BO_ 590 USDT_Req_to_Free_4E_FO: 8 TestTool_FO
 SG_ DgnInf : 7|64@0+ (1,0) [0|1.84467440737096E+019] "" Vector__XXX

BO_ 1338 VPDR_Debug: 8 EOCM_F_FO
 SG_ FrtRWARateDiagFA : 43|1@0+ (1,0) [0|1] ""  Dummy_FO
 SG_ FrtRWABiasDiagFA : 42|1@0+ (1,0) [0|1] ""  Dummy_FO
 SG_ HWAFrtVal : 41|1@0+ (1,0) [0|1] ""  Dummy_FO
 SG_ HWADotValFrt : 40|1@0+ (1,0) [0|1] ""  Dummy_FO
 SG_ S2VehAxRangeFA : 39|1@0+ (1,0) [0|1] ""  Dummy_FO
 SG_ S2VehAxRateFA : 38|1@0+ (1,0) [0|1] ""  Dummy_FO
 SG_ S2VehAxBiasFA : 37|1@0+ (1,0) [0|1] ""  Dummy_FO
 SG_ VehAxCompFA : 36|1@0+ (1,0) [0|1] ""  Dummy_FO
 SG_ S1VehAxVal : 35|1@0+ (1,0) [0|1] ""  Dummy_FO
 SG_ S2VehAxVal : 34|1@0+ (1,0) [0|1] ""  Dummy_FO
 SG_ FrtRWACorrFA : 33|1@0+ (1,0) [0|1] ""  Dummy_FO
 SG_ FrtRWARangeDiagFA : 32|1@0+ (1,0) [0|1] ""  Dummy_FO
 SG_ S2VehAyBiasFA : 31|1@0+ (1,0) [0|1] ""  Dummy_FO
 SG_ VehAyCompFA : 30|1@0+ (1,0) [0|1] ""  Dummy_FO
 SG_ S1VehAyVal : 29|1@0+ (1,0) [0|1] ""  Dummy_FO
 SG_ S2VehAyVal : 28|1@0+ (1,0) [0|1] ""  Dummy_FO
 SG_ VehAxCorrFA : 27|1@0+ (1,0) [0|1] ""  Dummy_FO
 SG_ S1VehAxRangeFA : 26|1@0+ (1,0) [0|1] ""  Dummy_FO
 SG_ S1VehAxRateFA : 25|1@0+ (1,0) [0|1] ""  Dummy_FO
 SG_ S1VehAxBiasFA : 24|1@0+ (1,0) [0|1] ""  Dummy_FO
 SG_ S1VehWzVal : 23|1@0+ (1,0) [0|1] ""  Dummy_FO
 SG_ S2VehWzVal : 22|1@0+ (1,0) [0|1] ""  Dummy_FO
 SG_ VehAyCorrDiagFA : 21|1@0+ (1,0) [0|1] ""  Dummy_FO
 SG_ S1VehAyRangeFA : 20|1@0+ (1,0) [0|1] ""  Dummy_FO
 SG_ S1VehAyRateFA : 19|1@0+ (1,0) [0|1] ""  Dummy_FO
 SG_ S1VehAyBiasFA : 18|1@0+ (1,0) [0|1] ""  Dummy_FO
 SG_ S2VehAyRangeFA : 17|1@0+ (1,0) [0|1] ""  Dummy_FO
 SG_ S2VehAyRateFA : 16|1@0+ (1,0) [0|1] ""  Dummy_FO
 SG_ VehWzCorrDiagFA : 15|1@0+ (1,0) [0|1] ""  Dummy_FO
 SG_ S1VehWzRangeFA : 14|1@0+ (1,0) [0|1] ""  Dummy_FO
 SG_ S1VehWzRateFA : 13|1@0+ (1,0) [0|1] ""  Dummy_FO
 SG_ S1VehWzBiasFA : 12|1@0+ (1,0) [0|1] ""  Dummy_FO
 SG_ S2VehWzRangeFA : 11|1@0+ (1,0) [0|1] ""  Dummy_FO
 SG_ S2VehWzRateFA : 10|1@0+ (1,0) [0|1] ""  Dummy_FO
 SG_ S2VehWzBiasFA : 9|1@0+ (1,0) [0|1] ""  Dummy_FO
 SG_ VehWzCompFA : 8|1@0+ (1,0) [0|1] ""  Dummy_FO
 SG_ WhlVxLFCorrDiagFA : 7|1@0+ (1,0) [0|1] ""  Dummy_FO
 SG_ WhlVxRFCorrDiagFA : 6|1@0+ (1,0) [0|1] ""  Dummy_FO
 SG_ WhlVxLRCorrDiagFA : 5|1@0+ (1,0) [0|1] ""  Dummy_FO
 SG_ WhlVxRRCorrDiagFA : 4|1@0+ (1,0) [0|1] ""  Dummy_FO
 SG_ WhlLFVal : 3|1@0+ (1,0) [0|1] ""  Dummy_FO
 SG_ WhlRFVal : 2|1@0+ (1,0) [0|1] ""  Dummy_FO
 SG_ WhlLRVal : 1|1@0+ (1,0) [0|1] ""  Dummy_FO
 SG_ WhlRRVal : 0|1@0+ (1,0) [0|1] ""  Dummy_FO

BO_ 1328 Diag_Debug1: 8 EOCM_F_FO
 SG_ AlrtWrnIndReqFP : 1|1@0+ (1,0) [0|1] ""  Dummy_FO
 SG_ AlrtWrnIndReqFA : 0|1@0+ (1,0) [0|1] ""  Dummy_FO
 SG_ ILRSRRSnsr_FP : 24|1@0+ (1,0) [0|1] ""  Dummy_FO
 SG_ ILRSRRSnsr_FA : 23|1@0+ (1,0) [0|1] ""  Dummy_FO
 SG_ ILRSRRFrehns_FA : 22|1@0+ (1,0) [0|1] ""  Dummy_FO
 SG_ VehPathEstCrvCSFP : 21|1@0+ (1,0) [0|1] ""  Dummy_FO
 SG_ VehPathEstCrvCSFA : 20|1@0+ (1,0) [0|1] ""  Dummy_FO
 SG_ VehPathWzEstCSFP : 19|1@0+ (1,0) [0|1] ""  Dummy_FO
 SG_ VehPathWzEstCSFA : 18|1@0+ (1,0) [0|1] ""  Dummy_FO
 SG_ VehPathVyEstCSFP : 17|1@0+ (1,0) [0|1] ""  Dummy_FO
 SG_ VehPathVyEstCSFA : 16|1@0+ (1,0) [0|1] ""  Dummy_FO
 SG_ VehPathVxEstCSFP : 15|1@0+ (1,0) [0|1] ""  Dummy_FO
 SG_ VehPathVxEstCSFA : 14|1@0+ (1,0) [0|1] ""  Dummy_FO
 SG_ TCPHiThrtTTCCSFP : 13|1@0+ (1,0) [0|1] ""  Dummy_FO
 SG_ TCPHiThrtTTCCSFA : 12|1@0+ (1,0) [0|1] ""  Dummy_FO
 SG_ TCPHiThrtLyCSFP : 11|1@0+ (1,0) [0|1] ""  Dummy_FO
 SG_ TCPHiThrtLyCSFA : 10|1@0+ (1,0) [0|1] ""  Dummy_FO
 SG_ TCPHiThLxVxAxCSFP : 9|1@0+ (1,0) [0|1] ""  Dummy_FO
 SG_ TCPHiThLxVxAxCSFA : 8|1@0+ (1,0) [0|1] ""  Dummy_FO
 SG_ CurSetValDiagFP : 7|1@0+ (1,0) [0|1] ""  Dummy_FO
 SG_ CurSetValDiagFA : 6|1@0+ (1,0) [0|1] ""  Dummy_FO
 SG_ CrsAltDvrSlTpDiagFP : 5|1@0+ (1,0) [0|1] ""  Dummy_FO
 SG_ CrsAltDvrSlTpDiagFA : 4|1@0+ (1,0) [0|1] ""  Dummy_FO
 SG_ FCAStatDiagFP : 3|1@0+ (1,0) [0|1] ""  Dummy_FO
 SG_ FCAStatDiagFA : 2|1@0+ (1,0) [0|1] ""  Dummy_FO
 SG_ RVBBrkCtrlStFP : 62|1@0+ (1,0) [0|1] ""  Dummy_FO
 SG_ RVBBrkCtrlStFA : 61|1@0+ (1,0) [0|1] ""  Dummy_FO
 SG_ RVBOpStFP : 60|1@0+ (1,0) [0|1] ""  Dummy_FO
 SG_ RVBOpStFA : 59|1@0+ (1,0) [0|1] ""  Dummy_FO
 SG_ RVBBrkCtrlAccFP : 58|1@0+ (1,0) [0|1] ""  Dummy_FO
 SG_ RVBBrkCtrlAccFA : 57|1@0+ (1,0) [0|1] ""  Dummy_FO
 SG_ RVBAxlTrqRqFP : 56|1@0+ (1,0) [0|1] ""  Dummy_FO
 SG_ RVBAxlTrqRqFA : 55|1@0+ (1,0) [0|1] ""  Dummy_FO
 SG_ TVRUPATTCFP : 54|1@0+ (1,0) [0|1] ""  Dummy_FO
 SG_ TVRUPATTCFA : 53|1@0+ (1,0) [0|1] ""  Dummy_FO
 SG_ TVRHiThrtObjIDFP : 52|1@0+ (1,0) [0|1] ""  Dummy_FO
 SG_ TVRHiThrtObjIDFA : 51|1@0+ (1,0) [0|1] ""  Dummy_FO
 SG_ TVRHiThrtTTCFP : 50|1@0+ (1,0) [0|1] ""  Dummy_FO
 SG_ TVRHiThrtTTCFA : 49|1@0+ (1,0) [0|1] ""  Dummy_FO
 SG_ TVRHiThrtLxFP : 48|1@0+ (1,0) [0|1] ""  Dummy_FO
 SG_ TVRHiThrtLxFA : 47|1@0+ (1,0) [0|1] ""  Dummy_FO
 SG_ TVRHiThrtLyFP : 46|1@0+ (1,0) [0|1] ""  Dummy_FO
 SG_ TVRHiThrtLyFA : 45|1@0+ (1,0) [0|1] ""  Dummy_FO
 SG_ ROFFuncStFP : 44|1@0+ (1,0) [0|1] ""  Dummy_FO
 SG_ ROFFuncStFA : 43|1@0+ (1,0) [0|1] ""  Dummy_FO
 SG_ ROFObjIDFP : 42|1@0+ (1,0) [0|1] ""  Dummy_FO
 SG_ ROFObjIDFA : 41|1@0+ (1,0) [0|1] ""  Dummy_FO
 SG_ ROFLatPstnVelRatFP : 40|1@0+ (1,0) [0|1] ""  Dummy_FO
 SG_ ROFLatPstnVelRatFA : 39|1@0+ (1,0) [0|1] ""  Dummy_FO
 SG_ ROFLonPstnVelFP : 38|1@0+ (1,0) [0|1] ""  Dummy_FO
 SG_ ROFLonPstnVelFA : 37|1@0+ (1,0) [0|1] ""  Dummy_FO
 SG_ ROFRltvLatVelDiagFP : 36|1@0+ (1,0) [0|1] ""  Dummy_FO
 SG_ ROFRltvLatVelDiagFA : 35|1@0+ (1,0) [0|1] ""  Dummy_FO
 SG_ ROFRltvLatPstnDiagFP : 34|1@0+ (1,0) [0|1] ""  Dummy_FO
 SG_ ROFRltvLatPstnDiagFA : 33|1@0+ (1,0) [0|1] ""  Dummy_FO
 SG_ ROFNrRltvLonPstnFP : 32|1@0+ (1,0) [0|1] ""  Dummy_FO
 SG_ ROFNrRltvLonPstnFA : 31|1@0+ (1,0) [0|1] ""  Dummy_FO
 SG_ ROFLonPstnVelRatFP : 30|1@0+ (1,0) [0|1] ""  Dummy_FO
 SG_ ROFLonPstnVelRatFA : 29|1@0+ (1,0) [0|1] ""  Dummy_FO
 SG_ ROFConfDiagFP : 28|1@0+ (1,0) [0|1] ""  Dummy_FO
 SG_ ROFConfDiagFA : 27|1@0+ (1,0) [0|1] ""  Dummy_FO
 SG_ ROFRltvLnDiagFP : 26|1@0+ (1,0) [0|1] ""  Dummy_FO
 SG_ ROFRltvLnDiagFA : 25|1@0+ (1,0) [0|1] ""  Dummy_FO

BO_ 1335 Diag_Debug3: 8 EOCM_F_FO
 SG_ BrkSysCmdAxDiagFPQ : 63|1@0+ (1,0) [0|1] ""  Dummy_FO
 SG_ BrkSysCmdAxDiagFAQ : 62|1@0+ (1,0) [0|1] ""  Dummy_FO
 SG_ AxleTorqReqDiagFPQ : 61|1@0+ (1,0) [0|1] ""  Dummy_FO
 SG_ AxleTorqReqDiagFAQ : 60|1@0+ (1,0) [0|1] ""  Dummy_FO
 SG_ AutoBrkTypeDiagFPQ : 59|1@0+ (1,0) [0|1] ""  Dummy_FO
 SG_ AutoBrkTypeDiagFAQ : 58|1@0+ (1,0) [0|1] ""  Dummy_FO
 SG_ TCPHiThrtTTCFPQ : 57|1@0+ (1,0) [0|1] ""  Dummy_FO
 SG_ TCPHiThrtTTCFAQ : 56|1@0+ (1,0) [0|1] ""  Dummy_FO
 SG_ TCPHiThrtTmpMemFPQ : 55|1@0+ (1,0) [0|1] ""  Dummy_FO
 SG_ TCPHiThrtTmpMemFAQ : 54|1@0+ (1,0) [0|1] ""  Dummy_FO
 SG_ TCPHiThrtLxVxAxFPQ : 53|1@0+ (1,0) [0|1] ""  Dummy_FO
 SG_ TCPHiThrtLxVxAxFAQ : 52|1@0+ (1,0) [0|1] ""  Dummy_FO
 SG_ TCPHiThrtVyFPQ : 51|1@0+ (1,0) [0|1] ""  Dummy_FO
 SG_ TCPHiThrtVyFAQ : 50|1@0+ (1,0) [0|1] ""  Dummy_FO
 SG_ TCPHiThrtLyFPQ : 49|1@0+ (1,0) [0|1] ""  Dummy_FO
 SG_ TCPHiThrtLyFAQ : 48|1@0+ (1,0) [0|1] ""  Dummy_FO
 SG_ TCPHiThrtConPriFPQ : 47|1@0+ (1,0) [0|1] ""  Dummy_FO
 SG_ TCPHiThrtConPriFAQ : 46|1@0+ (1,0) [0|1] ""  Dummy_FO
 SG_ TCPHiThrtCJLFPQ : 45|1@0+ (1,0) [0|1] ""  Dummy_FO
 SG_ TCPHiThrtCJLFAQ : 44|1@0+ (1,0) [0|1] ""  Dummy_FO
 SG_ TCPDynPropDiagFPQ : 43|1@0+ (1,0) [0|1] ""  Dummy_FO
 SG_ TCPDynPropDiagFAQ : 42|1@0+ (1,0) [0|1] ""  Dummy_FO
 SG_ FOFRdTypInfoFPQ : 41|1@0+ (1,0) [0|1] ""  Dummy_FO
 SG_ FOFRdTypInfoFAQ : 40|1@0+ (1,0) [0|1] ""  Dummy_FO
 SG_ FOFRltvLnDiagFPQ : 39|1@0+ (1,0) [0|1] ""  Dummy_FO
 SG_ FOFRltvLnDiagFAQ : 38|1@0+ (1,0) [0|1] ""  Dummy_FO
 SG_ FOFNumCycDiagFPQ : 37|1@0+ (1,0) [0|1] ""  Dummy_FO
 SG_ FOFNumCycDiagFAQ : 36|1@0+ (1,0) [0|1] ""  Dummy_FO
 SG_ FOFNumFusCyclsFPQ : 35|1@0+ (1,0) [0|1] ""  Dummy_FO
 SG_ FOFNumFusCyclsFAQ : 34|1@0+ (1,0) [0|1] ""  Dummy_FO
 SG_ FOFNrRltvLonPstnFPQ : 33|1@0+ (1,0) [0|1] ""  Dummy_FO
 SG_ FOFNrRltvLonPstnFAQ : 32|1@0+ (1,0) [0|1] ""  Dummy_FO
 SG_ FOFLonVelAccRatFPQ : 31|1@0+ (1,0) [0|1] ""  Dummy_FO
 SG_ FOFLonVelAccRatFAQ : 30|1@0+ (1,0) [0|1] ""  Dummy_FO
 SG_ FOFLonPstnVelRatFPQ : 29|1@0+ (1,0) [0|1] ""  Dummy_FO
 SG_ FOFLonPstnVelRatFAQ : 28|1@0+ (1,0) [0|1] ""  Dummy_FO
 SG_ FOFLonPosVelAccFPQ : 27|1@0+ (1,0) [0|1] ""  Dummy_FO
 SG_ FOFLonPosVelAccFAQ : 26|1@0+ (1,0) [0|1] ""  Dummy_FO
 SG_ FOFLatVelDiagFPQ : 25|1@0+ (1,0) [0|1] ""  Dummy_FO
 SG_ FOFLatVelDiagFAQ : 24|1@0+ (1,0) [0|1] ""  Dummy_FO
 SG_ FOFLatPstnDiagFPQ : 23|1@0+ (1,0) [0|1] ""  Dummy_FO
 SG_ FOFLatPstnDiagFAQ : 22|1@0+ (1,0) [0|1] ""  Dummy_FO
 SG_ FOFConfDiagFPQ : 21|1@0+ (1,0) [0|1] ""  Dummy_FO
 SG_ FOFConfDiagFAQ : 20|1@0+ (1,0) [0|1] ""  Dummy_FO
 SG_ ILFOvrlpRtlChk_FAQ : 19|1@0+ (1,0) [0|1] ""  Dummy_FO
 SG_ IRFOvrlpRtlChk_FAQ : 18|1@0+ (1,0) [0|1] ""  Dummy_FO
 SG_ LRROvrlpRtlChk_FAQ : 17|1@0+ (1,0) [0|1] ""  Dummy_FO
 SG_ VISOvrlpRtlChk_FAQ : 16|1@0+ (1,0) [0|1] ""  Dummy_FO
 SG_ VISAlign_FAQ : 15|1@0+ (1,0) [0|1] ""  Dummy_FO
 SG_ VISSnsr_FAQ : 14|1@0+ (1,0) [0|1] ""  Dummy_FO
 SG_ VISSnsr_FPQ : 13|1@0+ (1,0) [0|1] ""  Dummy_FO
 SG_ VISFrshns_FAQ : 12|1@0+ (1,0) [0|1] ""  Dummy_FO
 SG_ LRRAlign_FAQ : 11|1@0+ (1,0) [0|1] ""  Dummy_FO
 SG_ LRRFrshns_FAQ : 10|1@0+ (1,0) [0|1] ""  Dummy_FO
 SG_ LRRSnsr_FAQ : 9|1@0+ (1,0) [0|1] ""  Dummy_FO
 SG_ LRRSnsr_FPQ : 8|1@0+ (1,0) [0|1] ""  Dummy_FO
 SG_ IRFSRRAlign_FAQ : 7|1@0+ (1,0) [0|1] ""  Dummy_FO
 SG_ IRFSRRFrehns_FAQ : 6|1@0+ (1,0) [0|1] ""  Dummy_FO
 SG_ IRFSRRSnsr_FAQ : 5|1@0+ (1,0) [0|1] ""  Dummy_FO
 SG_ IRFSRRSnsr_FPQ : 4|1@0+ (1,0) [0|1] ""  Dummy_FO
 SG_ ILFSRRSnsr_FPQ : 3|1@0+ (1,0) [0|1] ""  Dummy_FO
 SG_ ILFSRRSnsr_FAQ : 2|1@0+ (1,0) [0|1] ""  Dummy_FO
 SG_ ILFSRRFrshns_FAQ : 1|1@0+ (1,0) [0|1] ""  Dummy_FO
 SG_ ILFSRRAlign_FAQ : 0|1@0+ (1,0) [0|1] ""  Dummy_FO

BO_ 1331 Diag_Debug2: 8 EOCM_F_FO
 SG_ TCPHiThrtTmpMemFP : 63|1@0+ (1,0) [0|1] ""  Dummy_FO
 SG_ TCPHiThrtTmpMemFA : 62|1@0+ (1,0) [0|1] ""  Dummy_FO
 SG_ TCPHiThrtConPriFP : 61|1@0+ (1,0) [0|1] ""  Dummy_FO
 SG_ TCPHiThrtConPriFA : 60|1@0+ (1,0) [0|1] ""  Dummy_FO
 SG_ TCPHiThrtCJLFP : 59|1@0+ (1,0) [0|1] ""  Dummy_FO
 SG_ TCPHiThrtTTCFP : 58|1@0+ (1,0) [0|1] ""  Dummy_FO
 SG_ TCPHiThrtTTCFA : 57|1@0+ (1,0) [0|1] ""  Dummy_FO
 SG_ TCPHiThrtVyFP : 56|1@0+ (1,0) [0|1] ""  Dummy_FO
 SG_ TCPHiThrtVyFA : 55|1@0+ (1,0) [0|1] ""  Dummy_FO
 SG_ TCPHiThrtLyFP : 54|1@0+ (1,0) [0|1] ""  Dummy_FO
 SG_ TCPHiThrtLyFA : 53|1@0+ (1,0) [0|1] ""  Dummy_FO
 SG_ TCPHiThrtLxVxAxFP : 52|1@0+ (1,0) [0|1] ""  Dummy_FO
 SG_ TCPHiThrtLxVxAxFA : 51|1@0+ (1,0) [0|1] ""  Dummy_FO
 SG_ FOFRdTypInfoFP : 50|1@0+ (1,0) [0|1] ""  Dummy_FO
 SG_ FOFRdTypInfoFA : 49|1@0+ (1,0) [0|1] ""  Dummy_FO
 SG_ AutoBrkTypeDiagFA : 48|1@0+ (1,0) [0|1] ""  Dummy_FO
 SG_ BrkSysCmdAxDiagFP : 47|1@0+ (1,0) [0|1] ""  Dummy_FO
 SG_ BrkSysCmdAxDiagFA : 46|1@0+ (1,0) [0|1] ""  Dummy_FO
 SG_ AxleTorqReqDiagFP : 45|1@0+ (1,0) [0|1] ""  Dummy_FO
 SG_ AxleTorqReqDiagFA : 44|1@0+ (1,0) [0|1] ""  Dummy_FO
 SG_ TCPDynPropDiagFP : 43|1@0+ (1,0) [0|1] ""  Dummy_FO
 SG_ TCPDynPropDiagFA : 42|1@0+ (1,0) [0|1] ""  Dummy_FO
 SG_ TCPHiThrtCJLFA : 41|1@0+ (1,0) [0|1] ""  Dummy_FO
 SG_ FOFNumFusCyclsFP : 40|1@0+ (1,0) [0|1] ""  Dummy_FO
 SG_ AutoBrkTypeDiagFP : 39|1@0+ (1,0) [0|1] ""  Dummy_FO
 SG_ FOFNumFusCyclsFA : 38|1@0+ (1,0) [0|1] ""  Dummy_FO
 SG_ FOFLatVelDiagFP : 37|1@0+ (1,0) [0|1] ""  Dummy_FO
 SG_ FOFLatVelDiagFA : 36|1@0+ (1,0) [0|1] ""  Dummy_FO
 SG_ FOFLatPstnDiagFP : 35|1@0+ (1,0) [0|1] ""  Dummy_FO
 SG_ FOFLatPstnDiagFA : 34|1@0+ (1,0) [0|1] ""  Dummy_FO
 SG_ FOFNumCycDiagFP : 33|1@0+ (1,0) [0|1] ""  Dummy_FO
 SG_ FOFNumCycDiagFA : 32|1@0+ (1,0) [0|1] ""  Dummy_FO
 SG_ FOFRltvLnDiagFP : 31|1@0+ (1,0) [0|1] ""  Dummy_FO
 SG_ FOFRltvLnDiagFA : 30|1@0+ (1,0) [0|1] ""  Dummy_FO
 SG_ FOFConfDiagFP : 29|1@0+ (1,0) [0|1] ""  Dummy_FO
 SG_ FOFConfDiagFA : 28|1@0+ (1,0) [0|1] ""  Dummy_FO
 SG_ FOFLonVelAccRatFP : 27|1@0+ (1,0) [0|1] ""  Dummy_FO
 SG_ FOFLonVelAccRatFA : 26|1@0+ (1,0) [0|1] ""  Dummy_FO
 SG_ FOFLonPstnVelRatFP : 25|1@0+ (1,0) [0|1] ""  Dummy_FO
 SG_ FOFLonPstnVelRatFA : 24|1@0+ (1,0) [0|1] ""  Dummy_FO
 SG_ FOFNrRltvLonPstnFP : 23|1@0+ (1,0) [0|1] ""  Dummy_FO
 SG_ FOFNrRltvLonPstnFA : 22|1@0+ (1,0) [0|1] ""  Dummy_FO
 SG_ FOFLonPosVelAccFP : 21|1@0+ (1,0) [0|1] ""  Dummy_FO
 SG_ FOFLonPosVelAccFA : 20|1@0+ (1,0) [0|1] ""  Dummy_FO
 SG_ VISOvrlpRtlChk_FA : 19|1@0+ (1,0) [0|1] ""  Dummy_FO
 SG_ LRROvrlpRtlChk_FA : 18|1@0+ (1,0) [0|1] ""  Dummy_FO
 SG_ IRFOvrlpRtlChk_FA : 17|1@0+ (1,0) [0|1] ""  Dummy_FO
 SG_ ILFOvrlpRtlChk_FA : 16|1@0+ (1,0) [0|1] ""  Dummy_FO
 SG_ VISAlign_FA : 15|1@0+ (1,0) [0|1] ""  Dummy_FO
 SG_ VISFrshns_FA : 14|1@0+ (1,0) [0|1] ""  Dummy_FO
 SG_ VISSnsr_FP : 13|1@0+ (1,0) [0|1] ""  Dummy_FO
 SG_ VISSnsr_FA : 12|1@0+ (1,0) [0|1] ""  Dummy_FO
 SG_ LRRAlign_FA : 11|1@0+ (1,0) [0|1] ""  Dummy_FO
 SG_ LRRFrshns_FA : 10|1@0+ (1,0) [0|1] ""  Dummy_FO
 SG_ LRRSnsr_FP : 9|1@0+ (1,0) [0|1] ""  Dummy_FO
 SG_ LRRSnsr_FA : 8|1@0+ (1,0) [0|1] ""  Dummy_FO
 SG_ IRFSRRAlign_FA : 7|1@0+ (1,0) [0|1] ""  Dummy_FO
 SG_ IRFSRRFrehns_FA : 6|1@0+ (1,0) [0|1] ""  Dummy_FO
 SG_ IRFSRRSnsr_FP : 5|1@0+ (1,0) [0|1] ""  Dummy_FO
 SG_ IRFSRRSnsr_FA : 4|1@0+ (1,0) [0|1] ""  Dummy_FO
 SG_ ILFSRRAlign_FA : 3|1@0+ (1,0) [0|1] ""  Dummy_FO
 SG_ ILFSRRFrshns_FA : 2|1@0+ (1,0) [0|1] ""  Dummy_FO
 SG_ ILFSRRSnsr_FP : 1|1@0+ (1,0) [0|1] ""  Dummy_FO
 SG_ ILFSRRSnsr_FA : 0|1@0+ (1,0) [0|1] ""  Dummy_FO

BO_ 1787 AL_Test_Tool_Rsp_RFSRR: 8 RFSRR_FO
 SG_ RFSRREngRspDta : 7|64@0+ (1,0) [0|1.84467440737096E+019] ""  Dummy_FO

BO_ 1788 AL_Test_Tool_Rsp_LFSRR: 8 LFSRR_FO
 SG_ LFSRREngRspDta : 7|64@0+ (1,0) [0|1.84467440737096E+019] ""  Dummy_FO

BO_ 1790 AL_Test_Tool_Req_RFSRR: 8 Dummy_FO
 SG_ RFSRREngCmdDta : 7|64@0+ (1,0) [0|1.84467440737096E+019] ""  RFSRR_FO

BO_ 1791 AL_Test_Tool_Req_LFSRR: 8 Dummy_FO
 SG_ LFSRREngCmdDta : 7|64@0+ (1,0) [0|1.84467440737096E+019] ""  LFSRR_FO

BO_ 1786 AL_Test_Tool_Rsp_RSRR: 8 RSRR_FO
 SG_ RSRREngRspDta : 7|64@0+ (1,0) [0|1.84467440737096E+019] ""  Dummy_FO

BO_ 1789 AL_Test_Tool_Req_RSRR: 8 Dummy_FO
 SG_ RSRREngCmdDta : 7|64@0+ (1,0) [0|1.84467440737096E+019] ""  RSRR_FO

BO_ 1149 F_LRR_Azmth_Rate_Info_4: 8 LRR_FO
 SG_ FLRRTrk20AzmthRate : 50|11@0- (0.125,0) [-128|127.875] "deg/s"  EOCM_F_FO
 SG_ FLRRTrk19AzmthRate : 45|11@0- (0.125,0) [-128|127.875] "deg/s"  EOCM_F_FO
 SG_ FLRRTrk18AzmthRate : 24|11@0- (0.125,0) [-128|127.875] "deg/s"  EOCM_F_FO
 SG_ FLRRTrk17AzmthRate : 19|11@0- (0.125,0) [-128|127.875] "deg/s"  EOCM_F_FO
 SG_ FLRRTrk16AzmthRate : 14|11@0- (0.125,0) [-128|127.875] "deg/s"  EOCM_F_FO
 SG_ FLRRAzRtInf4BurstID : 1|2@0+ (1,0) [0|3] ""  EOCM_F_FO

BO_ 1148 F_LRR_Azmth_Rate_Info_3: 8 LRR_FO
 SG_ FLRRTrk15AzmthRate : 50|11@0- (0.125,0) [-128|127.875] "deg/s"  EOCM_F_FO
 SG_ FLRRTrk14AzmthRate : 45|11@0- (0.125,0) [-128|127.875] "deg/s"  EOCM_F_FO
 SG_ FLRRTrk13AzmthRate : 24|11@0- (0.125,0) [-128|127.875] "deg/s"  EOCM_F_FO
 SG_ FLRRTrk12AzmthRate : 19|11@0- (0.125,0) [-128|127.875] "deg/s"  EOCM_F_FO
 SG_ FLRRTrk11AzmthRate : 14|11@0- (0.125,0) [-128|127.875] "deg/s"  EOCM_F_FO
 SG_ FLRRAzRtInf3BurstID : 1|2@0+ (1,0) [0|3] ""  EOCM_F_FO

BO_ 1147 F_LRR_Azmth_Rate_Info_2: 8 LRR_FO
 SG_ FLRRTrk9AzmthRate : 45|11@0- (0.125,0) [-128|127.875] "deg/s"  EOCM_F_FO
 SG_ FLRRTrk8AzmthRate : 24|11@0- (0.125,0) [-128|127.875] "deg/s"  EOCM_F_FO
 SG_ FLRRTrk7AzmthRate : 19|11@0- (0.125,0) [-128|127.875] "deg/s"  EOCM_F_FO
 SG_ FLRRTrk6AzmthRate : 14|11@0- (0.125,0) [-128|127.875] "deg/s"  EOCM_F_FO
 SG_ FLRRTrk10AzmthRate : 50|11@0- (0.125,0) [-128|127.875] "deg/s"  EOCM_F_FO
 SG_ FLRRAzRtInf2BurstID : 1|2@0+ (1,0) [0|3] ""  EOCM_F_FO

BO_ 1146 F_LRR_Azmth_Rate_Info_1: 8 LRR_FO
 SG_ FLRRTrk5AzmthRate : 50|11@0- (0.125,0) [-128|127.875] "deg/s"  EOCM_F_FO
 SG_ FLRRTrk4AzmthRate : 45|11@0- (0.125,0) [-128|127.875] "deg/s"  EOCM_F_FO
 SG_ FLRRTrk3AzmthRate : 24|11@0- (0.125,0) [-128|127.875] "deg/s"  EOCM_F_FO
 SG_ FLRRTrk2AzmthRate : 19|11@0- (0.125,0) [-128|127.875] "deg/s"  EOCM_F_FO
 SG_ FLRRTrk1AzmthRate : 14|11@0- (0.125,0) [-128|127.875] "deg/s"  EOCM_F_FO
 SG_ FLRRAzRtInf1BurstID : 1|2@0+ (1,0) [0|3] ""  EOCM_F_FO

BO_ 1143 Long_Range_Radar_add_Info_3: 8 LRR_FO
 SG_ FLRRAddInfo3BurstID : 57|2@0+ (1,0) [0|3] ""  EOCM_F_FO
 SG_ FLRRTrk13ObstType : 60|3@0+ (1,0) [0|7] ""  EOCM_F_FO
 SG_ FLRRTrk20ObstTypeConf : 52|5@0+ (0.0323,0) [0|1.0013] ""  EOCM_F_FO
 SG_ FLRRTrk20ObstType : 55|3@0+ (1,0) [0|7] ""  EOCM_F_FO
 SG_ FLRRTrk19ObstTypeConf : 44|5@0+ (0.0323,0) [0|1.0013] ""  EOCM_F_FO
 SG_ FLRRTrk19ObstType : 47|3@0+ (1,0) [0|7] ""  EOCM_F_FO
 SG_ FLRRTrk18ObstTypeConf : 36|5@0+ (0.0323,0) [0|1.0013] ""  EOCM_F_FO
 SG_ FLRRTrk18ObstType : 39|3@0+ (1,0) [0|7] ""  EOCM_F_FO
 SG_ FLRRTrk17ObstTypeConf : 28|5@0+ (0.0323,0) [0|1.0013] ""  EOCM_F_FO
 SG_ FLRRTrk17ObstType : 31|3@0+ (1,0) [0|7] ""  EOCM_F_FO
 SG_ FLRRTrk16ObstTypeConf : 20|5@0+ (0.0323,0) [0|1.0013] ""  EOCM_F_FO
 SG_ FLRRTrk16ObstType : 23|3@0+ (1,0) [0|7] ""  EOCM_F_FO
 SG_ FLRRTrk15ObstTypeConf : 12|5@0+ (0.0323,0) [0|1.0013] ""  EOCM_F_FO
 SG_ FLRRTrk15ObstType : 15|3@0+ (1,0) [0|7] ""  EOCM_F_FO
 SG_ FLRRTrk14ObstTypeConf : 4|5@0+ (0.0323,0) [0|1.0013] ""  EOCM_F_FO
 SG_ FLRRTrk14ObstType : 7|3@0+ (1,0) [0|7] ""  EOCM_F_FO

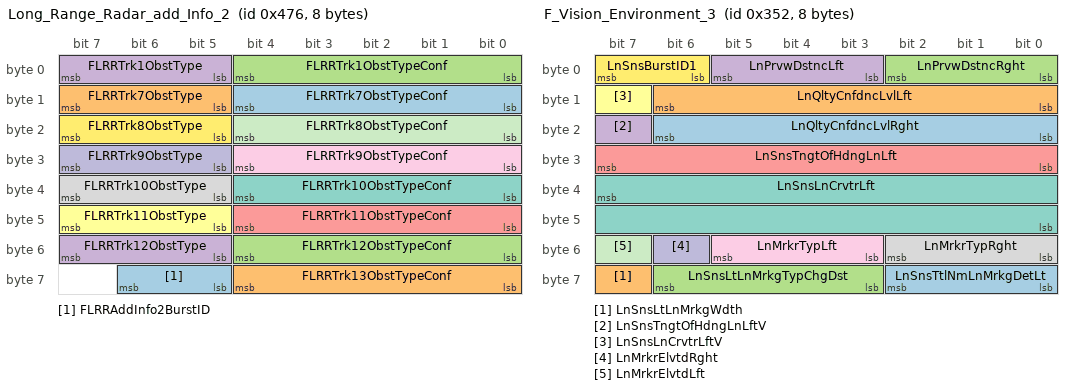
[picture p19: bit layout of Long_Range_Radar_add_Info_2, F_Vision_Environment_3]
BO_ 1142 Long_Range_Radar_add_Info_2: 8 LRR_FO
 SG_ FLRRAddInfo2BurstID : 62|2@0+ (1,0) [0|3] ""  EOCM_F_FO
 SG_ FLRRTrk13ObstTypeConf : 60|5@0+ (0.0323,0) [0|1.0013] ""  EOCM_F_FO
 SG_ FLRRTrk12ObstTypeConf : 52|5@0+ (0.0323,0) [0|1.0013] ""  EOCM_F_FO
 SG_ FLRRTrk12ObstType : 55|3@0+ (1,0) [0|7] ""  EOCM_F_FO
 SG_ FLRRTrk11ObstTypeConf : 44|5@0+ (0.0323,0) [0|1.0013] ""  EOCM_F_FO
 SG_ FLRRTrk11ObstType : 47|3@0+ (1,0) [0|7] ""  EOCM_F_FO
 SG_ FLRRTrk10ObstTypeConf : 36|5@0+ (0.0323,0) [0|1.0013] ""  EOCM_F_FO
 SG_ FLRRTrk10ObstType : 39|3@0+ (1,0) [0|7] ""  EOCM_F_FO
 SG_ FLRRTrk9ObstTypeConf : 28|5@0+ (0.0323,0) [0|1.0013] ""  EOCM_F_FO
 SG_ FLRRTrk9ObstType : 31|3@0+ (1,0) [0|7] ""  EOCM_F_FO
 SG_ FLRRTrk8ObstTypeConf : 20|5@0+ (0.0323,0) [0|1.0013] ""  EOCM_F_FO
 SG_ FLRRTrk8ObstType : 23|3@0+ (1,0) [0|7] ""  EOCM_F_FO
 SG_ FLRRTrk7ObstTypeConf : 12|5@0+ (0.0323,0) [0|1.0013] ""  EOCM_F_FO
 SG_ FLRRTrk7ObstType : 15|3@0+ (1,0) [0|7] ""  EOCM_F_FO
 SG_ FLRRTrk1ObstTypeConf : 4|5@0+ (0.0323,0) [0|1.0013] ""  EOCM_F_FO
 SG_ FLRRTrk1ObstType : 7|3@0+ (1,0) [0|7] ""  EOCM_F_FO

BO_ 851 F_Vision_Environment_4: 8 VIS_FO
 SG_ LnMrkg3LnPrvwDst : 45|4@0+ (10,0) [0|150] "m"  EOCM2A_IMX6_FO,EOCM2A_K2_FO,EOCM2A_K1_FO,EOCM2B_IMX6_FO,EOCM2B_K2_FO,EOCM2B_K1_FO,EOCM_F_FO
 SG_ LnSnsTtlNmLnMrkgDetRt : 4|3@0+ (1,0) [0|7] ""  EOCM2A_IMX6_FO,EOCM2A_K2_FO,EOCM2A_K1_FO,EOCM2B_IMX6_FO,EOCM2B_K2_FO,EOCM2B_K1_FO,EOCM_F_FO
 SG_ LnSnsRtLinCrsTm : 25|5@0+ (0.1,0) [0|3.1] "s"  EOCM2A_IMX6_FO,EOCM2A_K2_FO,EOCM2A_K1_FO,EOCM2B_IMX6_FO,EOCM2B_K2_FO,EOCM2B_K1_FO,EOCM_F_FO
 SG_ LnSnsNumPrlLnsDetRt : 33|3@0+ (1,0) [0|7] ""  EOCM2A_IMX6_FO,EOCM2A_K2_FO,EOCM2A_K1_FO,EOCM2B_IMX6_FO,EOCM2B_K2_FO,EOCM2B_K1_FO,EOCM_F_FO
 SG_ LnSnsNumPrlLnsDetLt : 36|3@0+ (1,0) [0|7] ""  EOCM2A_IMX6_FO,EOCM2A_K2_FO,EOCM2A_K1_FO,EOCM2B_IMX6_FO,EOCM2B_K2_FO,EOCM2B_K1_FO,EOCM_F_FO
 SG_ LnSnsCrvtGrdntLftV : 31|1@0+ (1,0) [0|1] ""  EOCM2A_IMX6_FO,EOCM2A_K2_FO,EOCM2A_K1_FO,EOCM2B_IMX6_FO,EOCM2B_K2_FO,EOCM2B_K1_FO,EOCM_F_FO
 SG_ LnSnsLtLinCrsTm : 30|5@0+ (0.1,0) [0|3.1] "s"  EOCM2A_IMX6_FO,EOCM2A_K2_FO,EOCM2A_K1_FO,EOCM2B_IMX6_FO,EOCM2B_K2_FO,EOCM2B_K1_FO,EOCM_F_FO
 SG_ LnMrkg4LnPrvwDst : 50|4@0+ (10,0) [0|150] "m"  EOCM2A_IMX6_FO,EOCM2A_K2_FO,EOCM2A_K1_FO,EOCM2B_IMX6_FO,EOCM2B_K2_FO,EOCM2B_K1_FO,EOCM_F_FO
 SG_ LnMrkg4LnMrkgTypChgDst : 61|4@0+ (10,0) [0|150] "m"  EOCM2A_IMX6_FO,EOCM2A_K2_FO,EOCM2A_K1_FO,EOCM2B_IMX6_FO,EOCM2B_K2_FO,EOCM2B_K1_FO,EOCM_F_FO
 SG_ LnMrkg3LnMrkgTypChgDst : 40|4@0+ (10,0) [0|150] "m"  EOCM2A_IMX6_FO,EOCM2A_K2_FO,EOCM2A_K1_FO,EOCM2B_IMX6_FO,EOCM2B_K2_FO,EOCM2B_K1_FO,EOCM_F_FO
 SG_ LnMrkg4LnMrkgWdth : 62|1@0+ (1,0) [0|1] ""  EOCM2A_IMX6_FO,EOCM2A_K2_FO,EOCM2A_K1_FO,EOCM2B_IMX6_FO,EOCM2B_K2_FO,EOCM2B_K1_FO,EOCM_F_FO
 SG_ LnMrkg4LnMarkrElvtd : 51|1@0+ (1,0) [0|1] ""  EOCM2A_IMX6_FO,EOCM2A_K2_FO,EOCM2A_K1_FO,EOCM2B_IMX6_FO,EOCM2B_K2_FO,EOCM2B_K1_FO,EOCM_F_FO
 SG_ LnMrkg4AnchrLnLin : 57|1@0+ (1,0) [0|1] ""  EOCM2A_IMX6_FO,EOCM2A_K2_FO,EOCM2A_K1_FO,EOCM2B_IMX6_FO,EOCM2B_K2_FO,EOCM2B_K1_FO,EOCM_F_FO
 SG_ LnMrkg3LnMrkgWdth : 41|1@0+ (1,0) [0|1] ""  EOCM2A_IMX6_FO,EOCM2A_K2_FO,EOCM2A_K1_FO,EOCM2B_IMX6_FO,EOCM2B_K2_FO,EOCM2B_K1_FO,EOCM_F_FO
 SG_ LnMrkg3LnMarkrElvtd : 46|1@0+ (1,0) [0|1] ""  EOCM2A_IMX6_FO,EOCM2A_K2_FO,EOCM2A_K1_FO,EOCM2B_IMX6_FO,EOCM2B_K2_FO,EOCM2B_K1_FO,EOCM_F_FO
 SG_ LnMrkg3AnchrLnLin : 52|1@0+ (1,0) [0|1] ""  EOCM2A_IMX6_FO,EOCM2A_K2_FO,EOCM2A_K1_FO,EOCM2B_IMX6_FO,EOCM2B_K2_FO,EOCM2B_K1_FO,EOCM_F_FO
 SG_ LnSnsBurstID2 : 1|2@0+ (1,0) [0|3] ""  EOCM2A_IMX6_FO,EOCM2A_K2_FO,EOCM2A_K1_FO,EOCM2B_IMX6_FO,EOCM2B_K2_FO,EOCM2B_K1_FO,EOCM_F_FO
 SG_ LnSnsCrvtGrdntLft : 15|16@0- (5.96E-008,0) [-0.0019529728|0.0019529132] "1/rad/s"  EOCM2A_IMX6_FO,EOCM2A_K2_FO,EOCM2A_K1_FO,EOCM2B_IMX6_FO,EOCM2B_K2_FO,EOCM2B_K1_FO,EOCM_F_FO

BO_ 597 USDT_Req_to_VIS2_FO: 8 TestTool_FO
 SG_ DgnInf : 7|64@0+ (1,0) [0|1.84467440737096E+019] ""  CIPM_FO,VIS2_FO

BO_ 1204 RR_SRR_Object_Track4: 8 RRSRR_FO
 SG_ RRSrrTrkRawAzimuth4 : 61|6@0- (1,0) [-32|31] "deg"  EOCM_F_FO
 SG_ RRSrrTrkRRate4 : 18|11@0- (0.125,0) [-128|127.875] "m/s"  EOCM_F_FO
 SG_ RRSrrTrkRange4 : 2|11@0+ (0.02,0) [0|40.94] "m"  EOCM_F_FO
 SG_ RRSrrTrkObsRange4 : 53|6@0- (0.02,0) [-0.64|0.62] "m"  EOCM_F_FO
 SG_ RRSrrTrkObjID4 : 39|5@0+ (1,0) [0|31] ""  EOCM_F_FO
 SG_ RRSrrTrkObjElevation4 : 20|2@0+ (1,0) [0|3] ""  EOCM_F_FO
 SG_ RRSrrTrkMeasStatus4 : 55|2@0+ (1,0) [0|3] ""  EOCM_F_FO
 SG_ RRSrrTrkDynamProp4 : 23|3@0+ (1,0) [0|7] ""  EOCM_F_FO
 SG_ RRSrrTrkAzimuth4 : 34|11@0- (0.125,0) [-128|127.875] "deg"  EOCM_F_FO
 SG_ RRSrrBurstID4 : 63|2@0+ (1,0) [0|3] ""  EOCM_F_FO

BO_ 1203 RR_SRR_Object_Track3: 8 RRSRR_FO
 SG_ RRSrrTrkRawAzimuth3 : 61|6@0- (1,0) [-32|31] "deg"  EOCM_F_FO
 SG_ RRSrrTrkRRate3 : 18|11@0- (0.125,0) [-128|127.875] "m/s"  EOCM_F_FO
 SG_ RRSrrTrkRange3 : 2|11@0+ (0.02,0) [0|40.94] "m"  EOCM_F_FO
 SG_ RRSrrTrkObsRange3 : 53|6@0- (0.02,0) [-0.64|0.62] "m"  EOCM_F_FO
 SG_ RRSrrTrkObjID3 : 39|5@0+ (1,0) [0|31] ""  EOCM_F_FO
 SG_ RRSrrTrkObjElevation3 : 20|2@0+ (1,0) [0|3] ""  EOCM_F_FO
 SG_ RRSrrTrkMeasStatus3 : 55|2@0+ (1,0) [0|3] ""  EOCM_F_FO
 SG_ RRSrrTrkDynamProp3 : 23|3@0+ (1,0) [0|7] ""  EOCM_F_FO
 SG_ RRSrrTrkAzimuth3 : 34|11@0- (0.125,0) [-128|127.875] "deg"  EOCM_F_FO
 SG_ RRSrrBurstID3 : 63|2@0+ (1,0) [0|3] ""  EOCM_F_FO

BO_ 1202 RR_SRR_Object_Track2: 8 RRSRR_FO
 SG_ RRSrrBurstID2 : 63|2@0+ (1,0) [0|3] ""  EOCM_F_FO
 SG_ RRSrrTrkRawAzimuth2 : 61|6@0- (1,0) [-32|31] "deg"  EOCM_F_FO
 SG_ RRSrrTrkRRate2 : 18|11@0- (0.125,0) [-128|127.875] "m/s"  EOCM_F_FO
 SG_ RRSrrTrkRange2 : 2|11@0+ (0.02,0) [0|40.94] "m"  EOCM_F_FO
 SG_ RRSrrTrkObsRange2 : 53|6@0- (0.02,0) [-0.64|0.62] "m"  EOCM_F_FO
 SG_ RRSrrTrkObjID2 : 39|5@0+ (1,0) [0|31] ""  EOCM_F_FO
 SG_ RRSrrTrkObjElevation2 : 20|2@0+ (1,0) [0|3] ""  EOCM_F_FO
 SG_ RRSrrTrkMeasStatus2 : 55|2@0+ (1,0) [0|3] ""  EOCM_F_FO
 SG_ RRSrrTrkDynamProp2 : 23|3@0+ (1,0) [0|7] ""  EOCM_F_FO
 SG_ RRSrrTrkAzimuth2 : 34|11@0- (0.125,0) [-128|127.875] "deg"  EOCM_F_FO

BO_ 1201 RR_SRR_Object_Track1: 8 RRSRR_FO
 SG_ RRSrrBurstID1 : 63|2@0+ (1,0) [0|3] ""  EOCM_F_FO
 SG_ RRSrrTrkRawAzimuth1 : 61|6@0- (1,0) [-32|31] "deg"  EOCM_F_FO
 SG_ RRSrrTrkRRate1 : 18|11@0- (0.125,0) [-128|127.875] "m/s"  EOCM_F_FO
 SG_ RRSrrTrkRange1 : 2|11@0+ (0.02,0) [0|40.94] "m"  EOCM_F_FO
 SG_ RRSrrTrkObsRange1 : 53|6@0- (0.02,0) [-0.64|0.62] "m"  EOCM_F_FO
 SG_ RRSrrTrkObjID1 : 39|5@0+ (1,0) [0|31] ""  EOCM_F_FO
 SG_ RRSrrTrkObjElevation1 : 20|2@0+ (1,0) [0|3] ""  EOCM_F_FO
 SG_ RRSrrTrkMeasStatus1 : 55|2@0+ (1,0) [0|3] ""  EOCM_F_FO
 SG_ RRSrrTrkDynamProp1 : 23|3@0+ (1,0) [0|7] ""  EOCM_F_FO
 SG_ RRSrrTrkAzimuth1 : 34|11@0- (0.125,0) [-128|127.875] "deg"  EOCM_F_FO

BO_ 1200 RR_SRR_Object_Header: 8 RRSRR_FO
 SG_ RRSrrTimeStampV : 15|1@0+ (1,0) [0|1] ""  EOCM_F_FO
 SG_ RRSrrTimeStamp : 10|11@0+ (1,0) [0|2047] ""  EOCM_F_FO
 SG_ RRSrrRollingCnt : 1|2@0+ (1,0) [0|3] ""  EOCM_F_FO
 SG_ RRSRRNumValidTargets : 14|4@0+ (1,0) [0|15] ""  EOCM_F_FO
 SG_ RRSRRModeCmdFdbk : 4|3@0+ (1,0) [0|7] ""  EOCM_F_FO
 SG_ RRSRRVltgOutRngLo : 44|1@0+ (1,0) [0|1] ""  EOCM_F_FO
 SG_ RRSRRVltgOutRngHi : 43|1@0+ (1,0) [0|1] ""  EOCM_F_FO
 SG_ RRSRRSvcAlgnInPrcs : 38|1@0+ (1,0) [0|1] ""  EOCM_F_FO
 SG_ RRSRRSnsrBlckd : 45|1@0+ (1,0) [0|1] ""  EOCM_F_FO
 SG_ RRSRRSnstvFltPrsntInt : 24|1@0+ (1,0) [0|1] ""  EOCM_F_FO
 SG_ RRSRRPlntAlgnInProc : 37|1@0+ (1,0) [0|1] ""  EOCM_F_FO
 SG_ RRSRRMsalgnYawRt : 47|1@0+ (1,0) [0|1] ""  EOCM_F_FO
 SG_ RRSRRMsalgnYawLt : 46|1@0+ (1,0) [0|1] ""  EOCM_F_FO
 SG_ RRSRRMsalgnRllRt : 35|1@0+ (1,0) [0|1] ""  EOCM_F_FO
 SG_ RRSRRMsalgnRllLt : 34|1@0+ (1,0) [0|1] ""  EOCM_F_FO
 SG_ RRSRRMsalgnPtchUp : 32|1@0+ (1,0) [0|1] ""  EOCM_F_FO
 SG_ RRSRRMsalgnPtchDn : 33|1@0+ (1,0) [0|1] ""  EOCM_F_FO
 SG_ RRSRRInitDiagCmplt : 40|1@0+ (1,0) [0|1] ""  EOCM_F_FO
 SG_ RRSRRHWFltPrsntInt : 25|1@0+ (1,0) [0|1] ""  EOCM_F_FO
 SG_ RRSRRExtIntrfrnc : 36|1@0+ (1,0) [0|1] ""  EOCM_F_FO
 SG_ RRSRRDiagSpare : 30|1@0+ (1,0) [0|1] ""  EOCM_F_FO
 SG_ RRSRRCANSgnlSpvFld : 29|1@0+ (1,0) [0|1] ""  EOCM_F_FO
 SG_ RRSRRCANRxErr : 28|1@0+ (1,0) [0|1] ""  EOCM_F_FO
 SG_ RRSRRCANIDAddrsUnsbl : 27|1@0+ (1,0) [0|1] ""  EOCM_F_FO
 SG_ RRSRRAntTngFltPrsnt : 26|1@0+ (1,0) [0|1] ""  EOCM_F_FO
 SG_ RRSRRAmbTmpOutRngLw : 42|1@0+ (1,0) [0|1] ""  EOCM_F_FO
 SG_ RRSRRAmbTmpOutRngHi : 41|1@0+ (1,0) [0|1] ""  EOCM_F_FO
 SG_ RRSRRAlgnFltPrsnt : 39|1@0+ (1,0) [0|1] ""  EOCM_F_FO
 SG_ RRSrrBurstChecksum : 55|16@0+ (1,0) [0|65535] ""  EOCM_F_FO

BO_ 850 F_Vision_Environment_3: 8 VIS_FO
 SG_ LnSnsTtlNmLnMrkgDetLt : 58|3@0+ (1,0) [0|7] ""  EOCM2A_IMX6_FO,EOCM2A_K2_FO,EOCM2A_K1_FO,EOCM2B_IMX6_FO,EOCM2B_K2_FO,EOCM2B_K1_FO,EOCM_F_FO
 SG_ LnSnsLtLnMrkgWdth : 63|1@0+ (1,0) [0|1] ""  EOCM2A_IMX6_FO,EOCM2A_K2_FO,EOCM2A_K1_FO,EOCM2B_IMX6_FO,EOCM2B_K2_FO,EOCM2B_K1_FO,EOCM_F_FO
 SG_ LnSnsLtLnMrkgTypChgDst : 62|4@0+ (10,0) [0|150] "m"  EOCM2A_IMX6_FO,EOCM2A_K2_FO,EOCM2A_K1_FO,EOCM2B_IMX6_FO,EOCM2B_K2_FO,EOCM2B_K1_FO,EOCM_F_FO
 SG_ LnSnsTngtOfHdngLnLftV : 23|1@0+ (1,0) [0|1] ""  EOCM2A_IMX6_FO,EOCM2A_K2_FO,EOCM2A_K1_FO,EOCM2B_IMX6_FO,EOCM2B_K2_FO,EOCM2B_K1_FO,EOCM_F_FO
 SG_ LnSnsTngtOfHdngLnLft : 31|8@0- (0.002,0) [-0.256|0.254] "m/m"  EOCM2A_IMX6_FO,EOCM2A_K2_FO,EOCM2A_K1_FO,EOCM2B_IMX6_FO,EOCM2B_K2_FO,EOCM2B_K1_FO,EOCM_F_FO
 SG_ LnSnsLnCrvtrLftV : 15|1@0+ (1,0) [0|1] ""  EOCM2A_IMX6_FO,EOCM2A_K2_FO,EOCM2A_K1_FO,EOCM2B_IMX6_FO,EOCM2B_K2_FO,EOCM2B_K1_FO,EOCM_F_FO
 SG_ LnSnsLnCrvtrLft : 39|16@0- (9.53E-007,0) [-0.031227904|0.031226951] "1/m"  EOCM2A_IMX6_FO,EOCM2A_K2_FO,EOCM2A_K1_FO,EOCM2B_IMX6_FO,EOCM2B_K2_FO,EOCM2B_K1_FO,EOCM_F_FO
 SG_ LnMrkrTypRght : 50|3@0+ (1,0) [0|7] ""  EOCM2A_IMX6_FO,EOCM2A_K2_FO,EOCM2A_K1_FO,EOCM2B_IMX6_FO,EOCM2B_K2_FO,EOCM2B_K1_FO,EOCM_F_FO
 SG_ LnMrkrTypLft : 53|3@0+ (1,0) [0|7] ""  EOCM2A_IMX6_FO,EOCM2A_K2_FO,EOCM2A_K1_FO,EOCM2B_IMX6_FO,EOCM2B_K2_FO,EOCM2B_K1_FO,EOCM_F_FO
 SG_ LnMrkrElvtdRght : 54|1@0+ (1,0) [0|1] ""  EOCM2A_IMX6_FO,EOCM2A_K2_FO,EOCM2A_K1_FO,EOCM2B_IMX6_FO,EOCM2B_K2_FO,EOCM2B_K1_FO,EOCM_F_FO
 SG_ LnMrkrElvtdLft : 55|1@0+ (1,0) [0|1] ""  EOCM2A_IMX6_FO,EOCM2A_K2_FO,EOCM2A_K1_FO,EOCM2B_IMX6_FO,EOCM2B_K2_FO,EOCM2B_K1_FO,EOCM_F_FO
 SG_ LnSnsBurstID1 : 7|2@0+ (1,0) [0|3] ""  EOCM2A_IMX6_FO,EOCM2A_K2_FO,EOCM2A_K1_FO,EOCM2B_IMX6_FO,EOCM2B_K2_FO,EOCM2B_K1_FO,EOCM_F_FO
 SG_ LnQltyCnfdncLvlRght : 22|7@0+ (0.7874016,0) [0|100.0000032] "%"  EOCM2A_IMX6_FO,EOCM2A_K2_FO,EOCM2A_K1_FO,EOCM2B_IMX6_FO,EOCM2B_K2_FO,EOCM2B_K1_FO,EOCM_F_FO
 SG_ LnQltyCnfdncLvlLft : 14|7@0+ (0.7874016,0) [0|100.0000032] "%"  EOCM2A_IMX6_FO,EOCM2A_K2_FO,EOCM2A_K1_FO,EOCM2B_IMX6_FO,EOCM2B_K2_FO,EOCM2B_K1_FO,EOCM_F_FO
 SG_ LnPrvwDstncRght : 2|3@0+ (10,0) [0|70] "m"  EOCM2A_IMX6_FO,EOCM2A_K2_FO,EOCM2A_K1_FO,EOCM2B_IMX6_FO,EOCM2B_K2_FO,EOCM2B_K1_FO,EOCM_F_FO
 SG_ LnPrvwDstncLft : 5|3@0+ (10,0) [0|70] "m"  EOCM2A_IMX6_FO,EOCM2A_K2_FO,EOCM2A_K1_FO,EOCM2B_IMX6_FO,EOCM2B_K2_FO,EOCM2B_K1_FO,EOCM_F_FO

BO_ 1414 RVB_TVR_Debug2_FO: 7 EOCM_F_FO
 SG_ VBBrkCntlAccel : 45|12@0- (0.01,0) [-20.48|20.47] "m/s^2"  Dummy_FO
 SG_ VBTOSObjID : 35|6@0+ (1,0) [0|63] ""  Dummy_FO
 SG_ VBTOSTTC : 31|12@0+ (0.025,0) [0|102.375] "s"  Dummy_FO
 SG_ VBTOSLatPstn : 11|11@0- (0.125,0) [-128|127.875] "m"  Dummy_FO
 SG_ VBTOSLonPstn : 7|12@0- (0.125,0) [-256|255.875] "m"  Dummy_FO
 SG_ BMS_BattCurr : 13|14@0+ (0.1,-500) [-500|1138.3] "A"  VCU
 SG_ BMS_BattCurr_Display : 13|6@0+ (0.1,-500) [-500|500] "" TCU
